VERSION ""

NS_ :

BS_:

BU_: WCM4 WCM3 WCM2 WCM VPM VLM VKM VICM VECM VDM VCU_RTOS_ETH VCU_ENTRY_ETH VCU_AGVM_ETH VCU UVM UPM TIM TEST_TOOL_1 TCP_ETH TCP TCM TCCM SRR_SRR_ETH SRR_SRR SRR_SLR_ETH SRR_SLR SRR_RR SRR_RF_ETH SRR_RF SRR_LR_CR SRR_LF_ETH SRR_LF SIB SDM SCL SBZA_R SBZA_L SBM SAM_RR SAM_RF SAM_LR SAM_LF SAM_BH SADS RadioLow_ETH RadioLow RSI_RTOS_ETH RSI RDCM PTM PLCM PFCM PDR_ETH PDR PCM PA ODS2 ODS NVM MTCM_R MTCM_L MSM_RR MSM_P MSM_LR MSM_D MSB2 MSB1 MRCM_R MRCM_L MFC LRR_RR_ETH LRR_LR_ETH LRR_CF_ETH LRR LRL_CF_ETH LIB_48V LIB1 IPC_INT IPC_GP IPC ICS_Info ICCM HVAC_FP_R HVAC_FP_F HUD_CAN HDLM FPI_RTOS_ETH FPI FOPM FCM_LC FCM EPSb EPS_1 EPSRAb EPSRAa EPS EOCM_HC_Superset EOCM_HCP2 EOCM ELM ECP_X1 ECP_S2 ECP_S ECP_MC ECP_H3 ECP_H2 ECP_H1 ECP_E ECM EBCM DMS DEFC DCM CSM_ETH CSM_AV CSM CGM_OTA_ETH CGM BSM_MH BSM_HEV BSM BCM ARS ARB APA AOS AMP ALC AHS AHL_AFL ADIMb ADIMa ACP2_MCU

BO_ 120 Tp_SrlDat186_Data_PDU: 2680 SRR_RR
 SG_ SRRRRODPREOTk1CrvAuth : 7|16@0- (9.77e-07,0) [-0.0320143|0.0320134] "1/m" Vector__XXX
 SG_ SRRRRODPREOTk1CrvDrvtAuth : 23|16@0- (3.73e-09,0) [-0.000122225|0.000122221] "1/m2" Vector__XXX
 SG_ SRRRRODPREOTk2CrvAuth : 39|16@0- (9.77e-07,0) [-0.0320143|0.0320134] "1/m" Vector__XXX
 SG_ SRRRRODPREOTk2CrvDrvtAuth : 55|16@0- (3.73e-09,0) [-0.000122225|0.000122221] "1/m2" Vector__XXX
 SG_ SRRRRODPREOTk3CrvAuth : 71|16@0- (9.77e-07,0) [-0.0320143|0.0320134] "1/m" Vector__XXX
 SG_ SRRRRODPREOTk3CrvDrvtAuth : 87|16@0- (3.73e-09,0) [-0.000122225|0.000122221] "1/m2" Vector__XXX
 SG_ SRRRRODPVOTk10PoILgPsCAuth : 103|16@0+ (0.01,0) [0|655.35] "m^2" Vector__XXX
 SG_ SRRRRODPVOTk1PoILgPsCAuth : 119|16@0+ (0.01,0) [0|655.35] "m^2" Vector__XXX
 SG_ SRRRRODPVOTk2PoILgPsCAuth : 135|16@0+ (0.01,0) [0|655.35] "m^2" Vector__XXX
 SG_ SRRRRODPVOTk3PoILgPsCAuth : 151|16@0+ (0.01,0) [0|655.35] "m^2" Vector__XXX
 SG_ SRRRRODPVOTk4PoILgPsCAuth : 167|16@0+ (0.01,0) [0|655.35] "m^2" Vector__XXX
 SG_ SRRRRODPVOTk5PoILgPsCAuth : 183|16@0+ (0.01,0) [0|655.35] "m^2" Vector__XXX
 SG_ SRRRRODPVOTk6PoILgPsCAuth : 199|16@0+ (0.01,0) [0|655.35] "m^2" Vector__XXX
 SG_ SRRRRODPVOTk7PoILgPsCAuth : 215|16@0+ (0.01,0) [0|655.35] "m^2" Vector__XXX
 SG_ SRRRRODPVOTk8PoILgPsCAuth : 231|16@0+ (0.01,0) [0|655.35] "m^2" Vector__XXX
 SG_ SRRRRODPVOTk9PoILgPsCAuth : 247|16@0+ (0.01,0) [0|655.35] "m^2" Vector__XXX
 SG_ SRRRRODPVOTk10PoILPsCAuth : 263|14@0+ (0.01,0) [0|163.83] "m^2" Vector__XXX
 SG_ SRRRRODPVOTk1PoILPsCAuth : 265|14@0+ (0.01,0) [0|163.83] "m^2" Vector__XXX
 SG_ SRRRRODPVOTk2PoILPsCAuth : 283|14@0+ (0.01,0) [0|163.83] "m^2" Vector__XXX
 SG_ SRRRRODPVOTk3PoILPsCAuth : 301|14@0+ (0.01,0) [0|163.83] "m^2" Vector__XXX
 SG_ SRRRRODPVOTk4PoILPsCAuth : 319|14@0+ (0.01,0) [0|163.83] "m^2" Vector__XXX
 SG_ SRRRRODPVOTk5PoILPsCAuth : 321|14@0+ (0.01,0) [0|163.83] "m^2" Vector__XXX
 SG_ SRRRRODPVOTk6PoILPsCAuth : 339|14@0+ (0.01,0) [0|163.83] "m^2" Vector__XXX
 SG_ SRRRRODPVOTk7PoILPsCAuth : 357|14@0+ (0.01,0) [0|163.83] "m^2" Vector__XXX
 SG_ SRRRRODPVOTk8PoILPsCAuth : 375|14@0+ (0.01,0) [0|163.83] "m^2" Vector__XXX
 SG_ SRRRRODPVOTk9PoILPsCAuth : 377|14@0+ (0.01,0) [0|163.83] "m^2" Vector__XXX
 SG_ SRRRRODPAcqTmStmAuth : 395|11@0+ (1,0) [0|2047] "ms" Vector__XXX
 SG_ SRRRRODPIOTk10PoILgPsAuth : 400|11@0- (0.125,0) [-128|127.875] "m" Vector__XXX
 SG_ SRRRRODPIOTk1PoILgPsAuth : 421|11@0- (0.125,0) [-128|127.875] "m" Vector__XXX
 SG_ SRRRRODPIOTk2PoILgPsAuth : 426|11@0- (0.125,0) [-128|127.875] "m" Vector__XXX
 SG_ SRRRRODPIOTk3PoILgPsAuth : 447|11@0- (0.125,0) [-128|127.875] "m" Vector__XXX
 SG_ SRRRRODPIOTk4PoILgPsAuth : 452|11@0- (0.125,0) [-128|127.875] "m" Vector__XXX
 SG_ SRRRRODPIOTk5PoILgPsAuth : 457|11@0- (0.125,0) [-128|127.875] "m" Vector__XXX
 SG_ SRRRRODPIOTk6PoILgPsAuth : 478|11@0- (0.125,0) [-128|127.875] "m" Vector__XXX
 SG_ SRRRRODPIOTk7PoILgPsAuth : 483|11@0- (0.125,0) [-128|127.875] "m" Vector__XXX
 SG_ SRRRRODPIOTk8PoILgPsAuth : 488|11@0- (0.125,0) [-128|127.875] "m" Vector__XXX
 SG_ SRRRRODPIOTk9PoILgPsAuth : 509|11@0- (0.125,0) [-128|127.875] "m" Vector__XXX
 SG_ SRRRRODPPOTk1PoILgPsAuth : 514|11@0- (0.125,0) [-128|127.875] "m" Vector__XXX
 SG_ SRRRRODPPOTk2PoILgPsAuth : 535|11@0- (0.125,0) [-128|127.875] "m" Vector__XXX
 SG_ SRRRRODPPOTk3PoILgPsAuth : 540|11@0- (0.125,0) [-128|127.875] "m" Vector__XXX
 SG_ SRRRRODPPOTk4PoILgPsAuth : 545|11@0- (0.125,0) [-128|127.875] "m" Vector__XXX
 SG_ SRRRRODPPOTk5PoILgPsAuth : 566|11@0- (0.125,0) [-128|127.875] "m" Vector__XXX
 SG_ SRRRRODPREOTk1PsEndAuth : 571|11@0- (0.125,0) [-128|127.875] "m" Vector__XXX
 SG_ SRRRRODPREOTk1PsStrtAuth : 576|11@0- (0.125,0) [-128|127.875] "m" Vector__XXX
 SG_ SRRRRODPREOTk2PsEndAuth : 597|11@0- (0.125,0) [-128|127.875] "m" Vector__XXX
 SG_ SRRRRODPREOTk2PsStrtAuth : 602|11@0- (0.125,0) [-128|127.875] "m" Vector__XXX
 SG_ SRRRRODPREOTk3PsEndAuth : 623|11@0- (0.125,0) [-128|127.875] "m" Vector__XXX
 SG_ SRRRRODPREOTk3PsStrtAuth : 628|11@0- (0.125,0) [-128|127.875] "m" Vector__XXX
 SG_ SRRRRODPVOTk10PoI2LgPsAuth : 633|11@0- (0.125,0) [-128|127.875] "m" Vector__XXX
 SG_ SRRRRODPVOTk10PoILgPsAuth : 654|11@0- (0.125,0) [-128|127.875] "m" Vector__XXX
 SG_ SRRRRODPVOTk10PoILgVAuth : 659|11@0- (0.125,0) [-128|127.875] "m/s" Vector__XXX
 SG_ SRRRRODPVOTk1PoI2LgPsAuth : 664|11@0- (0.125,0) [-128|127.875] "m" Vector__XXX
 SG_ SRRRRODPVOTk1PoILgPsAuth : 685|11@0- (0.125,0) [-128|127.875] "m" Vector__XXX
 SG_ SRRRRODPVOTk1PoILgVAuth : 690|11@0- (0.125,0) [-128|127.875] "m/s" Vector__XXX
 SG_ SRRRRODPVOTk2PoI2LgPsAuth : 711|11@0- (0.125,0) [-128|127.875] "m" Vector__XXX
 SG_ SRRRRODPVOTk2PoILgPsAuth : 716|11@0- (0.125,0) [-128|127.875] "m" Vector__XXX
 SG_ SRRRRODPVOTk2PoILgVAuth : 721|11@0- (0.125,0) [-128|127.875] "m/s" Vector__XXX
 SG_ SRRRRODPVOTk3PoI2LgPsAuth : 742|11@0- (0.125,0) [-128|127.875] "m" Vector__XXX
 SG_ SRRRRODPVOTk3PoILgPsAuth : 747|11@0- (0.125,0) [-128|127.875] "m" Vector__XXX
 SG_ SRRRRODPVOTk3PoILgVAuth : 752|11@0- (0.125,0) [-128|127.875] "m/s" Vector__XXX
 SG_ SRRRRODPVOTk4PoI2LgPsAuth : 773|11@0- (0.125,0) [-128|127.875] "m" Vector__XXX
 SG_ SRRRRODPVOTk4PoILgPsAuth : 778|11@0- (0.125,0) [-128|127.875] "m" Vector__XXX
 SG_ SRRRRODPVOTk4PoILgVAuth : 799|11@0- (0.125,0) [-128|127.875] "m/s" Vector__XXX
 SG_ SRRRRODPVOTk5PoI2LgPsAuth : 804|11@0- (0.125,0) [-128|127.875] "m" Vector__XXX
 SG_ SRRRRODPVOTk5PoILgPsAuth : 809|11@0- (0.125,0) [-128|127.875] "m" Vector__XXX
 SG_ SRRRRODPVOTk5PoILgVAuth : 830|11@0- (0.125,0) [-128|127.875] "m/s" Vector__XXX
 SG_ SRRRRODPVOTk6PoI2LgPsAuth : 835|11@0- (0.125,0) [-128|127.875] "m" Vector__XXX
 SG_ SRRRRODPVOTk6PoILgPsAuth : 840|11@0- (0.125,0) [-128|127.875] "m" Vector__XXX
 SG_ SRRRRODPVOTk6PoILgVAuth : 861|11@0- (0.125,0) [-128|127.875] "m/s" Vector__XXX
 SG_ SRRRRODPVOTk7PoI2LgPsAuth : 866|11@0- (0.125,0) [-128|127.875] "m" Vector__XXX
 SG_ SRRRRODPVOTk7PoILgPsAuth : 887|11@0- (0.125,0) [-128|127.875] "m" Vector__XXX
 SG_ SRRRRODPVOTk7PoILgVAuth : 892|11@0- (0.125,0) [-128|127.875] "m/s" Vector__XXX
 SG_ SRRRRODPVOTk8PoI2LgPsAuth : 897|11@0- (0.125,0) [-128|127.875] "m" Vector__XXX
 SG_ SRRRRODPVOTk8PoILgPsAuth : 918|11@0- (0.125,0) [-128|127.875] "m" Vector__XXX
 SG_ SRRRRODPVOTk8PoILgVAuth : 923|11@0- (0.125,0) [-128|127.875] "m/s" Vector__XXX
 SG_ SRRRRODPVOTk9PoI2LgPsAuth : 928|11@0- (0.125,0) [-128|127.875] "m" Vector__XXX
 SG_ SRRRRODPVOTk9PoILgPsAuth : 949|11@0- (0.125,0) [-128|127.875] "m" Vector__XXX
 SG_ SRRRRODPVOTk9PoILgVAuth : 954|11@0- (0.125,0) [-128|127.875] "m/s" Vector__XXX
 SG_ SRRRRODPIOTk10PoILPsAuth : 975|10@0- (0.125,0) [-64|63.875] "m" Vector__XXX
 SG_ SRRRRODPIOTk1PoILPsAuth : 981|10@0- (0.125,0) [-64|63.875] "m" Vector__XXX
 SG_ SRRRRODPIOTk2PoILPsAuth : 987|10@0- (0.125,0) [-64|63.875] "m" Vector__XXX
 SG_ SRRRRODPIOTk3PoILPsAuth : 993|10@0- (0.125,0) [-64|63.875] "m" Vector__XXX
 SG_ SRRRRODPIOTk4PoILPsAuth : 1015|10@0- (0.125,0) [-64|63.875] "m" Vector__XXX
 SG_ SRRRRODPIOTk5PoILPsAuth : 1021|10@0- (0.125,0) [-64|63.875] "m" Vector__XXX
 SG_ SRRRRODPIOTk6PoILPsAuth : 1027|10@0- (0.125,0) [-64|63.875] "m" Vector__XXX
 SG_ SRRRRODPIOTk7PoILPsAuth : 1033|10@0- (0.125,0) [-64|63.875] "m" Vector__XXX
 SG_ SRRRRODPIOTk8PoILPsAuth : 1055|10@0- (0.125,0) [-64|63.875] "m" Vector__XXX
 SG_ SRRRRODPIOTk9PoILPsAuth : 1061|10@0- (0.125,0) [-64|63.875] "m" Vector__XXX
 SG_ SRRRRODPPOTk1PoILPsAuth : 1067|10@0- (0.125,0) [-64|63.875] "m" Vector__XXX
 SG_ SRRRRODPPOTk1PoILgVAuth : 1073|10@0- (0.125,0) [-64|63.875] "m/s" Vector__XXX
 SG_ SRRRRODPPOTk2PoILPsAuth : 1095|10@0- (0.125,0) [-64|63.875] "m" Vector__XXX
 SG_ SRRRRODPPOTk2PoILgVAuth : 1101|10@0- (0.125,0) [-64|63.875] "m/s" Vector__XXX
 SG_ SRRRRODPPOTk3PoILPsAuth : 1107|10@0- (0.125,0) [-64|63.875] "m" Vector__XXX
 SG_ SRRRRODPPOTk3PoILgVAuth : 1113|10@0- (0.125,0) [-64|63.875] "m/s" Vector__XXX
 SG_ SRRRRODPPOTk4PoILPsAuth : 1135|10@0- (0.125,0) [-64|63.875] "m" Vector__XXX
 SG_ SRRRRODPPOTk4PoILgVAuth : 1141|10@0- (0.125,0) [-64|63.875] "m/s" Vector__XXX
 SG_ SRRRRODPPOTk5PoILPsAuth : 1147|10@0- (0.125,0) [-64|63.875] "m" Vector__XXX
 SG_ SRRRRODPPOTk5PoILgVAuth : 1153|10@0- (0.125,0) [-64|63.875] "m/s" Vector__XXX
 SG_ SRRRRODPREOTk1HdgAuth : 1175|10@0- (0.000977,0) [-0.500224|0.499247] "rad" Vector__XXX
 SG_ SRRRRODPREOTk2HdgAuth : 1181|10@0- (0.000977,0) [-0.500224|0.499247] "rad" Vector__XXX
 SG_ SRRRRODPREOTk3HdgAuth : 1187|10@0- (0.000977,0) [-0.500224|0.499247] "rad" Vector__XXX
 SG_ SRRRRODPVOTk10PoI2LPsAuth : 1193|10@0- (0.125,0) [-64|63.875] "m" Vector__XXX
 SG_ SRRRRODPVOTk10PoILPsAuth : 1215|10@0- (0.125,0) [-64|63.875] "m" Vector__XXX
 SG_ SRRRRODPVOTk10PoILVCAuth : 1221|10@0+ (0.125,0) [0|127.875] "(m/s)^2" Vector__XXX
 SG_ SRRRRODPVOTk10PoILgVCAuth : 1227|10@0+ (0.125,0) [0|127.875] "(m/s)^2" Vector__XXX
 SG_ SRRRRODPVOTk1PoI2LPsAuth : 1233|10@0- (0.125,0) [-64|63.875] "m" Vector__XXX
 SG_ SRRRRODPVOTk1PoILPsAuth : 1255|10@0- (0.125,0) [-64|63.875] "m" Vector__XXX
 SG_ SRRRRODPVOTk1PoILVCAuth : 1261|10@0+ (0.125,0) [0|127.875] "(m/s)^2" Vector__XXX
 SG_ SRRRRODPVOTk1PoILgVCAuth : 1267|10@0+ (0.125,0) [0|127.875] "(m/s)^2" Vector__XXX
 SG_ SRRRRODPVOTk2PoI2LPsAuth : 1273|10@0- (0.125,0) [-64|63.875] "m" Vector__XXX
 SG_ SRRRRODPVOTk2PoILPsAuth : 1295|10@0- (0.125,0) [-64|63.875] "m" Vector__XXX
 SG_ SRRRRODPVOTk2PoILVCAuth : 1301|10@0+ (0.125,0) [0|127.875] "(m/s)^2" Vector__XXX
 SG_ SRRRRODPVOTk2PoILgVCAuth : 1307|10@0+ (0.125,0) [0|127.875] "(m/s)^2" Vector__XXX
 SG_ SRRRRODPVOTk3PoI2LPsAuth : 1313|10@0- (0.125,0) [-64|63.875] "m" Vector__XXX
 SG_ SRRRRODPVOTk3PoILPsAuth : 1335|10@0- (0.125,0) [-64|63.875] "m" Vector__XXX
 SG_ SRRRRODPVOTk3PoILVCAuth : 1341|10@0+ (0.125,0) [0|127.875] "(m/s)^2" Vector__XXX
 SG_ SRRRRODPVOTk3PoILgVCAuth : 1347|10@0+ (0.125,0) [0|127.875] "(m/s)^2" Vector__XXX
 SG_ SRRRRODPVOTk4PoI2LPsAuth : 1353|10@0- (0.125,0) [-64|63.875] "m" Vector__XXX
 SG_ SRRRRODPVOTk4PoILPsAuth : 1375|10@0- (0.125,0) [-64|63.875] "m" Vector__XXX
 SG_ SRRRRODPVOTk4PoILVCAuth : 1381|10@0+ (0.125,0) [0|127.875] "(m/s)^2" Vector__XXX
 SG_ SRRRRODPVOTk4PoILgVCAuth : 1387|10@0+ (0.125,0) [0|127.875] "(m/s)^2" Vector__XXX
 SG_ SRRRRODPVOTk5PoI2LPsAuth : 1393|10@0- (0.125,0) [-64|63.875] "m" Vector__XXX
 SG_ SRRRRODPVOTk5PoILPsAuth : 1415|10@0- (0.125,0) [-64|63.875] "m" Vector__XXX
 SG_ SRRRRODPVOTk5PoILVCAuth : 1421|10@0+ (0.125,0) [0|127.875] "(m/s)^2" Vector__XXX
 SG_ SRRRRODPVOTk5PoILgVCAuth : 1427|10@0+ (0.125,0) [0|127.875] "(m/s)^2" Vector__XXX
 SG_ SRRRRODPVOTk6PoI2LPsAuth : 1433|10@0- (0.125,0) [-64|63.875] "m" Vector__XXX
 SG_ SRRRRODPVOTk6PoILPsAuth : 1455|10@0- (0.125,0) [-64|63.875] "m" Vector__XXX
 SG_ SRRRRODPVOTk6PoILVCAuth : 1461|10@0+ (0.125,0) [0|127.875] "(m/s)^2" Vector__XXX
 SG_ SRRRRODPVOTk6PoILgVCAuth : 1467|10@0+ (0.125,0) [0|127.875] "(m/s)^2" Vector__XXX
 SG_ SRRRRODPVOTk7PoI2LPsAuth : 1473|10@0- (0.125,0) [-64|63.875] "m" Vector__XXX
 SG_ SRRRRODPVOTk7PoILPsAuth : 1495|10@0- (0.125,0) [-64|63.875] "m" Vector__XXX
 SG_ SRRRRODPVOTk7PoILVCAuth : 1501|10@0+ (0.125,0) [0|127.875] "(m/s)^2" Vector__XXX
 SG_ SRRRRODPVOTk7PoILgVCAuth : 1507|10@0+ (0.125,0) [0|127.875] "(m/s)^2" Vector__XXX
 SG_ SRRRRODPVOTk8PoI2LPsAuth : 1513|10@0- (0.125,0) [-64|63.875] "m" Vector__XXX
 SG_ SRRRRODPVOTk8PoILPsAuth : 1535|10@0- (0.125,0) [-64|63.875] "m" Vector__XXX
 SG_ SRRRRODPVOTk8PoILVCAuth : 1541|10@0+ (0.125,0) [0|127.875] "(m/s)^2" Vector__XXX
 SG_ SRRRRODPVOTk8PoILgVCAuth : 1547|10@0+ (0.125,0) [0|127.875] "(m/s)^2" Vector__XXX
 SG_ SRRRRODPVOTk9PoI2LPsAuth : 1553|10@0- (0.125,0) [-64|63.875] "m" Vector__XXX
 SG_ SRRRRODPVOTk9PoILPsAuth : 1575|10@0- (0.125,0) [-64|63.875] "m" Vector__XXX
 SG_ SRRRRODPVOTk9PoILVCAuth : 1581|10@0+ (0.125,0) [0|127.875] "(m/s)^2" Vector__XXX
 SG_ SRRRRODPVOTk9PoILgVCAuth : 1587|10@0+ (0.125,0) [0|127.875] "(m/s)^2" Vector__XXX
 SG_ SRRRRODPPOTk1PoILAAuth : 1593|9@0- (0.125,0) [-32|31.875] "m/s^2" Vector__XXX
 SG_ SRRRRODPPOTk1PoILVAuth : 1600|9@0- (0.125,0) [-32|31.875] "m/s" Vector__XXX
 SG_ SRRRRODPPOTk1PoILgAAuth : 1623|9@0- (0.125,0) [-32|31.875] "m/s^2" Vector__XXX
 SG_ SRRRRODPPOTk2PoILAAuth : 1630|9@0- (0.125,0) [-32|31.875] "m/s^2" Vector__XXX
 SG_ SRRRRODPPOTk2PoILVAuth : 1637|9@0- (0.125,0) [-32|31.875] "m/s" Vector__XXX
 SG_ SRRRRODPPOTk2PoILgAAuth : 1644|9@0- (0.125,0) [-32|31.875] "m/s^2" Vector__XXX
 SG_ SRRRRODPPOTk3PoILAAuth : 1651|9@0- (0.125,0) [-32|31.875] "m/s^2" Vector__XXX
 SG_ SRRRRODPPOTk3PoILVAuth : 1658|9@0- (0.125,0) [-32|31.875] "m/s" Vector__XXX
 SG_ SRRRRODPPOTk3PoILgAAuth : 1665|9@0- (0.125,0) [-32|31.875] "m/s^2" Vector__XXX
 SG_ SRRRRODPPOTk4PoILAAuth : 1672|9@0- (0.125,0) [-32|31.875] "m/s^2" Vector__XXX
 SG_ SRRRRODPPOTk4PoILVAuth : 1695|9@0- (0.125,0) [-32|31.875] "m/s" Vector__XXX
 SG_ SRRRRODPPOTk4PoILgAAuth : 1702|9@0- (0.125,0) [-32|31.875] "m/s^2" Vector__XXX
 SG_ SRRRRODPPOTk5PoILAAuth : 1709|9@0- (0.125,0) [-32|31.875] "m/s^2" Vector__XXX
 SG_ SRRRRODPPOTk5PoILVAuth : 1716|9@0- (0.125,0) [-32|31.875] "m/s" Vector__XXX
 SG_ SRRRRODPPOTk5PoILgAAuth : 1723|9@0- (0.125,0) [-32|31.875] "m/s^2" Vector__XXX
 SG_ SRRRRODPREOTk1OfstAuth : 1730|9@0- (0.125,0) [-32|31.875] "m" Vector__XXX
 SG_ SRRRRODPREOTk2OfstAuth : 1737|9@0- (0.125,0) [-32|31.875] "m" Vector__XXX
 SG_ SRRRRODPREOTk3OfstAuth : 1744|9@0- (0.125,0) [-32|31.875] "m" Vector__XXX
 SG_ SRRRRODPVOTk10PoILAAuth : 1767|9@0- (0.125,0) [-32|31.875] "m/s^2" Vector__XXX
 SG_ SRRRRODPVOTk10PoILVAuth : 1774|9@0- (0.125,0) [-32|31.875] "m/s" Vector__XXX
 SG_ SRRRRODPVOTk10PoILgAAuth : 1781|9@0- (0.125,0) [-32|31.875] "m/s^2" Vector__XXX
 SG_ SRRRRODPVOTk1PoILAAuth : 1788|9@0- (0.125,0) [-32|31.875] "m/s^2" Vector__XXX
 SG_ SRRRRODPVOTk1PoILVAuth : 1795|9@0- (0.125,0) [-32|31.875] "m/s" Vector__XXX
 SG_ SRRRRODPVOTk1PoILgAAuth : 1802|9@0- (0.125,0) [-32|31.875] "m/s^2" Vector__XXX
 SG_ SRRRRODPVOTk2PoILAAuth : 1809|9@0- (0.125,0) [-32|31.875] "m/s^2" Vector__XXX
 SG_ SRRRRODPVOTk2PoILVAuth : 1816|9@0- (0.125,0) [-32|31.875] "m/s" Vector__XXX
 SG_ SRRRRODPVOTk2PoILgAAuth : 1839|9@0- (0.125,0) [-32|31.875] "m/s^2" Vector__XXX
 SG_ SRRRRODPVOTk3PoILAAuth : 1846|9@0- (0.125,0) [-32|31.875] "m/s^2" Vector__XXX
 SG_ SRRRRODPVOTk3PoILVAuth : 1853|9@0- (0.125,0) [-32|31.875] "m/s" Vector__XXX
 SG_ SRRRRODPVOTk3PoILgAAuth : 1860|9@0- (0.125,0) [-32|31.875] "m/s^2" Vector__XXX
 SG_ SRRRRODPVOTk4PoILAAuth : 1867|9@0- (0.125,0) [-32|31.875] "m/s^2" Vector__XXX
 SG_ SRRRRODPVOTk4PoILVAuth : 1874|9@0- (0.125,0) [-32|31.875] "m/s" Vector__XXX
 SG_ SRRRRODPVOTk4PoILgAAuth : 1881|9@0- (0.125,0) [-32|31.875] "m/s^2" Vector__XXX
 SG_ SRRRRODPVOTk5PoILAAuth : 1888|9@0- (0.125,0) [-32|31.875] "m/s^2" Vector__XXX
 SG_ SRRRRODPVOTk5PoILVAuth : 1911|9@0- (0.125,0) [-32|31.875] "m/s" Vector__XXX
 SG_ SRRRRODPVOTk5PoILgAAuth : 1918|9@0- (0.125,0) [-32|31.875] "m/s^2" Vector__XXX
 SG_ SRRRRODPVOTk6PoILAAuth : 1925|9@0- (0.125,0) [-32|31.875] "m/s^2" Vector__XXX
 SG_ SRRRRODPVOTk6PoILVAuth : 1932|9@0- (0.125,0) [-32|31.875] "m/s" Vector__XXX
 SG_ SRRRRODPVOTk6PoILgAAuth : 1939|9@0- (0.125,0) [-32|31.875] "m/s^2" Vector__XXX
 SG_ SRRRRODPVOTk7PoILAAuth : 1946|9@0- (0.125,0) [-32|31.875] "m/s^2" Vector__XXX
 SG_ SRRRRODPVOTk7PoILVAuth : 1953|9@0- (0.125,0) [-32|31.875] "m/s" Vector__XXX
 SG_ SRRRRODPVOTk7PoILgAAuth : 1960|9@0- (0.125,0) [-32|31.875] "m/s^2" Vector__XXX
 SG_ SRRRRODPVOTk8PoILAAuth : 1983|9@0- (0.125,0) [-32|31.875] "m/s^2" Vector__XXX
 SG_ SRRRRODPVOTk8PoILVAuth : 1990|9@0- (0.125,0) [-32|31.875] "m/s" Vector__XXX
 SG_ SRRRRODPVOTk8PoILgAAuth : 1997|9@0- (0.125,0) [-32|31.875] "m/s^2" Vector__XXX
 SG_ SRRRRODPVOTk9PoILAAuth : 2004|9@0- (0.125,0) [-32|31.875] "m/s^2" Vector__XXX
 SG_ SRRRRODPVOTk9PoILVAuth : 2011|9@0- (0.125,0) [-32|31.875] "m/s" Vector__XXX
 SG_ SRRRRODPVOTk9PoILgAAuth : 2018|9@0- (0.125,0) [-32|31.875] "m/s^2" Vector__XXX
 SG_ SRRRRODPVOTk10PoILgthAuth : 2025|8@0+ (0.125,0) [0|31.875] "m" Vector__XXX
 SG_ SRRRRODPVOTk1PoILgthAuth : 2033|8@0+ (0.125,0) [0|31.875] "m" Vector__XXX
 SG_ SRRRRODPVOTk2PoILgthAuth : 2041|8@0+ (0.125,0) [0|31.875] "m" Vector__XXX
 SG_ SRRRRODPVOTk3PoILgthAuth : 2049|8@0+ (0.125,0) [0|31.875] "m" Vector__XXX
 SG_ SRRRRODPVOTk4PoILgthAuth : 2057|8@0+ (0.125,0) [0|31.875] "m" Vector__XXX
 SG_ SRRRRODPVOTk5PoILgthAuth : 2065|8@0+ (0.125,0) [0|31.875] "m" Vector__XXX
 SG_ SRRRRODPVOTk6PoILgthAuth : 2073|8@0+ (0.125,0) [0|31.875] "m" Vector__XXX
 SG_ SRRRRODPVOTk7PoILgthAuth : 2081|8@0+ (0.125,0) [0|31.875] "m" Vector__XXX
 SG_ SRRRRODPVOTk8PoILgthAuth : 2089|8@0+ (0.125,0) [0|31.875] "m" Vector__XXX
 SG_ SRRRRODPVOTk9PoILgthAuth : 2097|8@0+ (0.125,0) [0|31.875] "m" Vector__XXX
 SG_ SRRRRODPIOTk10IDAuth : 2105|7@0+ (1,0) [0|127] "" Vector__XXX
 SG_ SRRRRODPIOTk1IDAuth : 2114|7@0+ (1,0) [0|127] "" Vector__XXX
 SG_ SRRRRODPIOTk2IDAuth : 2123|7@0+ (1,0) [0|127] "" Vector__XXX
 SG_ SRRRRODPIOTk3IDAuth : 2132|7@0+ (1,0) [0|127] "" Vector__XXX
 SG_ SRRRRODPIOTk4IDAuth : 2141|7@0+ (1,0) [0|127] "" Vector__XXX
 SG_ SRRRRODPIOTk5IDAuth : 2150|7@0+ (1,0) [0|127] "" Vector__XXX
 SG_ SRRRRODPIOTk6IDAuth : 2159|7@0+ (1,0) [0|127] "" Vector__XXX
 SG_ SRRRRODPIOTk7IDAuth : 2152|7@0+ (1,0) [0|127] "" Vector__XXX
 SG_ SRRRRODPIOTk8IDAuth : 2161|7@0+ (1,0) [0|127] "" Vector__XXX
 SG_ SRRRRODPIOTk9IDAuth : 2170|7@0+ (1,0) [0|127] "" Vector__XXX
 SG_ SRRRRODPPOTk1IDAuth : 2179|7@0+ (1,0) [0|127] "" Vector__XXX
 SG_ SRRRRODPPOTk2IDAuth : 2188|7@0+ (1,0) [0|127] "" Vector__XXX
 SG_ SRRRRODPPOTk3IDAuth : 2197|7@0+ (1,0) [0|127] "" Vector__XXX
 SG_ SRRRRODPPOTk4IDAuth : 2206|7@0+ (1,0) [0|127] "" Vector__XXX
 SG_ SRRRRODPPOTk5IDAuth : 2215|7@0+ (1,0) [0|127] "" Vector__XXX
 SG_ SRRRRODPVOTk10IDAuth : 2208|7@0+ (1,0) [0|127] "" Vector__XXX
 SG_ SRRRRODPVOTk1IDAuth : 2217|7@0+ (1,0) [0|127] "" Vector__XXX
 SG_ SRRRRODPVOTk2IDAuth : 2226|7@0+ (1,0) [0|127] "" Vector__XXX
 SG_ SRRRRODPVOTk3IDAuth : 2235|7@0+ (1,0) [0|127] "" Vector__XXX
 SG_ SRRRRODPVOTk4IDAuth : 2244|7@0+ (1,0) [0|127] "" Vector__XXX
 SG_ SRRRRODPVOTk5IDAuth : 2253|7@0+ (1,0) [0|127] "" Vector__XXX
 SG_ SRRRRODPVOTk6IDAuth : 2262|7@0+ (1,0) [0|127] "" Vector__XXX
 SG_ SRRRRODPVOTk7IDAuth : 2271|7@0+ (1,0) [0|127] "" Vector__XXX
 SG_ SRRRRODPVOTk8IDAuth : 2264|7@0+ (1,0) [0|127] "" Vector__XXX
 SG_ SRRRRODPVOTk9IDAuth : 2273|7@0+ (1,0) [0|127] "" Vector__XXX
 SG_ SRRRRODPPOTk1InPthPotAuth : 2282|6@0+ (2,0) [0|126] "%" Vector__XXX
 SG_ SRRRRODPPOTk2InPthPotAuth : 2292|6@0+ (2,0) [0|126] "%" Vector__XXX
 SG_ SRRRRODPPOTk3InPthPotAuth : 2302|6@0+ (2,0) [0|126] "%" Vector__XXX
 SG_ SRRRRODPPOTk4InPthPotAuth : 2296|6@0+ (2,0) [0|126] "%" Vector__XXX
 SG_ SRRRRODPPOTk5InPthPotAuth : 2306|6@0+ (2,0) [0|126] "%" Vector__XXX
 SG_ SRRRRODPVOTk10CICOPotAuth : 2316|6@0+ (2,0) [0|126] "%" Vector__XXX
 SG_ SRRRRODPVOTk1CICOPotAuth : 2326|6@0+ (2,0) [0|126] "%" Vector__XXX
 SG_ SRRRRODPVOTk2CICOPotAuth : 2320|6@0+ (2,0) [0|126] "%" Vector__XXX
 SG_ SRRRRODPVOTk3CICOPotAuth : 2330|6@0+ (2,0) [0|126] "%" Vector__XXX
 SG_ SRRRRODPVOTk4CICOPotAuth : 2340|6@0+ (2,0) [0|126] "%" Vector__XXX
 SG_ SRRRRODPVOTk5CICOPotAuth : 2350|6@0+ (2,0) [0|126] "%" Vector__XXX
 SG_ SRRRRODPVOTk6CICOPotAuth : 2344|6@0+ (2,0) [0|126] "%" Vector__XXX
 SG_ SRRRRODPVOTk7CICOPotAuth : 2354|6@0+ (2,0) [0|126] "%" Vector__XXX
 SG_ SRRRRODPVOTk8CICOPotAuth : 2364|6@0+ (2,0) [0|126] "%" Vector__XXX
 SG_ SRRRRODPVOTk9CICOPotAuth : 2374|6@0+ (2,0) [0|126] "%" Vector__XXX
 SG_ SRRRRODPIOTk10TypAuth : 2368|3@0+ (1,0) [0|5] "" Vector__XXX
 SG_ SRRRRODPIOTk1TypAuth : 2381|3@0+ (1,0) [0|5] "" Vector__XXX
 SG_ SRRRRODPIOTk2TypAuth : 2378|3@0+ (1,0) [0|5] "" Vector__XXX
 SG_ SRRRRODPIOTk3TypAuth : 2391|3@0+ (1,0) [0|5] "" Vector__XXX
 SG_ SRRRRODPIOTk4TypAuth : 2388|3@0+ (1,0) [0|5] "" Vector__XXX
 SG_ SRRRRODPIOTk5TypAuth : 2385|3@0+ (1,0) [0|5] "" Vector__XXX
 SG_ SRRRRODPIOTk6TypAuth : 2398|3@0+ (1,0) [0|5] "" Vector__XXX
 SG_ SRRRRODPIOTk7TypAuth : 2395|3@0+ (1,0) [0|5] "" Vector__XXX
 SG_ SRRRRODPIOTk8TypAuth : 2392|3@0+ (1,0) [0|5] "" Vector__XXX
 SG_ SRRRRODPIOTk9TypAuth : 2405|3@0+ (1,0) [0|5] "" Vector__XXX
 SG_ SRRRRODPPOTk1DynPrpAuth : 2402|3@0+ (1,0) [0|4] "" Vector__XXX
 SG_ SRRRRODPPOTk2DynPrpAuth : 2415|3@0+ (1,0) [0|4] "" Vector__XXX
 SG_ SRRRRODPPOTk3DynPrpAuth : 2412|3@0+ (1,0) [0|4] "" Vector__XXX
 SG_ SRRRRODPPOTk4DynPrpAuth : 2409|3@0+ (1,0) [0|4] "" Vector__XXX
 SG_ SRRRRODPPOTk5DynPrpAuth : 2422|3@0+ (1,0) [0|4] "" Vector__XXX
 SG_ SRRRRODPREOTk1TypAuth : 2419|3@0+ (1,0) [0|5] "" Vector__XXX
 SG_ SRRRRODPREOTk2TypAuth : 2416|3@0+ (1,0) [0|5] "" Vector__XXX
 SG_ SRRRRODPREOTk3TypAuth : 2429|3@0+ (1,0) [0|5] "" Vector__XXX
 SG_ SRRRRODPRdTypAuth : 2426|3@0+ (1,0) [0|5] "" Vector__XXX
 SG_ SRRRRODPVOTk10DynPrpAuth : 2439|3@0+ (1,0) [0|4] "" Vector__XXX
 SG_ SRRRRODPVOTk1DynPrpAuth : 2436|3@0+ (1,0) [0|4] "" Vector__XXX
 SG_ SRRRRODPVOTk2DynPrpAuth : 2433|3@0+ (1,0) [0|4] "" Vector__XXX
 SG_ SRRRRODPVOTk3DynPrpAuth : 2446|3@0+ (1,0) [0|4] "" Vector__XXX
 SG_ SRRRRODPVOTk4DynPrpAuth : 2443|3@0+ (1,0) [0|4] "" Vector__XXX
 SG_ SRRRRODPVOTk5DynPrpAuth : 2440|3@0+ (1,0) [0|4] "" Vector__XXX
 SG_ SRRRRODPVOTk6DynPrpAuth : 2453|3@0+ (1,0) [0|4] "" Vector__XXX
 SG_ SRRRRODPVOTk7DynPrpAuth : 2450|3@0+ (1,0) [0|4] "" Vector__XXX
 SG_ SRRRRODPVOTk8DynPrpAuth : 2463|3@0+ (1,0) [0|4] "" Vector__XXX
 SG_ SRRRRODPVOTk9DynPrpAuth : 2460|3@0+ (1,0) [0|4] "" Vector__XXX
 SG_ SRRRRODPConstrArDtnCnfdAuth : 2457|2@0+ (1,0) [0|3] "" Vector__XXX
 SG_ SRRRRODPConstrArDtnStsAuth : 2471|2@0+ (1,0) [0|2] "" Vector__XXX
 SG_ SRRRRODPIOTk10CnfdStsAuth : 2469|2@0+ (1,0) [0|3] "" Vector__XXX
 SG_ SRRRRODPIOTk10ElvtnAuth : 2467|2@0+ (1,0) [0|3] "" Vector__XXX
 SG_ SRRRRODPIOTk10MStsAuth : 2465|2@0+ (1,0) [0|3] "" Vector__XXX
 SG_ SRRRRODPIOTk10TypCnfdAuth : 2479|2@0+ (1,0) [0|3] "" Vector__XXX
 SG_ SRRRRODPIOTk1CnfdStsAuth : 2477|2@0+ (1,0) [0|3] "" Vector__XXX
 SG_ SRRRRODPIOTk1ElvtnAuth : 2475|2@0+ (1,0) [0|3] "" Vector__XXX
 SG_ SRRRRODPIOTk1MStsAuth : 2473|2@0+ (1,0) [0|3] "" Vector__XXX
 SG_ SRRRRODPIOTk1TypCnfdAuth : 2487|2@0+ (1,0) [0|3] "" Vector__XXX
 SG_ SRRRRODPIOTk2CnfdStsAuth : 2485|2@0+ (1,0) [0|3] "" Vector__XXX
 SG_ SRRRRODPIOTk2ElvtnAuth : 2483|2@0+ (1,0) [0|3] "" Vector__XXX
 SG_ SRRRRODPIOTk2MStsAuth : 2481|2@0+ (1,0) [0|3] "" Vector__XXX
 SG_ SRRRRODPIOTk2TypCnfdAuth : 2495|2@0+ (1,0) [0|3] "" Vector__XXX
 SG_ SRRRRODPIOTk3CnfdStsAuth : 2493|2@0+ (1,0) [0|3] "" Vector__XXX
 SG_ SRRRRODPIOTk3ElvtnAuth : 2491|2@0+ (1,0) [0|3] "" Vector__XXX
 SG_ SRRRRODPIOTk3MStsAuth : 2489|2@0+ (1,0) [0|3] "" Vector__XXX
 SG_ SRRRRODPIOTk3TypCnfdAuth : 2503|2@0+ (1,0) [0|3] "" Vector__XXX
 SG_ SRRRRODPIOTk4CnfdStsAuth : 2501|2@0+ (1,0) [0|3] "" Vector__XXX
 SG_ SRRRRODPIOTk4ElvtnAuth : 2499|2@0+ (1,0) [0|3] "" Vector__XXX
 SG_ SRRRRODPIOTk4MStsAuth : 2497|2@0+ (1,0) [0|3] "" Vector__XXX
 SG_ SRRRRODPIOTk4TypCnfdAuth : 2511|2@0+ (1,0) [0|3] "" Vector__XXX
 SG_ SRRRRODPIOTk5CnfdStsAuth : 2509|2@0+ (1,0) [0|3] "" Vector__XXX
 SG_ SRRRRODPIOTk5ElvtnAuth : 2507|2@0+ (1,0) [0|3] "" Vector__XXX
 SG_ SRRRRODPIOTk5MStsAuth : 2505|2@0+ (1,0) [0|3] "" Vector__XXX
 SG_ SRRRRODPIOTk5TypCnfdAuth : 2519|2@0+ (1,0) [0|3] "" Vector__XXX
 SG_ SRRRRODPIOTk6CnfdStsAuth : 2517|2@0+ (1,0) [0|3] "" Vector__XXX
 SG_ SRRRRODPIOTk6ElvtnAuth : 2515|2@0+ (1,0) [0|3] "" Vector__XXX
 SG_ SRRRRODPIOTk6MStsAuth : 2513|2@0+ (1,0) [0|3] "" Vector__XXX
 SG_ SRRRRODPIOTk6TypCnfdAuth : 2527|2@0+ (1,0) [0|3] "" Vector__XXX
 SG_ SRRRRODPIOTk7CnfdStsAuth : 2525|2@0+ (1,0) [0|3] "" Vector__XXX
 SG_ SRRRRODPIOTk7ElvtnAuth : 2523|2@0+ (1,0) [0|3] "" Vector__XXX
 SG_ SRRRRODPIOTk7MStsAuth : 2521|2@0+ (1,0) [0|3] "" Vector__XXX
 SG_ SRRRRODPIOTk7TypCnfdAuth : 2535|2@0+ (1,0) [0|3] "" Vector__XXX
 SG_ SRRRRODPIOTk8CnfdStsAuth : 2533|2@0+ (1,0) [0|3] "" Vector__XXX
 SG_ SRRRRODPIOTk8ElvtnAuth : 2531|2@0+ (1,0) [0|3] "" Vector__XXX
 SG_ SRRRRODPIOTk8MStsAuth : 2529|2@0+ (1,0) [0|3] "" Vector__XXX
 SG_ SRRRRODPIOTk8TypCnfdAuth : 2543|2@0+ (1,0) [0|3] "" Vector__XXX
 SG_ SRRRRODPIOTk9CnfdStsAuth : 2541|2@0+ (1,0) [0|3] "" Vector__XXX
 SG_ SRRRRODPIOTk9ElvtnAuth : 2539|2@0+ (1,0) [0|3] "" Vector__XXX
 SG_ SRRRRODPIOTk9MStsAuth : 2537|2@0+ (1,0) [0|3] "" Vector__XXX
 SG_ SRRRRODPIOTk9TypCnfdAuth : 2551|2@0+ (1,0) [0|3] "" Vector__XXX
 SG_ SRRRRODPMdCmdStsAuth : 2549|2@0+ (1,0) [0|2] "" Vector__XXX
 SG_ SRRRRODPPOTk1CnfdStsAuth : 2547|2@0+ (1,0) [0|3] "" Vector__XXX
 SG_ SRRRRODPPOTk1MStsAuth : 2545|2@0+ (1,0) [0|3] "" Vector__XXX
 SG_ SRRRRODPPOTk1TypAuth : 2559|2@0+ (1,0) [0|2] "" Vector__XXX
 SG_ SRRRRODPPOTk1TypCnfdAuth : 2557|2@0+ (1,0) [0|3] "" Vector__XXX
 SG_ SRRRRODPPOTk2CnfdStsAuth : 2555|2@0+ (1,0) [0|3] "" Vector__XXX
 SG_ SRRRRODPPOTk2MStsAuth : 2553|2@0+ (1,0) [0|3] "" Vector__XXX
 SG_ SRRRRODPPOTk2TypAuth : 2567|2@0+ (1,0) [0|2] "" Vector__XXX
 SG_ SRRRRODPPOTk2TypCnfdAuth : 2565|2@0+ (1,0) [0|3] "" Vector__XXX
 SG_ SRRRRODPPOTk3CnfdStsAuth : 2563|2@0+ (1,0) [0|3] "" Vector__XXX
 SG_ SRRRRODPPOTk3MStsAuth : 2561|2@0+ (1,0) [0|3] "" Vector__XXX
 SG_ SRRRRODPPOTk3TypAuth : 2575|2@0+ (1,0) [0|2] "" Vector__XXX
 SG_ SRRRRODPPOTk3TypCnfdAuth : 2573|2@0+ (1,0) [0|3] "" Vector__XXX
 SG_ SRRRRODPPOTk4CnfdStsAuth : 2571|2@0+ (1,0) [0|3] "" Vector__XXX
 SG_ SRRRRODPPOTk4MStsAuth : 2569|2@0+ (1,0) [0|3] "" Vector__XXX
 SG_ SRRRRODPPOTk4TypAuth : 2583|2@0+ (1,0) [0|2] "" Vector__XXX
 SG_ SRRRRODPPOTk4TypCnfdAuth : 2581|2@0+ (1,0) [0|3] "" Vector__XXX
 SG_ SRRRRODPPOTk5CnfdStsAuth : 2579|2@0+ (1,0) [0|3] "" Vector__XXX
 SG_ SRRRRODPPOTk5MStsAuth : 2577|2@0+ (1,0) [0|3] "" Vector__XXX
 SG_ SRRRRODPPOTk5TypAuth : 2591|2@0+ (1,0) [0|2] "" Vector__XXX
 SG_ SRRRRODPPOTk5TypCnfdAuth : 2589|2@0+ (1,0) [0|3] "" Vector__XXX
 SG_ SRRRRODPREOTk1CnfdStsAuth : 2587|2@0+ (1,0) [0|3] "" Vector__XXX
 SG_ SRRRRODPREOTk1TypCnfdAuth : 2585|2@0+ (1,0) [0|3] "" Vector__XXX
 SG_ SRRRRODPREOTk2CnfdStsAuth : 2599|2@0+ (1,0) [0|3] "" Vector__XXX
 SG_ SRRRRODPREOTk2TypCnfdAuth : 2597|2@0+ (1,0) [0|3] "" Vector__XXX
 SG_ SRRRRODPREOTk3CnfdStsAuth : 2595|2@0+ (1,0) [0|3] "" Vector__XXX
 SG_ SRRRRODPREOTk3TypCnfdAuth : 2593|2@0+ (1,0) [0|3] "" Vector__XXX
 SG_ SRRRRODPRdTypCnfdAuth : 2607|2@0+ (1,0) [0|3] "" Vector__XXX
 SG_ SRRRRODPSwpBndwdthStsAuth : 2605|2@0+ (1,0) [0|3] "" Vector__XXX
 SG_ SRRRRODPVOTk10CnfdStsAuth : 2603|2@0+ (1,0) [0|3] "" Vector__XXX
 SG_ SRRRRODPVOTk10MStsAuth : 2601|2@0+ (1,0) [0|3] "" Vector__XXX
 SG_ SRRRRODPVOTk10TypCnfdAuth : 2615|2@0+ (1,0) [0|3] "" Vector__XXX
 SG_ SRRRRODPVOTk1CnfdStsAuth : 2613|2@0+ (1,0) [0|3] "" Vector__XXX
 SG_ SRRRRODPVOTk1MStsAuth : 2611|2@0+ (1,0) [0|3] "" Vector__XXX
 SG_ SRRRRODPVOTk1TypCnfdAuth : 2609|2@0+ (1,0) [0|3] "" Vector__XXX
 SG_ SRRRRODPVOTk2CnfdStsAuth : 2623|2@0+ (1,0) [0|3] "" Vector__XXX
 SG_ SRRRRODPVOTk2MStsAuth : 2621|2@0+ (1,0) [0|3] "" Vector__XXX
 SG_ SRRRRODPVOTk2TypCnfdAuth : 2619|2@0+ (1,0) [0|3] "" Vector__XXX
 SG_ SRRRRODPVOTk3CnfdStsAuth : 2617|2@0+ (1,0) [0|3] "" Vector__XXX
 SG_ SRRRRODPVOTk3MStsAuth : 2631|2@0+ (1,0) [0|3] "" Vector__XXX
 SG_ SRRRRODPVOTk3TypCnfdAuth : 2629|2@0+ (1,0) [0|3] "" Vector__XXX
 SG_ SRRRRODPVOTk4CnfdStsAuth : 2627|2@0+ (1,0) [0|3] "" Vector__XXX
 SG_ SRRRRODPVOTk4MStsAuth : 2625|2@0+ (1,0) [0|3] "" Vector__XXX
 SG_ SRRRRODPVOTk4TypCnfdAuth : 2639|2@0+ (1,0) [0|3] "" Vector__XXX
 SG_ SRRRRODPVOTk5CnfdStsAuth : 2637|2@0+ (1,0) [0|3] "" Vector__XXX
 SG_ SRRRRODPVOTk5MStsAuth : 2635|2@0+ (1,0) [0|3] "" Vector__XXX
 SG_ SRRRRODPVOTk5TypCnfdAuth : 2633|2@0+ (1,0) [0|3] "" Vector__XXX
 SG_ SRRRRODPVOTk6CnfdStsAuth : 2647|2@0+ (1,0) [0|3] "" Vector__XXX
 SG_ SRRRRODPVOTk6MStsAuth : 2645|2@0+ (1,0) [0|3] "" Vector__XXX
 SG_ SRRRRODPVOTk6TypCnfdAuth : 2643|2@0+ (1,0) [0|3] "" Vector__XXX
 SG_ SRRRRODPVOTk7CnfdStsAuth : 2641|2@0+ (1,0) [0|3] "" Vector__XXX
 SG_ SRRRRODPVOTk7MStsAuth : 2655|2@0+ (1,0) [0|3] "" Vector__XXX
 SG_ SRRRRODPVOTk7TypCnfdAuth : 2653|2@0+ (1,0) [0|3] "" Vector__XXX
 SG_ SRRRRODPVOTk8CnfdStsAuth : 2651|2@0+ (1,0) [0|3] "" Vector__XXX
 SG_ SRRRRODPVOTk8MStsAuth : 2649|2@0+ (1,0) [0|3] "" Vector__XXX
 SG_ SRRRRODPVOTk8TypCnfdAuth : 2663|2@0+ (1,0) [0|3] "" Vector__XXX
 SG_ SRRRRODPVOTk9CnfdStsAuth : 2661|2@0+ (1,0) [0|3] "" Vector__XXX
 SG_ SRRRRODPVOTk9MStsAuth : 2659|2@0+ (1,0) [0|3] "" Vector__XXX
 SG_ SRRRRODPVOTk9TypCnfdAuth : 2657|2@0+ (1,0) [0|3] "" Vector__XXX
 SG_ SRRRRODPAcqTmStmAuth_Inv : 2671|1@0+ (1,0) [0|1] "" Vector__XXX
 SG_ SRRRRODPServRqrdAuth : 2670|1@0+ (1,0) [0|1] "" Vector__XXX
 SG_ SRRRRODPSnsrBlckdAuth : 2669|1@0+ (1,0) [0|1] "" Vector__XXX
 SG_ SRRRRODPSnsrUnvAuth : 2668|1@0+ (1,0) [0|1] "" Vector__XXX
 SG_ SRRRRODPVOTk10DynPrpStsAuth : 2667|1@0+ (1,0) [0|1] "" Vector__XXX
 SG_ SRRRRODPVOTk1DynPrpStsAuth : 2666|1@0+ (1,0) [0|1] "" Vector__XXX
 SG_ SRRRRODPVOTk2DynPrpStsAuth : 2665|1@0+ (1,0) [0|1] "" Vector__XXX
 SG_ SRRRRODPVOTk3DynPrpStsAuth : 2664|1@0+ (1,0) [0|1] "" Vector__XXX
 SG_ SRRRRODPVOTk4DynPrpStsAuth : 2679|1@0+ (1,0) [0|1] "" Vector__XXX
 SG_ SRRRRODPVOTk5DynPrpStsAuth : 2678|1@0+ (1,0) [0|1] "" Vector__XXX
 SG_ SRRRRODPVOTk6DynPrpStsAuth : 2677|1@0+ (1,0) [0|1] "" Vector__XXX
 SG_ SRRRRODPVOTk7DynPrpStsAuth : 2676|1@0+ (1,0) [0|1] "" Vector__XXX
 SG_ SRRRRODPVOTk8DynPrpStsAuth : 2675|1@0+ (1,0) [0|1] "" Vector__XXX
 SG_ SRRRRODPVOTk9DynPrpStsAuth : 2674|1@0+ (1,0) [0|1] "" Vector__XXX
 SG_ SD186BG1P_ARC : 2673|2@0+ (1,0) [0|3] "" Vector__XXX

BO_ 121 Tp_SrlDat186_FlwCtrl_PDU: 64 CGM

BO_ 674 TrnsEstGr_PCSM_PDU: 8 CGM
 SG_ TrnsEstGr_PCSM : 0|64@1+ (1,0) [0|1.84467e+019] "" FCM_LC,UPM

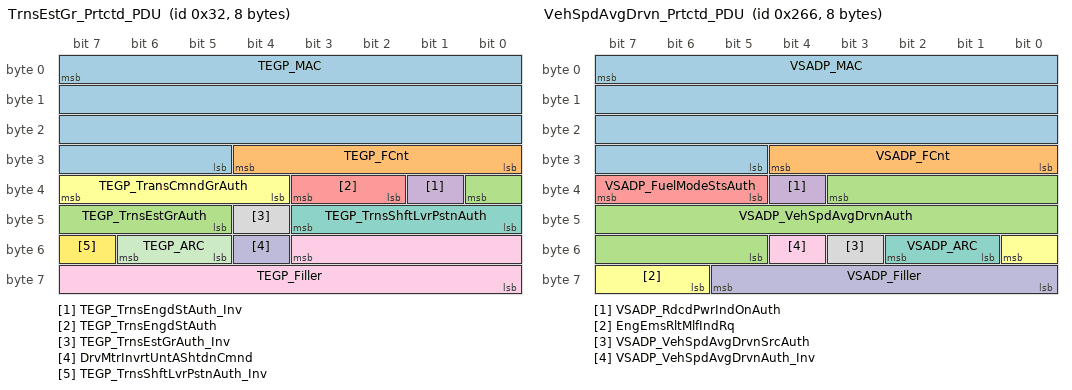
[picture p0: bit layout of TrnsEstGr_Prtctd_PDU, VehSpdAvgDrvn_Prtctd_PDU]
BO_ 50 TrnsEstGr_Prtctd_PDU: 8 CGM
 SG_ TEGP_MAC : 7|27@0+ (1,0) [0|1.34218e+008] "" FCM_LC,UPM
 SG_ TEGP_FCnt : 28|5@0+ (1,0) [0|31] "" FCM_LC,UPM
 SG_ TEGP_TrnsEstGrAuth : 32|4@0+ (1,0) [0|15] "" FCM_LC,UPM
 SG_ TEGP_TrnsEngdStAuth_Inv : 33|1@0+ (1,0) [0|1] "" FCM_LC,UPM
 SG_ TEGP_TrnsEngdStAuth : 35|2@0+ (1,0) [0|3] "" FCM_LC,UPM
 SG_ TEGP_TransCmndGrAuth : 39|4@0+ (1,0) [0|15] "" FCM_LC,UPM
 SG_ TEGP_TrnsShftLvrPstnAuth : 43|4@0+ (1,0) [0|14] "" FCM_LC,UPM
 SG_ TEGP_TrnsEstGrAuth_Inv : 44|1@0+ (1,0) [0|1] "" FCM_LC,UPM
 SG_ TEGP_Filler : 51|12@0+ (1,0) [0|4095] "" FCM_LC,UPM
 SG_ DrvMtrInvrtUntAShtdnCmnd : 52|1@0+ (1,0) [0|1] "" FCM_LC,UPM
 SG_ TEGP_ARC : 54|2@0+ (1,0) [0|3] "" FCM_LC,UPM
 SG_ TEGP_TrnsShftLvrPstnAuth_Inv : 55|1@0+ (1,0) [0|1] "" FCM_LC,UPM

BO_ 2147745828 UPM_CAN8_ClscCANHrtBtActv_PDU: 6 UPM
 SG_ UPM_CAN_8_ClscCANHrtBtActv : 7|1@0+ (1,0) [0|1] "" CGM

BO_ 1644 USDT_Req_BootMode_To_EOCM_CAN_8_: 64 CGM

BO_ 1755 USDT_Req_BootMode_To_EOCM_HCP2_C: 64 CGM

BO_ 1636 USDT_Req_BootMode_To_EOCM_HC_Sup: 64 CGM

BO_ 1724 USDT_Req_BootMode_To_FCM_LC_CAN_: 64 CGM

BO_ 1646 USDT_Req_BootMode_To_HDLM_CAN_8_: 64 CGM

BO_ 1746 USDT_Req_BootMode_To_LRR_CAN_8_c: 64 CGM

BO_ 1747 USDT_Req_BootMode_To_SRR_LF_CAN_: 64 CGM

BO_ 1751 USDT_Req_BootMode_To_SRR_LR_CR_C: 64 CGM

BO_ 1750 USDT_Req_BootMode_To_SRR_RF_CAN_: 64 CGM

BO_ 1752 USDT_Req_BootMode_To_SRR_RR_CAN_: 64 CGM

BO_ 1753 USDT_Req_BootMode_To_SRR_SLR_CAN: 64 CGM

BO_ 1754 USDT_Req_BootMode_To_SRR_SRR_CAN: 64 CGM

BO_ 1770 USDT_Req_BootMode_To_UPM_CAN_8_c: 64 CGM

BO_ 2497342705 USDT_Req_From_TEST_TOOL_1_To_ACP: 64 CGM

BO_ 2430336753 USDT_Req_From_TEST_TOOL_1_To_All: 62 CGM

BO_ 2431385329 USDT_Req_From_TEST_TOOL_1_To_CAN: 62 CGM

BO_ 2497371121 USDT_Req_From_TEST_TOOL_1_To_EOC: 64 CGM

BO_ 2497340657 USDT_Req_From_TEST_TOOL_1_To_E01: 64 CGM

BO_ 2565827825 USDT_Req_From_TEST_TOOL_1_To_E02: 64 CGM

BO_ 2497363185 USDT_Req_From_TEST_TOOL_1_To_FCM: 64 CGM

BO_ 2497343217 USDT_Req_From_TEST_TOOL_1_To_HDL: 64 CGM

BO_ 2497368817 USDT_Req_From_TEST_TOOL_1_To_LRR: 64 CGM

BO_ 2497369073 USDT_Req_From_TEST_TOOL_1_To_SRR: 64 CGM

BO_ 2497370097 USDT_Req_From_TEST_TOOL_1_To_S01: 64 CGM

BO_ 2497369841 USDT_Req_From_TEST_TOOL_1_To_S02: 64 CGM

BO_ 2497370353 USDT_Req_From_TEST_TOOL_1_To_S03: 64 CGM

BO_ 2497370609 USDT_Req_From_TEST_TOOL_1_To_S04: 64 CGM

BO_ 2497370865 USDT_Req_From_TEST_TOOL_1_To_S05: 64 CGM

BO_ 2497374961 USDT_Req_From_TEST_TOOL_1_To_UPM: 64 CGM

BO_ 2497342706 USDT_Req_From_TEST_TOOL_2_To_ACP: 64 CGM

BO_ 2430336754 USDT_Req_From_TEST_TOOL_2_To_All: 62 CGM

BO_ 2431385330 USDT_Req_From_TEST_TOOL_2_To_CAN: 62 CGM

BO_ 2497371122 USDT_Req_From_TEST_TOOL_2_To_EOC: 64 CGM

BO_ 2497340658 USDT_Req_From_TEST_TOOL_2_To_E01: 64 CGM

BO_ 2497363186 USDT_Req_From_TEST_TOOL_2_To_FCM: 64 CGM

BO_ 2497368818 USDT_Req_From_TEST_TOOL_2_To_LRR: 64 CGM

BO_ 2497369074 USDT_Req_From_TEST_TOOL_2_To_SRR: 64 CGM

BO_ 2497370098 USDT_Req_From_TEST_TOOL_2_To_S01: 64 CGM

BO_ 2497369842 USDT_Req_From_TEST_TOOL_2_To_S02: 64 CGM

BO_ 2497370354 USDT_Req_From_TEST_TOOL_2_To_S03: 64 CGM

BO_ 2497370610 USDT_Req_From_TEST_TOOL_2_To_S04: 64 CGM

BO_ 2497370866 USDT_Req_From_TEST_TOOL_2_To_S05: 64 CGM

BO_ 2497374962 USDT_Req_From_TEST_TOOL_2_To_UPM: 64 CGM

BO_ 2497342707 USDT_Req_From_TEST_TOOL_3_To_ACP: 8 CGM

BO_ 2430336755 USDT_Req_From_TEST_TOOL_3_To_All: 7 CGM

BO_ 2431385331 USDT_Req_From_TEST_TOOL_3_To_CAN: 7 CGM

BO_ 2497371123 USDT_Req_From_TEST_TOOL_3_To_EOC: 8 CGM

BO_ 2497340659 USDT_Req_From_TEST_TOOL_3_To_E01: 8 CGM

BO_ 2497363187 USDT_Req_From_TEST_TOOL_3_To_FCM: 8 CGM

BO_ 2497343219 USDT_Req_From_TEST_TOOL_3_To_HDL: 8 CGM

BO_ 2497368819 USDT_Req_From_TEST_TOOL_3_To_LRR: 8 CGM

BO_ 2497369075 USDT_Req_From_TEST_TOOL_3_To_SRR: 8 CGM

BO_ 2497370099 USDT_Req_From_TEST_TOOL_3_To_S01: 8 CGM

BO_ 2497369843 USDT_Req_From_TEST_TOOL_3_To_S02: 8 CGM

BO_ 2497370355 USDT_Req_From_TEST_TOOL_3_To_S03: 8 CGM

BO_ 2497370611 USDT_Req_From_TEST_TOOL_3_To_S04: 8 CGM

BO_ 2497370867 USDT_Req_From_TEST_TOOL_3_To_S05: 8 CGM

BO_ 2497374963 USDT_Req_From_TEST_TOOL_3_To_UPM: 8 CGM

BO_ 2497342708 USDT_Req_From_TEST_TOOL_4_To_ACP: 64 CGM

BO_ 2430336756 USDT_Req_From_TEST_TOOL_4_To_All: 62 CGM

BO_ 2431385332 USDT_Req_From_TEST_TOOL_4_To_CAN: 62 CGM

BO_ 2497371124 USDT_Req_From_TEST_TOOL_4_To_EOC: 64 CGM

BO_ 2497340660 USDT_Req_From_TEST_TOOL_4_To_E01: 64 CGM

BO_ 2497363188 USDT_Req_From_TEST_TOOL_4_To_FCM: 64 CGM

BO_ 2497343220 USDT_Req_From_TEST_TOOL_4_To_HDL: 64 CGM

BO_ 2497368820 USDT_Req_From_TEST_TOOL_4_To_LRR: 64 CGM

BO_ 2497369076 USDT_Req_From_TEST_TOOL_4_To_SRR: 64 CGM

BO_ 2497370100 USDT_Req_From_TEST_TOOL_4_To_S01: 64 CGM

BO_ 2497369844 USDT_Req_From_TEST_TOOL_4_To_S02: 64 CGM

BO_ 2497370356 USDT_Req_From_TEST_TOOL_4_To_S03: 64 CGM

BO_ 2497370612 USDT_Req_From_TEST_TOOL_4_To_S04: 64 CGM

BO_ 2497370868 USDT_Req_From_TEST_TOOL_4_To_S05: 64 CGM

BO_ 2497374964 USDT_Req_From_TEST_TOOL_4_To_UPM: 64 CGM

BO_ 2497342709 USDT_Req_From_TEST_TOOL_5_To_ACP: 64 CGM

BO_ 2430336757 USDT_Req_From_TEST_TOOL_5_To_All: 62 CGM

BO_ 2431385333 USDT_Req_From_TEST_TOOL_5_To_CAN: 62 CGM

BO_ 2497371125 USDT_Req_From_TEST_TOOL_5_To_EOC: 64 CGM

BO_ 2497340661 USDT_Req_From_TEST_TOOL_5_To_E01: 64 CGM

BO_ 2497363189 USDT_Req_From_TEST_TOOL_5_To_FCM: 64 CGM

BO_ 2497343221 USDT_Req_From_TEST_TOOL_5_To_HDL: 64 CGM

BO_ 2497368821 USDT_Req_From_TEST_TOOL_5_To_LRR: 64 CGM

BO_ 2497369077 USDT_Req_From_TEST_TOOL_5_To_SRR: 64 CGM

BO_ 2497370101 USDT_Req_From_TEST_TOOL_5_To_S01: 64 CGM

BO_ 2497369845 USDT_Req_From_TEST_TOOL_5_To_S02: 64 CGM

BO_ 2497370357 USDT_Req_From_TEST_TOOL_5_To_S03: 64 CGM

BO_ 2497370613 USDT_Req_From_TEST_TOOL_5_To_S04: 64 CGM

BO_ 2497370869 USDT_Req_From_TEST_TOOL_5_To_S05: 64 CGM

BO_ 2497374965 USDT_Req_From_TEST_TOOL_5_To_UPM: 64 CGM

BO_ 2497342710 USDT_Req_From_TEST_TOOL_6_To_ACP: 8 CGM

BO_ 2430336758 USDT_Req_From_TEST_TOOL_6_To_All: 7 CGM

BO_ 2431385334 USDT_Req_From_TEST_TOOL_6_To_CAN: 7 CGM

BO_ 2497371126 USDT_Req_From_TEST_TOOL_6_To_EOC: 8 CGM

BO_ 2497340662 USDT_Req_From_TEST_TOOL_6_To_E01: 8 CGM

BO_ 2497363190 USDT_Req_From_TEST_TOOL_6_To_FCM: 8 CGM

BO_ 2497343222 USDT_Req_From_TEST_TOOL_6_To_HDL: 8 CGM

BO_ 2497368822 USDT_Req_From_TEST_TOOL_6_To_LRR: 8 CGM

BO_ 2497369078 USDT_Req_From_TEST_TOOL_6_To_SRR: 8 CGM

BO_ 2497370102 USDT_Req_From_TEST_TOOL_6_To_S01: 8 CGM

BO_ 2497369846 USDT_Req_From_TEST_TOOL_6_To_S02: 8 CGM

BO_ 2497370358 USDT_Req_From_TEST_TOOL_6_To_S03: 8 CGM

BO_ 2497370614 USDT_Req_From_TEST_TOOL_6_To_S04: 8 CGM

BO_ 2497370870 USDT_Req_From_TEST_TOOL_6_To_S05: 8 CGM

BO_ 2497374966 USDT_Req_From_TEST_TOOL_6_To_UPM: 8 CGM

BO_ 2497379436 USDT_Rsp_BootMode_From_EOCM_CAN_: 64 EOCM

BO_ 2497379547 USDT_Rsp_BootMode_From_EOCM_HCP2: 64 EOCM_HCP2

BO_ 2497379428 USDT_Rsp_BootMode_From_EOCM_HC_S: 64 EOCM_HC_Superset

BO_ 2497379516 USDT_Rsp_BootMode_From_FCM_LC_CA: 64 FCM_LC

BO_ 2497379438 USDT_Rsp_BootMode_From_HDLM_CAN_: 64 HDLM

BO_ 2497379538 USDT_Rsp_BootMode_From_LRR_CAN_8: 64 LRR

BO_ 2497379539 USDT_Rsp_BootMode_From_SRR_LF_CA: 64 SRR_LF

BO_ 2497379543 USDT_Rsp_BootMode_From_SRR_LR_CR: 64 SRR_LR_CR

BO_ 2497379542 USDT_Rsp_BootMode_From_SRR_RF_CA: 64 SRR_RF

BO_ 2497379544 USDT_Rsp_BootMode_From_SRR_RR_CA: 64 SRR_RR

BO_ 2497379545 USDT_Rsp_BootMode_From_SRR_SLR_C: 64 SRR_SLR

BO_ 2497379546 USDT_Rsp_BootMode_From_SRR_SRR_C: 64 SRR_SRR

BO_ 2497379562 USDT_Rsp_BootMode_From_UPM_CAN_8: 64 UPM

BO_ 2497376620 USDT_Rsp_From_ACP2_MCU_CAN_8_con: 64 ACP2_MCU

BO_ 2497376876 USDT_Rsp_From_ACP2_MCU_CAN_8_c01: 64 ACP2_MCU

BO_ 2497377132 USDT_Rsp_From_ACP2_MCU_CAN_8_c02: 8 ACP2_MCU

BO_ 2497377388 USDT_Rsp_From_ACP2_MCU_CAN_8_c03: 64 ACP2_MCU

BO_ 2497377644 USDT_Rsp_From_ACP2_MCU_CAN_8_c04: 64 ACP2_MCU

BO_ 2497377900 USDT_Rsp_From_ACP2_MCU_CAN_8_c05: 8 ACP2_MCU

BO_ 2497376731 USDT_Rsp_From_EOCM_HCP2_CAN_8_co: 64 EOCM_HCP2

BO_ 2497376987 USDT_Rsp_From_EOCM_HCP2_CAN_8_01: 64 EOCM_HCP2

BO_ 2497377243 USDT_Rsp_From_EOCM_HCP2_CAN_8_02: 8 EOCM_HCP2

BO_ 2497377499 USDT_Rsp_From_EOCM_HCP2_CAN_8_03: 64 EOCM_HCP2

BO_ 2497377755 USDT_Rsp_From_EOCM_HCP2_CAN_8_04: 64 EOCM_HCP2

BO_ 2497378011 USDT_Rsp_From_EOCM_HCP2_CAN_8_05: 8 EOCM_HCP2

BO_ 2497376612 USDT_Rsp_From_EOCM_HC_Superset_C: 64 EOCM_HC_Superset

BO_ 2497376868 USDT_Rsp_From_EOCM_HC_Superset01: 64 EOCM_HC_Superset

BO_ 2497377124 USDT_Rsp_From_EOCM_HC_Superset02: 8 EOCM_HC_Superset

BO_ 2497377380 USDT_Rsp_From_EOCM_HC_Superset03: 64 EOCM_HC_Superset

BO_ 2497377636 USDT_Rsp_From_EOCM_HC_Superset04: 64 EOCM_HC_Superset

BO_ 2497377892 USDT_Rsp_From_EOCM_HC_Superset05: 8 EOCM_HC_Superset

BO_ 2565861740 USDT_Rsp_From_EOCM_XCP_CAN_8_con: 64 EOCM

BO_ 2497376700 USDT_Rsp_From_FCM_LC_CAN_8_conne: 64 FCM_LC

BO_ 2497376956 USDT_Rsp_From_FCM_LC_CAN_8_con01: 64 FCM_LC

BO_ 2497377212 USDT_Rsp_From_FCM_LC_CAN_8_con02: 8 FCM_LC

BO_ 2497377468 USDT_Rsp_From_FCM_LC_CAN_8_con03: 64 FCM_LC

BO_ 2497377724 USDT_Rsp_From_FCM_LC_CAN_8_con04: 64 FCM_LC

BO_ 2497377980 USDT_Rsp_From_FCM_LC_CAN_8_con05: 8 FCM_LC

BO_ 2497376622 USDT_Rsp_From_HDLM_CAN_8_connect: 64 HDLM

BO_ 2497377134 USDT_Rsp_From_HDLM_CAN_8_conne01: 8 HDLM

BO_ 2497377390 USDT_Rsp_From_HDLM_CAN_8_conne02: 64 HDLM

BO_ 2497377646 USDT_Rsp_From_HDLM_CAN_8_conne03: 64 HDLM

BO_ 2497377902 USDT_Rsp_From_HDLM_CAN_8_conne04: 8 HDLM

BO_ 2497376722 USDT_Rsp_From_LRR_CAN_8_connecto: 64 LRR

BO_ 2497376978 USDT_Rsp_From_LRR_CAN_8_connec01: 64 LRR

BO_ 2497377234 USDT_Rsp_From_LRR_CAN_8_connec02: 8 LRR

BO_ 2497377490 USDT_Rsp_From_LRR_CAN_8_connec03: 64 LRR

BO_ 2497377746 USDT_Rsp_From_LRR_CAN_8_connec04: 64 LRR

BO_ 2497378002 USDT_Rsp_From_LRR_CAN_8_connec05: 8 LRR

BO_ 2497376723 USDT_Rsp_From_SRR_LF_CAN_8_conne: 64 SRR_LF

BO_ 2497376979 USDT_Rsp_From_SRR_LF_CAN_8_con01: 64 SRR_LF

BO_ 2497377235 USDT_Rsp_From_SRR_LF_CAN_8_con02: 8 SRR_LF

BO_ 2497377491 USDT_Rsp_From_SRR_LF_CAN_8_con03: 64 SRR_LF

BO_ 2497377747 USDT_Rsp_From_SRR_LF_CAN_8_con04: 64 SRR_LF

BO_ 2497378003 USDT_Rsp_From_SRR_LF_CAN_8_con05: 8 SRR_LF

BO_ 2497376727 USDT_Rsp_From_SRR_LR_CR_CAN_8_co: 64 SRR_LR_CR

BO_ 2497376983 USDT_Rsp_From_SRR_LR_CR_CAN_8_01: 64 SRR_LR_CR

BO_ 2497377239 USDT_Rsp_From_SRR_LR_CR_CAN_8_02: 8 SRR_LR_CR

BO_ 2497377495 USDT_Rsp_From_SRR_LR_CR_CAN_8_03: 64 SRR_LR_CR

BO_ 2497377751 USDT_Rsp_From_SRR_LR_CR_CAN_8_04: 64 SRR_LR_CR

BO_ 2497378007 USDT_Rsp_From_SRR_LR_CR_CAN_8_05: 8 SRR_LR_CR

BO_ 2497376726 USDT_Rsp_From_SRR_RF_CAN_8_conne: 64 SRR_RF

BO_ 2497376982 USDT_Rsp_From_SRR_RF_CAN_8_con01: 64 SRR_RF

BO_ 2497377238 USDT_Rsp_From_SRR_RF_CAN_8_con02: 8 SRR_RF

BO_ 2497377494 USDT_Rsp_From_SRR_RF_CAN_8_con03: 64 SRR_RF

BO_ 2497377750 USDT_Rsp_From_SRR_RF_CAN_8_con04: 64 SRR_RF

BO_ 2497378006 USDT_Rsp_From_SRR_RF_CAN_8_con05: 8 SRR_RF

BO_ 2497376728 USDT_Rsp_From_SRR_RR_CAN_8_conne: 64 SRR_RR

BO_ 2497376984 USDT_Rsp_From_SRR_RR_CAN_8_con01: 64 SRR_RR

BO_ 2497377240 USDT_Rsp_From_SRR_RR_CAN_8_con02: 8 SRR_RR

BO_ 2497377496 USDT_Rsp_From_SRR_RR_CAN_8_con03: 64 SRR_RR

BO_ 2497377752 USDT_Rsp_From_SRR_RR_CAN_8_con04: 64 SRR_RR

BO_ 2497378008 USDT_Rsp_From_SRR_RR_CAN_8_con05: 8 SRR_RR

BO_ 2497376729 USDT_Rsp_From_SRR_SLR_CAN_8_conn: 64 SRR_SLR

BO_ 2497376985 USDT_Rsp_From_SRR_SLR_CAN_8_co01: 64 SRR_SLR

BO_ 2497377241 USDT_Rsp_From_SRR_SLR_CAN_8_co02: 8 SRR_SLR

BO_ 2497377497 USDT_Rsp_From_SRR_SLR_CAN_8_co03: 64 SRR_SLR

BO_ 2497377753 USDT_Rsp_From_SRR_SLR_CAN_8_co04: 64 SRR_SLR

BO_ 2497378009 USDT_Rsp_From_SRR_SLR_CAN_8_co05: 8 SRR_SLR

BO_ 2497376730 USDT_Rsp_From_SRR_SRR_CAN_8_conn: 64 SRR_SRR

BO_ 2497376986 USDT_Rsp_From_SRR_SRR_CAN_8_co01: 64 SRR_SRR

BO_ 2497377242 USDT_Rsp_From_SRR_SRR_CAN_8_co02: 8 SRR_SRR

BO_ 2497377498 USDT_Rsp_From_SRR_SRR_CAN_8_co03: 64 SRR_SRR

BO_ 2497377754 USDT_Rsp_From_SRR_SRR_CAN_8_co04: 64 SRR_SRR

BO_ 2497378010 USDT_Rsp_From_SRR_SRR_CAN_8_co05: 8 SRR_SRR

BO_ 2497376746 USDT_Rsp_From_UPM_CAN_8_connecto: 64 UPM

BO_ 2497377002 USDT_Rsp_From_UPM_CAN_8_connec01: 64 UPM

BO_ 2497377258 USDT_Rsp_From_UPM_CAN_8_connec02: 8 UPM

BO_ 2497377514 USDT_Rsp_From_UPM_CAN_8_connec03: 64 UPM

BO_ 2497377770 USDT_Rsp_From_UPM_CAN_8_connec04: 64 UPM

BO_ 2497378026 USDT_Rsp_From_UPM_CAN_8_connec05: 8 UPM

BO_ 2497507692 UUDT_Rsp_From_EOCM_CAN_8_connect: 64 EOCM

BO_ 2497507948 UUDT_Rsp_From_EOCM_CAN_8_conne01: 64 EOCM

BO_ 2497508204 UUDT_Rsp_From_EOCM_CAN_8_conne02: 8 EOCM

BO_ 2497508460 UUDT_Rsp_From_EOCM_CAN_8_conne03: 64 EOCM

BO_ 2497508716 UUDT_Rsp_From_EOCM_CAN_8_conne04: 64 EOCM

BO_ 2497508972 UUDT_Rsp_From_EOCM_CAN_8_conne05: 8 EOCM

BO_ 2497507803 UUDT_Rsp_From_EOCM_HCP2_CAN_8_co: 64 EOCM_HCP2

BO_ 2497508059 UUDT_Rsp_From_EOCM_HCP2_CAN_8_01: 64 EOCM_HCP2

BO_ 2497508315 UUDT_Rsp_From_EOCM_HCP2_CAN_8_02: 8 EOCM_HCP2

BO_ 2497508571 UUDT_Rsp_From_EOCM_HCP2_CAN_8_03: 64 EOCM_HCP2

BO_ 2497508827 UUDT_Rsp_From_EOCM_HCP2_CAN_8_04: 64 EOCM_HCP2

BO_ 2497509083 UUDT_Rsp_From_EOCM_HCP2_CAN_8_05: 8 EOCM_HCP2

BO_ 2497507684 UUDT_Rsp_From_EOCM_HC_Superset_C: 64 EOCM_HC_Superset

BO_ 2497507940 UUDT_Rsp_From_EOCM_HC_Superset01: 64 EOCM_HC_Superset

BO_ 2497508196 UUDT_Rsp_From_EOCM_HC_Superset02: 8 EOCM_HC_Superset

BO_ 2497508452 UUDT_Rsp_From_EOCM_HC_Superset03: 64 EOCM_HC_Superset

BO_ 2497508708 UUDT_Rsp_From_EOCM_HC_Superset04: 64 EOCM_HC_Superset

BO_ 2497508964 UUDT_Rsp_From_EOCM_HC_Superset05: 8 EOCM_HC_Superset

BO_ 2497507772 UUDT_Rsp_From_FCM_LC_CAN_8_conne: 64 FCM_LC

BO_ 2497508028 UUDT_Rsp_From_FCM_LC_CAN_8_con01: 64 FCM_LC

BO_ 2497508284 UUDT_Rsp_From_FCM_LC_CAN_8_con02: 8 FCM_LC

BO_ 2497508540 UUDT_Rsp_From_FCM_LC_CAN_8_con03: 64 FCM_LC

BO_ 2497508796 UUDT_Rsp_From_FCM_LC_CAN_8_con04: 64 FCM_LC

BO_ 2497509052 UUDT_Rsp_From_FCM_LC_CAN_8_con05: 8 FCM_LC

BO_ 2497507694 UUDT_Rsp_From_HDLM_CAN_8_connect: 64 HDLM

BO_ 2497508206 UUDT_Rsp_From_HDLM_CAN_8_conne01: 8 HDLM

BO_ 2497508974 UUDT_Rsp_From_HDLM_CAN_8_conne02: 8 HDLM

BO_ 2497507794 UUDT_Rsp_From_LRR_CAN_8_connecto: 64 LRR

BO_ 2497508050 UUDT_Rsp_From_LRR_CAN_8_connec01: 64 LRR

BO_ 2497508306 UUDT_Rsp_From_LRR_CAN_8_connec02: 8 LRR

BO_ 2497508562 UUDT_Rsp_From_LRR_CAN_8_connec03: 64 LRR

BO_ 2497508818 UUDT_Rsp_From_LRR_CAN_8_connec04: 64 LRR

BO_ 2497509074 UUDT_Rsp_From_LRR_CAN_8_connec05: 8 LRR

BO_ 2497507795 UUDT_Rsp_From_SRR_LF_CAN_8_conne: 64 SRR_LF

BO_ 2497508051 UUDT_Rsp_From_SRR_LF_CAN_8_con01: 64 SRR_LF

BO_ 2497508307 UUDT_Rsp_From_SRR_LF_CAN_8_con02: 8 SRR_LF

BO_ 2497508563 UUDT_Rsp_From_SRR_LF_CAN_8_con03: 64 SRR_LF

BO_ 2497508819 UUDT_Rsp_From_SRR_LF_CAN_8_con04: 64 SRR_LF

BO_ 2497509075 UUDT_Rsp_From_SRR_LF_CAN_8_con05: 8 SRR_LF

BO_ 2497507799 UUDT_Rsp_From_SRR_LR_CR_CAN_8_co: 64 SRR_LR_CR

BO_ 2497508055 UUDT_Rsp_From_SRR_LR_CR_CAN_8_01: 64 SRR_LR_CR

BO_ 2497508311 UUDT_Rsp_From_SRR_LR_CR_CAN_8_02: 8 SRR_LR_CR

BO_ 2497508567 UUDT_Rsp_From_SRR_LR_CR_CAN_8_03: 64 SRR_LR_CR

BO_ 2497508823 UUDT_Rsp_From_SRR_LR_CR_CAN_8_04: 64 SRR_LR_CR

BO_ 2497509079 UUDT_Rsp_From_SRR_LR_CR_CAN_8_05: 8 SRR_LR_CR

BO_ 2497507798 UUDT_Rsp_From_SRR_RF_CAN_8_conne: 64 SRR_RF

BO_ 2497508054 UUDT_Rsp_From_SRR_RF_CAN_8_con01: 64 SRR_RF

BO_ 2497508310 UUDT_Rsp_From_SRR_RF_CAN_8_con02: 8 SRR_RF

BO_ 2497508566 UUDT_Rsp_From_SRR_RF_CAN_8_con03: 64 SRR_RF

BO_ 2497508822 UUDT_Rsp_From_SRR_RF_CAN_8_con04: 64 SRR_RF

BO_ 2497509078 UUDT_Rsp_From_SRR_RF_CAN_8_con05: 8 SRR_RF

BO_ 2497507800 UUDT_Rsp_From_SRR_RR_CAN_8_conne: 64 SRR_RR

BO_ 2497508056 UUDT_Rsp_From_SRR_RR_CAN_8_con01: 64 SRR_RR

BO_ 2497508312 UUDT_Rsp_From_SRR_RR_CAN_8_con02: 8 SRR_RR

BO_ 2497508568 UUDT_Rsp_From_SRR_RR_CAN_8_con03: 64 SRR_RR

BO_ 2497508824 UUDT_Rsp_From_SRR_RR_CAN_8_con04: 64 SRR_RR

BO_ 2497509080 UUDT_Rsp_From_SRR_RR_CAN_8_con05: 8 SRR_RR

BO_ 2497507801 UUDT_Rsp_From_SRR_SLR_CAN_8_conn: 64 SRR_SLR

BO_ 2497508057 UUDT_Rsp_From_SRR_SLR_CAN_8_co01: 64 SRR_SLR

BO_ 2497508313 UUDT_Rsp_From_SRR_SLR_CAN_8_co02: 8 SRR_SLR

BO_ 2497508569 UUDT_Rsp_From_SRR_SLR_CAN_8_co03: 64 SRR_SLR

BO_ 2497508825 UUDT_Rsp_From_SRR_SLR_CAN_8_co04: 64 SRR_SLR

BO_ 2497509081 UUDT_Rsp_From_SRR_SLR_CAN_8_co05: 8 SRR_SLR

BO_ 2497507802 UUDT_Rsp_From_SRR_SRR_CAN_8_conn: 64 SRR_SRR

BO_ 2497508058 UUDT_Rsp_From_SRR_SRR_CAN_8_co01: 64 SRR_SRR

BO_ 2497508314 UUDT_Rsp_From_SRR_SRR_CAN_8_co02: 8 SRR_SRR

BO_ 2497508570 UUDT_Rsp_From_SRR_SRR_CAN_8_co03: 64 SRR_SRR

BO_ 2497508826 UUDT_Rsp_From_SRR_SRR_CAN_8_co04: 64 SRR_SRR

BO_ 2497509082 UUDT_Rsp_From_SRR_SRR_CAN_8_co05: 8 SRR_SRR

BO_ 2497507818 UUDT_Rsp_From_UPM_CAN_8_connecto: 64 UPM

BO_ 2497508074 UUDT_Rsp_From_UPM_CAN_8_connec01: 64 UPM

BO_ 2497508330 UUDT_Rsp_From_UPM_CAN_8_connec02: 8 UPM

BO_ 2497508586 UUDT_Rsp_From_UPM_CAN_8_connec03: 64 UPM

BO_ 2497508842 UUDT_Rsp_From_UPM_CAN_8_connec04: 64 UPM

BO_ 2497509098 UUDT_Rsp_From_UPM_CAN_8_connec05: 8 UPM

BO_ 1442 VehIdNmDig10_17_PDU: 8 CGM
 SG_ VehIdNmDig10_17 : 7|64@0+ (1,0) [0|18446744073709551615] "" HDLM

BO_ 1443 VehIdNmDig2_9_PDU: 8 CGM
 SG_ VehIdNmDig2_9 : 7|64@0+ (1,0) [0|18446744073709551615] "" HDLM

BO_ 1402 VehSpdAvgDrvn_PCSM_PDU: 8 CGM
 SG_ VehSpdAvgDrvn_PCSM : 0|64@1+ (1,0) [0|1.84467e+019] "" HDLM

BO_ 614 VehSpdAvgDrvn_Prtctd_PDU: 8 CGM
 SG_ VSADP_MAC : 7|27@0+ (1,0) [0|1.34218e+008] "" HDLM
 SG_ VSADP_FCnt : 28|5@0+ (1,0) [0|31] "" HDLM
 SG_ VSADP_VehSpdAvgDrvnAuth : 35|15@0+ (0.015625,0) [0|511.984] "km / h" EOCM_HCP2,FCM_LC,HDLM,LRR,SRR_LF,SRR_LR_CR,SRR_RF,SRR_RR,SRR_SLR,SRR_SRR
 SG_ VSADP_RdcdPwrIndOnAuth : 36|1@0+ (1,0) [0|1] "" HDLM
 SG_ VSADP_FuelModeStsAuth : 39|3@0+ (1,0) [0|4] "" HDLM
 SG_ EngEmsRltMlfIndRq : 48|3@0+ (1,0) [0|4] "" HDLM
 SG_ VSADP_ARC : 50|2@0+ (1,0) [0|3] "" HDLM
 SG_ VSADP_VehSpdAvgDrvnSrcAuth : 51|1@0+ (1,0) [0|1] "" HDLM
 SG_ VSADP_VehSpdAvgDrvnAuth_Inv : 52|1@0+ (1,0) [0|1] "" FCM_LC,HDLM,SRR_SLR,SRR_SRR
 SG_ VSADP_Filler : 61|6@0+ (1,0) [0|63] "" HDLM

BA_DEF_ SG_  "SignalType" STRING ;
BA_DEF_ SG_  "SignalLongName" STRING ;
BA_DEF_ BO_  "GenMsgCycleTime" INT 0 10000;
BA_DEF_ BO_  "GenMsgSendType" ENUM "cyclicX","spontanX","cyclicIfActiveX","spontanWithDelay","cyclicAndSpontanX","cyclicAndSpontanWithDelay","spontanWithRepetition","cyclicIfActiveAndSpontanWD";
BA_DEF_ BO_  "VFrameFormat" ENUM  "StandardCAN","ExtendedCAN","reserved","reserved","reserved","reserved","reserved","reserved","reserved","reserved","reserved","reserved","reserved","reserved","StandardCAN_FD","ExtendedCAN_FD";
BA_DEF_DEF_  "SignalType" "";
BA_DEF_DEF_  "SignalLongName" "";
BA_DEF_DEF_  "GenMsgCycleTime" 0;
BA_DEF_DEF_  "GenMsgSendType" "cyclicX";
BA_DEF_DEF_  "VFrameFormat" "StandardCAN";
BA_ "VFrameFormat" BO_ 120 14;
BA_ "VFrameFormat" BO_ 121 14;
BA_ "VFrameFormat" BO_ 674 14;
BA_ "GenMsgCycleTime" BO_ 50 12.5;
BA_ "VFrameFormat" BO_ 50 14;
BA_ "GenMsgCycleTime" BO_ 2147745828 1000;
BA_ "VFrameFormat" BO_ 1644 14;
BA_ "VFrameFormat" BO_ 1755 14;
BA_ "VFrameFormat" BO_ 1636 14;
BA_ "VFrameFormat" BO_ 1724 14;
BA_ "VFrameFormat" BO_ 1646 14;
BA_ "VFrameFormat" BO_ 1746 14;
BA_ "VFrameFormat" BO_ 1747 14;
BA_ "VFrameFormat" BO_ 1751 14;
BA_ "VFrameFormat" BO_ 1750 14;
BA_ "VFrameFormat" BO_ 1752 14;
BA_ "VFrameFormat" BO_ 1753 14;
BA_ "VFrameFormat" BO_ 1754 14;
BA_ "VFrameFormat" BO_ 1770 14;
BA_ "VFrameFormat" BO_ 2497342705 15;
BA_ "VFrameFormat" BO_ 2430336753 15;
BA_ "VFrameFormat" BO_ 2431385329 15;
BA_ "VFrameFormat" BO_ 2497371121 15;
BA_ "VFrameFormat" BO_ 2497340657 15;
BA_ "VFrameFormat" BO_ 2565827825 15;
BA_ "VFrameFormat" BO_ 2497363185 15;
BA_ "VFrameFormat" BO_ 2497343217 15;
BA_ "VFrameFormat" BO_ 2497368817 15;
BA_ "VFrameFormat" BO_ 2497369073 15;
BA_ "VFrameFormat" BO_ 2497370097 15;
BA_ "VFrameFormat" BO_ 2497369841 15;
BA_ "VFrameFormat" BO_ 2497370353 15;
BA_ "VFrameFormat" BO_ 2497370609 15;
BA_ "VFrameFormat" BO_ 2497370865 15;
BA_ "VFrameFormat" BO_ 2497374961 15;
BA_ "VFrameFormat" BO_ 2497342706 15;
BA_ "VFrameFormat" BO_ 2430336754 15;
BA_ "VFrameFormat" BO_ 2431385330 15;
BA_ "VFrameFormat" BO_ 2497371122 15;
BA_ "VFrameFormat" BO_ 2497340658 15;
BA_ "VFrameFormat" BO_ 2497363186 15;
BA_ "VFrameFormat" BO_ 2497368818 15;
BA_ "VFrameFormat" BO_ 2497369074 15;
BA_ "VFrameFormat" BO_ 2497370098 15;
BA_ "VFrameFormat" BO_ 2497369842 15;
BA_ "VFrameFormat" BO_ 2497370354 15;
BA_ "VFrameFormat" BO_ 2497370610 15;
BA_ "VFrameFormat" BO_ 2497370866 15;
BA_ "VFrameFormat" BO_ 2497374962 15;
BA_ "VFrameFormat" BO_ 2497342708 15;
BA_ "VFrameFormat" BO_ 2430336756 15;
BA_ "VFrameFormat" BO_ 2431385332 15;
BA_ "VFrameFormat" BO_ 2497371124 15;
BA_ "VFrameFormat" BO_ 2497340660 15;
BA_ "VFrameFormat" BO_ 2497363188 15;
BA_ "VFrameFormat" BO_ 2497343220 15;
BA_ "VFrameFormat" BO_ 2497368820 15;
BA_ "VFrameFormat" BO_ 2497369076 15;
BA_ "VFrameFormat" BO_ 2497370100 15;
BA_ "VFrameFormat" BO_ 2497369844 15;
BA_ "VFrameFormat" BO_ 2497370356 15;
BA_ "VFrameFormat" BO_ 2497370612 15;
BA_ "VFrameFormat" BO_ 2497370868 15;
BA_ "VFrameFormat" BO_ 2497374964 15;
BA_ "VFrameFormat" BO_ 2497342709 15;
BA_ "VFrameFormat" BO_ 2430336757 15;
BA_ "VFrameFormat" BO_ 2431385333 15;
BA_ "VFrameFormat" BO_ 2497371125 15;
BA_ "VFrameFormat" BO_ 2497340661 15;
BA_ "VFrameFormat" BO_ 2497363189 15;
BA_ "VFrameFormat" BO_ 2497343221 15;
BA_ "VFrameFormat" BO_ 2497368821 15;
BA_ "VFrameFormat" BO_ 2497369077 15;
BA_ "VFrameFormat" BO_ 2497370101 15;
BA_ "VFrameFormat" BO_ 2497369845 15;
BA_ "VFrameFormat" BO_ 2497370357 15;
BA_ "VFrameFormat" BO_ 2497370613 15;
BA_ "VFrameFormat" BO_ 2497370869 15;
BA_ "VFrameFormat" BO_ 2497374965 15;
BA_ "VFrameFormat" BO_ 2497379436 15;
BA_ "VFrameFormat" BO_ 2497379547 15;
BA_ "VFrameFormat" BO_ 2497379428 15;
BA_ "VFrameFormat" BO_ 2497379516 15;
BA_ "VFrameFormat" BO_ 2497379438 15;
BA_ "VFrameFormat" BO_ 2497379538 15;
BA_ "VFrameFormat" BO_ 2497379539 15;
BA_ "VFrameFormat" BO_ 2497379543 15;
BA_ "VFrameFormat" BO_ 2497379542 15;
BA_ "VFrameFormat" BO_ 2497379544 15;
BA_ "VFrameFormat" BO_ 2497379545 15;
BA_ "VFrameFormat" BO_ 2497379546 15;
BA_ "VFrameFormat" BO_ 2497379562 15;
BA_ "VFrameFormat" BO_ 2497376620 15;
BA_ "VFrameFormat" BO_ 2497376876 15;
BA_ "VFrameFormat" BO_ 2497377388 15;
BA_ "VFrameFormat" BO_ 2497377644 15;
BA_ "VFrameFormat" BO_ 2497376731 15;
BA_ "VFrameFormat" BO_ 2497376987 15;
BA_ "VFrameFormat" BO_ 2497377499 15;
BA_ "VFrameFormat" BO_ 2497377755 15;
BA_ "VFrameFormat" BO_ 2497376612 15;
BA_ "VFrameFormat" BO_ 2497376868 15;
BA_ "VFrameFormat" BO_ 2497377380 15;
BA_ "VFrameFormat" BO_ 2497377636 15;
BA_ "VFrameFormat" BO_ 2565861740 15;
BA_ "VFrameFormat" BO_ 2497376700 15;
BA_ "VFrameFormat" BO_ 2497376956 15;
BA_ "VFrameFormat" BO_ 2497377468 15;
BA_ "VFrameFormat" BO_ 2497377724 15;
BA_ "VFrameFormat" BO_ 2497376622 15;
BA_ "VFrameFormat" BO_ 2497377390 15;
BA_ "VFrameFormat" BO_ 2497377646 15;
BA_ "VFrameFormat" BO_ 2497376722 15;
BA_ "VFrameFormat" BO_ 2497376978 15;
BA_ "VFrameFormat" BO_ 2497377490 15;
BA_ "VFrameFormat" BO_ 2497377746 15;
BA_ "VFrameFormat" BO_ 2497376723 15;
BA_ "VFrameFormat" BO_ 2497376979 15;
BA_ "VFrameFormat" BO_ 2497377491 15;
BA_ "VFrameFormat" BO_ 2497377747 15;
BA_ "VFrameFormat" BO_ 2497376727 15;
BA_ "VFrameFormat" BO_ 2497376983 15;
BA_ "VFrameFormat" BO_ 2497377495 15;
BA_ "VFrameFormat" BO_ 2497377751 15;
BA_ "VFrameFormat" BO_ 2497376726 15;
BA_ "VFrameFormat" BO_ 2497376982 15;
BA_ "VFrameFormat" BO_ 2497377494 15;
BA_ "VFrameFormat" BO_ 2497377750 15;
BA_ "VFrameFormat" BO_ 2497376728 15;
BA_ "VFrameFormat" BO_ 2497376984 15;
BA_ "VFrameFormat" BO_ 2497377496 15;
BA_ "VFrameFormat" BO_ 2497377752 15;
BA_ "VFrameFormat" BO_ 2497376729 15;
BA_ "VFrameFormat" BO_ 2497376985 15;
BA_ "VFrameFormat" BO_ 2497377497 15;
BA_ "VFrameFormat" BO_ 2497377753 15;
BA_ "VFrameFormat" BO_ 2497376730 15;
BA_ "VFrameFormat" BO_ 2497376986 15;
BA_ "VFrameFormat" BO_ 2497377498 15;
BA_ "VFrameFormat" BO_ 2497377754 15;
BA_ "VFrameFormat" BO_ 2497376746 15;
BA_ "VFrameFormat" BO_ 2497377002 15;
BA_ "VFrameFormat" BO_ 2497377514 15;
BA_ "VFrameFormat" BO_ 2497377770 15;
BA_ "VFrameFormat" BO_ 2497507692 15;
BA_ "VFrameFormat" BO_ 2497507948 15;
BA_ "VFrameFormat" BO_ 2497508460 15;
BA_ "VFrameFormat" BO_ 2497508716 15;
BA_ "VFrameFormat" BO_ 2497507803 15;
BA_ "VFrameFormat" BO_ 2497508059 15;
BA_ "VFrameFormat" BO_ 2497508571 15;
BA_ "VFrameFormat" BO_ 2497508827 15;
BA_ "VFrameFormat" BO_ 2497507684 15;
BA_ "VFrameFormat" BO_ 2497507940 15;
BA_ "VFrameFormat" BO_ 2497508452 15;
BA_ "VFrameFormat" BO_ 2497508708 15;
BA_ "VFrameFormat" BO_ 2497507772 15;
BA_ "VFrameFormat" BO_ 2497508028 15;
BA_ "VFrameFormat" BO_ 2497508540 15;
BA_ "VFrameFormat" BO_ 2497508796 15;
BA_ "VFrameFormat" BO_ 2497507694 15;
BA_ "VFrameFormat" BO_ 2497507794 15;
BA_ "VFrameFormat" BO_ 2497508050 15;
BA_ "VFrameFormat" BO_ 2497508562 15;
BA_ "VFrameFormat" BO_ 2497508818 15;
BA_ "VFrameFormat" BO_ 2497507795 15;
BA_ "VFrameFormat" BO_ 2497508051 15;
BA_ "VFrameFormat" BO_ 2497508563 15;
BA_ "VFrameFormat" BO_ 2497508819 15;
BA_ "VFrameFormat" BO_ 2497507799 15;
BA_ "VFrameFormat" BO_ 2497508055 15;
BA_ "VFrameFormat" BO_ 2497508567 15;
BA_ "VFrameFormat" BO_ 2497508823 15;
BA_ "VFrameFormat" BO_ 2497507798 15;
BA_ "VFrameFormat" BO_ 2497508054 15;
BA_ "VFrameFormat" BO_ 2497508566 15;
BA_ "VFrameFormat" BO_ 2497508822 15;
BA_ "VFrameFormat" BO_ 2497507800 15;
BA_ "VFrameFormat" BO_ 2497508056 15;
BA_ "VFrameFormat" BO_ 2497508568 15;
BA_ "VFrameFormat" BO_ 2497508824 15;
BA_ "VFrameFormat" BO_ 2497507801 15;
BA_ "VFrameFormat" BO_ 2497508057 15;
BA_ "VFrameFormat" BO_ 2497508569 15;
BA_ "VFrameFormat" BO_ 2497508825 15;
BA_ "VFrameFormat" BO_ 2497507802 15;
BA_ "VFrameFormat" BO_ 2497508058 15;
BA_ "VFrameFormat" BO_ 2497508570 15;
BA_ "VFrameFormat" BO_ 2497508826 15;
BA_ "VFrameFormat" BO_ 2497507818 15;
BA_ "VFrameFormat" BO_ 2497508074 15;
BA_ "VFrameFormat" BO_ 2497508586 15;
BA_ "VFrameFormat" BO_ 2497508842 15;
BA_ "GenMsgCycleTime" BO_ 1442 1000;
BA_ "VFrameFormat" BO_ 1442 14;
BA_ "GenMsgCycleTime" BO_ 1443 1000;
BA_ "VFrameFormat" BO_ 1443 14;
BA_ "VFrameFormat" BO_ 1402 14;
BA_ "GenMsgCycleTime" BO_ 614 100;
BA_ "VFrameFormat" BO_ 614 14;
BA_ "SignalLongName" SG_ 120 SRRRRODPREOTk1CrvAuth "Serial Data 186 : Short Range Radar Right Rear Object Detection and Processing Road Edge Object Track 1 Curvature";
BA_ "SignalLongName" SG_ 120 SRRRRODPREOTk1CrvDrvtAuth "Serial Data 186 : Short Range Radar Right Rear Object Detection and Processing Road Edge Object Track 1 Curvature Derivative";
BA_ "SignalLongName" SG_ 120 SRRRRODPREOTk2CrvAuth "Serial Data 186 : Short Range Radar Right Rear Object Detection and Processing Road Edge Object Track 2 Curvature";
BA_ "SignalLongName" SG_ 120 SRRRRODPREOTk2CrvDrvtAuth "Serial Data 186 : Short Range Radar Right Rear Object Detection and Processing Road Edge Object Track 2 Curvature Derivative";
BA_ "SignalLongName" SG_ 120 SRRRRODPREOTk3CrvAuth "Serial Data 186 : Short Range Radar Right Rear Object Detection and Processing Road Edge Object Track 3 Curvature";
BA_ "SignalLongName" SG_ 120 SRRRRODPREOTk3CrvDrvtAuth "Serial Data 186 : Short Range Radar Right Rear Object Detection and Processing Road Edge Object Track 3 Curvature Derivative";
BA_ "SignalLongName" SG_ 120 SRRRRODPVOTk10PoILgPsCAuth "Serial Data 186 : Short Range Radar Right Rear Object Detection and Processing Vehicle Object Track 10 Point of Interest Longitudinal Position Covariance";
BA_ "SignalLongName" SG_ 120 SRRRRODPVOTk1PoILgPsCAuth "Serial Data 186 : Short Range Radar Right Rear Object Detection and Processing Vehicle Object Track 1 Point of Interest Longitudinal Position Covariance";
BA_ "SignalLongName" SG_ 120 SRRRRODPVOTk2PoILgPsCAuth "Serial Data 186 : Short Range Radar Right Rear Object Detection and Processing Vehicle Object Track 2 Point of Interest Longitudinal Position Covariance";
BA_ "SignalLongName" SG_ 120 SRRRRODPVOTk3PoILgPsCAuth "Serial Data 186 : Short Range Radar Right Rear Object Detection and Processing Vehicle Object Track 3 Point of Interest Longitudinal Position Covariance";
BA_ "SignalLongName" SG_ 120 SRRRRODPVOTk4PoILgPsCAuth "Serial Data 186 : Short Range Radar Right Rear Object Detection and Processing Vehicle Object Track 4 Point of Interest Longitudinal Position Covariance";
BA_ "SignalLongName" SG_ 120 SRRRRODPVOTk5PoILgPsCAuth "Serial Data 186 : Short Range Radar Right Rear Object Detection and Processing Vehicle Object Track 5 Point of Interest Longitudinal Position Covariance";
BA_ "SignalLongName" SG_ 120 SRRRRODPVOTk6PoILgPsCAuth "Serial Data 186 : Short Range Radar Right Rear Object Detection and Processing Vehicle Object Track 6 Point of Interest Longitudinal Position Covariance";
BA_ "SignalLongName" SG_ 120 SRRRRODPVOTk7PoILgPsCAuth "Serial Data 186 : Short Range Radar Right Rear Object Detection and Processing Vehicle Object Track 7 Point of Interest Longitudinal Position Covariance";
BA_ "SignalLongName" SG_ 120 SRRRRODPVOTk8PoILgPsCAuth "Serial Data 186 : Short Range Radar Right Rear Object Detection and Processing Vehicle Object Track 8 Point of Interest Longitudinal Position Covariance";
BA_ "SignalLongName" SG_ 120 SRRRRODPVOTk9PoILgPsCAuth "Serial Data 186 : Short Range Radar Right Rear Object Detection and Processing Vehicle Object Track 9 Point of Interest Longitudinal Position Covariance";
BA_ "SignalLongName" SG_ 120 SRRRRODPVOTk10PoILPsCAuth "Serial Data 186 : Short Range Radar Right Rear Object Detection and Processing Vehicle Object Track 10 Point of Interest Lateral Position Covariance";
BA_ "SignalLongName" SG_ 120 SRRRRODPVOTk1PoILPsCAuth "Serial Data 186 : Short Range Radar Right Rear Object Detection and Processing Vehicle Object Track 1 Point of Interest Lateral Position Covariance";
BA_ "SignalLongName" SG_ 120 SRRRRODPVOTk2PoILPsCAuth "Serial Data 186 : Short Range Radar Right Rear Object Detection and Processing Vehicle Object Track 2 Point of Interest Lateral Position Covariance";
BA_ "SignalLongName" SG_ 120 SRRRRODPVOTk3PoILPsCAuth "Serial Data 186 : Short Range Radar Right Rear Object Detection and Processing Vehicle Object Track 3 Point of Interest Lateral Position Covariance";
BA_ "SignalLongName" SG_ 120 SRRRRODPVOTk4PoILPsCAuth "Serial Data 186 : Short Range Radar Right Rear Object Detection and Processing Vehicle Object Track 4 Point of Interest Lateral Position Covariance";
BA_ "SignalLongName" SG_ 120 SRRRRODPVOTk5PoILPsCAuth "Serial Data 186 : Short Range Radar Right Rear Object Detection and Processing Vehicle Object Track 5 Point of Interest Lateral Position Covariance";
BA_ "SignalLongName" SG_ 120 SRRRRODPVOTk6PoILPsCAuth "Serial Data 186 : Short Range Radar Right Rear Object Detection and Processing Vehicle Object Track 6 Point of Interest Lateral Position Covariance";
BA_ "SignalLongName" SG_ 120 SRRRRODPVOTk7PoILPsCAuth "Serial Data 186 : Short Range Radar Right Rear Object Detection and Processing Vehicle Object Track 7 Point of Interest Lateral Position Covariance";
BA_ "SignalLongName" SG_ 120 SRRRRODPVOTk8PoILPsCAuth "Serial Data 186 : Short Range Radar Right Rear Object Detection and Processing Vehicle Object Track 8 Point of Interest Lateral Position Covariance";
BA_ "SignalLongName" SG_ 120 SRRRRODPVOTk9PoILPsCAuth "Serial Data 186 : Short Range Radar Right Rear Object Detection and Processing Vehicle Object Track 9 Point of Interest Lateral Position Covariance";
BA_ "SignalLongName" SG_ 120 SRRRRODPAcqTmStmAuth "Serial Data 186 : Short Range Radar Right Rear Object Detection and Processing Acquisition Time Stamp";
BA_ "SignalLongName" SG_ 120 SRRRRODPIOTk10PoILgPsAuth "Serial Data 186 : Short Range Radar Right Rear Object Detection and Processing Infrastructure Object Track 10 Point of Interest Longitudinal Position";
BA_ "SignalLongName" SG_ 120 SRRRRODPIOTk1PoILgPsAuth "Serial Data 186 : Short Range Radar Right Rear Object Detection and Processing Infrastructure Object Track 1 Point of Interest Longitudinal Position";
BA_ "SignalLongName" SG_ 120 SRRRRODPIOTk2PoILgPsAuth "Serial Data 186 : Short Range Radar Right Rear Object Detection and Processing Infrastructure Object Track 2 Point of Interest Longitudinal Position";
BA_ "SignalLongName" SG_ 120 SRRRRODPIOTk3PoILgPsAuth "Serial Data 186 : Short Range Radar Right Rear Object Detection and Processing Infrastructure Object Track 3 Point of Interest Longitudinal Position";
BA_ "SignalLongName" SG_ 120 SRRRRODPIOTk4PoILgPsAuth "Serial Data 186 : Short Range Radar Right Rear Object Detection and Processing Infrastructure Object Track 4 Point of Interest Longitudinal Position";
BA_ "SignalLongName" SG_ 120 SRRRRODPIOTk5PoILgPsAuth "Serial Data 186 : Short Range Radar Right Rear Object Detection and Processing Infrastructure Object Track 5 Point of Interest Longitudinal Position";
BA_ "SignalLongName" SG_ 120 SRRRRODPIOTk6PoILgPsAuth "Serial Data 186 : Short Range Radar Right Rear Object Detection and Processing Infrastructure Object Track 6 Point of Interest Longitudinal Position";
BA_ "SignalLongName" SG_ 120 SRRRRODPIOTk7PoILgPsAuth "Serial Data 186 : Short Range Radar Right Rear Object Detection and Processing Infrastructure Object Track 7 Point of Interest Longitudinal Position";
BA_ "SignalLongName" SG_ 120 SRRRRODPIOTk8PoILgPsAuth "Serial Data 186 : Short Range Radar Right Rear Object Detection and Processing Infrastructure Object Track 8 Point of Interest Longitudinal Position";
BA_ "SignalLongName" SG_ 120 SRRRRODPIOTk9PoILgPsAuth "Serial Data 186 : Short Range Radar Right Rear Object Detection and Processing Infrastructure Object Track 9 Point of Interest Longitudinal Position";
BA_ "SignalLongName" SG_ 120 SRRRRODPPOTk1PoILgPsAuth "Serial Data 186 : Short Range Radar Right Rear Object Detection and Processing Pedestrian Object Track 1 Point of Interest Longitudinal Position";
BA_ "SignalLongName" SG_ 120 SRRRRODPPOTk2PoILgPsAuth "Serial Data 186 : Short Range Radar Right Rear Object Detection and Processing Pedestrian Object Track 2 Point of Interest Longitudinal Position";
BA_ "SignalLongName" SG_ 120 SRRRRODPPOTk3PoILgPsAuth "Serial Data 186 : Short Range Radar Right Rear Object Detection and Processing Pedestrian Object Track 3 Point of Interest Longitudinal Position";
BA_ "SignalLongName" SG_ 120 SRRRRODPPOTk4PoILgPsAuth "Serial Data 186 : Short Range Radar Right Rear Object Detection and Processing Pedestrian Object Track 4 Point of Interest Longitudinal Position";
BA_ "SignalLongName" SG_ 120 SRRRRODPPOTk5PoILgPsAuth "Serial Data 186 : Short Range Radar Right Rear Object Detection and Processing Pedestrian Object Track 5 Point of Interest Longitudinal Position";
BA_ "SignalLongName" SG_ 120 SRRRRODPREOTk1PsEndAuth "Serial Data 186 : Short Range Radar Right Rear Object Detection and Processing Road Edge Object Track 1 Position End";
BA_ "SignalLongName" SG_ 120 SRRRRODPREOTk1PsStrtAuth "Serial Data 186 : Short Range Radar Right Rear Object Detection and Processing Road Edge Object Track 1 Position Start";
BA_ "SignalLongName" SG_ 120 SRRRRODPREOTk2PsEndAuth "Serial Data 186 : Short Range Radar Right Rear Object Detection and Processing Road Edge Object Track 2 Position End";
BA_ "SignalLongName" SG_ 120 SRRRRODPREOTk2PsStrtAuth "Serial Data 186 : Short Range Radar Right Rear Object Detection and Processing Road Edge Object Track 2 Position Start";
BA_ "SignalLongName" SG_ 120 SRRRRODPREOTk3PsEndAuth "Serial Data 186 : Short Range Radar Right Rear Object Detection and Processing Road Edge Object Track 3 Position End";
BA_ "SignalLongName" SG_ 120 SRRRRODPREOTk3PsStrtAuth "Serial Data 186 : Short Range Radar Right Rear Object Detection and Processing Road Edge Object Track 3 Position Start";
BA_ "SignalLongName" SG_ 120 SRRRRODPVOTk10PoI2LgPsAuth "Serial Data 186 : Short Range Radar Right Rear Object Detection and Processing Vehicle Object Track 10 Point of Interest 2nd Longitudinal Position";
BA_ "SignalLongName" SG_ 120 SRRRRODPVOTk10PoILgPsAuth "Serial Data 186 : Short Range Radar Right Rear Object Detection and Processing Vehicle Object Track 10 Point of Interest Longitudinal Position";
BA_ "SignalLongName" SG_ 120 SRRRRODPVOTk10PoILgVAuth "Serial Data 186 : Short Range Radar Right Rear Object Detection and Processing Vehicle Object Track 10 Point of Interest Longitudinal Velocity";
BA_ "SignalLongName" SG_ 120 SRRRRODPVOTk1PoI2LgPsAuth "Serial Data 186 : Short Range Radar Right Rear Object Detection and Processing Vehicle Object Track 1 Point of Interest 2nd Longitudinal Position";
BA_ "SignalLongName" SG_ 120 SRRRRODPVOTk1PoILgPsAuth "Serial Data 186 : Short Range Radar Right Rear Object Detection and Processing Vehicle Object Track 1 Point of Interest Longitudinal Position";
BA_ "SignalLongName" SG_ 120 SRRRRODPVOTk1PoILgVAuth "Serial Data 186 : Short Range Radar Right Rear Object Detection and Processing Vehicle Object Track 1 Point of Interest Longitudinal Velocity";
BA_ "SignalLongName" SG_ 120 SRRRRODPVOTk2PoI2LgPsAuth "Serial Data 186 : Short Range Radar Right Rear Object Detection and Processing Vehicle Object Track 2 Point of Interest 2nd Longitudinal Position";
BA_ "SignalLongName" SG_ 120 SRRRRODPVOTk2PoILgPsAuth "Serial Data 186 : Short Range Radar Right Rear Object Detection and Processing Vehicle Object Track 2 Point of Interest Longitudinal Position";
BA_ "SignalLongName" SG_ 120 SRRRRODPVOTk2PoILgVAuth "Serial Data 186 : Short Range Radar Right Rear Object Detection and Processing Vehicle Object Track 2 Point of Interest Longitudinal Velocity";
BA_ "SignalLongName" SG_ 120 SRRRRODPVOTk3PoI2LgPsAuth "Serial Data 186 : Short Range Radar Right Rear Object Detection and Processing Vehicle Object Track 3 Point of Interest 2nd Longitudinal Position";
BA_ "SignalLongName" SG_ 120 SRRRRODPVOTk3PoILgPsAuth "Serial Data 186 : Short Range Radar Right Rear Object Detection and Processing Vehicle Object Track 3 Point of Interest Longitudinal Position";
BA_ "SignalLongName" SG_ 120 SRRRRODPVOTk3PoILgVAuth "Serial Data 186 : Short Range Radar Right Rear Object Detection and Processing Vehicle Object Track 3 Point of Interest Longitudinal Velocity";
BA_ "SignalLongName" SG_ 120 SRRRRODPVOTk4PoI2LgPsAuth "Serial Data 186 : Short Range Radar Right Rear Object Detection and Processing Vehicle Object Track 4 Point of Interest 2nd Longitudinal Position";
BA_ "SignalLongName" SG_ 120 SRRRRODPVOTk4PoILgPsAuth "Serial Data 186 : Short Range Radar Right Rear Object Detection and Processing Vehicle Object Track 4 Point of Interest Longitudinal Position";
BA_ "SignalLongName" SG_ 120 SRRRRODPVOTk4PoILgVAuth "Serial Data 186 : Short Range Radar Right Rear Object Detection and Processing Vehicle Object Track 4 Point of Interest Longitudinal Velocity";
BA_ "SignalLongName" SG_ 120 SRRRRODPVOTk5PoI2LgPsAuth "Serial Data 186 : Short Range Radar Right Rear Object Detection and Processing Vehicle Object Track 5 Point of Interest 2nd Longitudinal Position";
BA_ "SignalLongName" SG_ 120 SRRRRODPVOTk5PoILgPsAuth "Serial Data 186 : Short Range Radar Right Rear Object Detection and Processing Vehicle Object Track 5 Point of Interest Longitudinal Position";
BA_ "SignalLongName" SG_ 120 SRRRRODPVOTk5PoILgVAuth "Serial Data 186 : Short Range Radar Right Rear Object Detection and Processing Vehicle Object Track 5 Point of Interest Longitudinal Velocity";
BA_ "SignalLongName" SG_ 120 SRRRRODPVOTk6PoI2LgPsAuth "Serial Data 186 : Short Range Radar Right Rear Object Detection and Processing Vehicle Object Track 6 Point of Interest 2nd Longitudinal Position";
BA_ "SignalLongName" SG_ 120 SRRRRODPVOTk6PoILgPsAuth "Serial Data 186 : Short Range Radar Right Rear Object Detection and Processing Vehicle Object Track 6 Point of Interest Longitudinal Position";
BA_ "SignalLongName" SG_ 120 SRRRRODPVOTk6PoILgVAuth "Serial Data 186 : Short Range Radar Right Rear Object Detection and Processing Vehicle Object Track 6 Point of Interest Longitudinal Velocity";
BA_ "SignalLongName" SG_ 120 SRRRRODPVOTk7PoI2LgPsAuth "Serial Data 186 : Short Range Radar Right Rear Object Detection and Processing Vehicle Object Track 7 Point of Interest 2nd Longitudinal Position";
BA_ "SignalLongName" SG_ 120 SRRRRODPVOTk7PoILgPsAuth "Serial Data 186 : Short Range Radar Right Rear Object Detection and Processing Vehicle Object Track 7 Point of Interest Longitudinal Position";
BA_ "SignalLongName" SG_ 120 SRRRRODPVOTk7PoILgVAuth "Serial Data 186 : Short Range Radar Right Rear Object Detection and Processing Vehicle Object Track 7 Point of Interest Longitudinal Velocity";
BA_ "SignalLongName" SG_ 120 SRRRRODPVOTk8PoI2LgPsAuth "Serial Data 186 : Short Range Radar Right Rear Object Detection and Processing Vehicle Object Track 8 Point of Interest 2nd Longitudinal Position";
BA_ "SignalLongName" SG_ 120 SRRRRODPVOTk8PoILgPsAuth "Serial Data 186 : Short Range Radar Right Rear Object Detection and Processing Vehicle Object Track 8 Point of Interest Longitudinal Position";
BA_ "SignalLongName" SG_ 120 SRRRRODPVOTk8PoILgVAuth "Serial Data 186 : Short Range Radar Right Rear Object Detection and Processing Vehicle Object Track 8 Point of Interest Longitudinal Velocity";
BA_ "SignalLongName" SG_ 120 SRRRRODPVOTk9PoI2LgPsAuth "Serial Data 186 : Short Range Radar Right Rear Object Detection and Processing Vehicle Object Track 9 Point of Interest 2nd Longitudinal Position";
BA_ "SignalLongName" SG_ 120 SRRRRODPVOTk9PoILgPsAuth "Serial Data 186 : Short Range Radar Right Rear Object Detection and Processing Vehicle Object Track 9 Point of Interest Longitudinal Position";
BA_ "SignalLongName" SG_ 120 SRRRRODPVOTk9PoILgVAuth "Serial Data 186 : Short Range Radar Right Rear Object Detection and Processing Vehicle Object Track 9 Point of Interest Longitudinal Velocity";
BA_ "SignalLongName" SG_ 120 SRRRRODPIOTk10PoILPsAuth "Serial Data 186 : Short Range Radar Right Rear Object Detection and Processing Infrastructure Object Track 10 Point of Interest Lateral Position";
BA_ "SignalLongName" SG_ 120 SRRRRODPIOTk1PoILPsAuth "Serial Data 186 : Short Range Radar Right Rear Object Detection and Processing Infrastructure Object Track 1 Point of Interest Lateral Position";
BA_ "SignalLongName" SG_ 120 SRRRRODPIOTk2PoILPsAuth "Serial Data 186 : Short Range Radar Right Rear Object Detection and Processing Infrastructure Object Track 2 Point of Interest Lateral Position";
BA_ "SignalLongName" SG_ 120 SRRRRODPIOTk3PoILPsAuth "Serial Data 186 : Short Range Radar Right Rear Object Detection and Processing Infrastructure Object Track 3 Point of Interest Lateral Position";
BA_ "SignalLongName" SG_ 120 SRRRRODPIOTk4PoILPsAuth "Serial Data 186 : Short Range Radar Right Rear Object Detection and Processing Infrastructure Object Track 4 Point of Interest Lateral Position";
BA_ "SignalLongName" SG_ 120 SRRRRODPIOTk5PoILPsAuth "Serial Data 186 : Short Range Radar Right Rear Object Detection and Processing Infrastructure Object Track 5 Point of Interest Lateral Position";
BA_ "SignalLongName" SG_ 120 SRRRRODPIOTk6PoILPsAuth "Serial Data 186 : Short Range Radar Right Rear Object Detection and Processing Infrastructure Object Track 6 Point of Interest Lateral Position";
BA_ "SignalLongName" SG_ 120 SRRRRODPIOTk7PoILPsAuth "Serial Data 186 : Short Range Radar Right Rear Object Detection and Processing Infrastructure Object Track 7 Point of Interest Lateral Position";
BA_ "SignalLongName" SG_ 120 SRRRRODPIOTk8PoILPsAuth "Serial Data 186 : Short Range Radar Right Rear Object Detection and Processing Infrastructure Object Track 8 Point of Interest Lateral Position";
BA_ "SignalLongName" SG_ 120 SRRRRODPIOTk9PoILPsAuth "Serial Data 186 : Short Range Radar Right Rear Object Detection and Processing Infrastructure Object Track 9 Point of Interest Lateral Position";
BA_ "SignalLongName" SG_ 120 SRRRRODPPOTk1PoILPsAuth "Serial Data 186 : Short Range Radar Right Rear Object Detection and Processing Pedestrian Object Track 1 Point of Interest Lateral Position";
BA_ "SignalLongName" SG_ 120 SRRRRODPPOTk1PoILgVAuth "Serial Data 186 : Short Range Radar Right Rear Object Detection and Processing Pedestrian Object Track 1 Point of Interest Longitudinal Velocity";
BA_ "SignalLongName" SG_ 120 SRRRRODPPOTk2PoILPsAuth "Serial Data 186 : Short Range Radar Right Rear Object Detection and Processing Pedestrian Object Track 2 Point of Interest Lateral Position";
BA_ "SignalLongName" SG_ 120 SRRRRODPPOTk2PoILgVAuth "Serial Data 186 : Short Range Radar Right Rear Object Detection and Processing Pedestrian Object Track 2 Point of Interest Longitudinal Velocity";
BA_ "SignalLongName" SG_ 120 SRRRRODPPOTk3PoILPsAuth "Serial Data 186 : Short Range Radar Right Rear Object Detection and Processing Pedestrian Object Track 3 Point of Interest Lateral Position";
BA_ "SignalLongName" SG_ 120 SRRRRODPPOTk3PoILgVAuth "Serial Data 186 : Short Range Radar Right Rear Object Detection and Processing Pedestrian Object Track 3 Point of Interest Longitudinal Velocity";
BA_ "SignalLongName" SG_ 120 SRRRRODPPOTk4PoILPsAuth "Serial Data 186 : Short Range Radar Right Rear Object Detection and Processing Pedestrian Object Track 4 Point of Interest Lateral Position";
BA_ "SignalLongName" SG_ 120 SRRRRODPPOTk4PoILgVAuth "Serial Data 186 : Short Range Radar Right Rear Object Detection and Processing Pedestrian Object Track 4 Point of Interest Longitudinal Velocity";
BA_ "SignalLongName" SG_ 120 SRRRRODPPOTk5PoILPsAuth "Serial Data 186 : Short Range Radar Right Rear Object Detection and Processing Pedestrian Object Track 5 Point of Interest Lateral Position";
BA_ "SignalLongName" SG_ 120 SRRRRODPPOTk5PoILgVAuth "Serial Data 186 : Short Range Radar Right Rear Object Detection and Processing Pedestrian Object Track 5 Point of Interest Longitudinal Velocity";
BA_ "SignalLongName" SG_ 120 SRRRRODPREOTk1HdgAuth "Serial Data 186 : Short Range Radar Right Rear Object Detection and Processing Road Edge Object Track 1 Heading";
BA_ "SignalLongName" SG_ 120 SRRRRODPREOTk2HdgAuth "Serial Data 186 : Short Range Radar Right Rear Object Detection and Processing Road Edge Object Track 2 Heading";
BA_ "SignalLongName" SG_ 120 SRRRRODPREOTk3HdgAuth "Serial Data 186 : Short Range Radar Right Rear Object Detection and Processing Road Edge Object Track 3 Heading";
BA_ "SignalLongName" SG_ 120 SRRRRODPVOTk10PoI2LPsAuth "Serial Data 186 : Short Range Radar Right Rear Object Detection and Processing Vehicle Object Track 10 Point of Interest 2nd Lateral Position";
BA_ "SignalLongName" SG_ 120 SRRRRODPVOTk10PoILPsAuth "Serial Data 186 : Short Range Radar Right Rear Object Detection and Processing Vehicle Object Track 10 Point of Interest Lateral Position";
BA_ "SignalLongName" SG_ 120 SRRRRODPVOTk10PoILVCAuth "Serial Data 186 : Short Range Radar Right Rear Object Detection and Processing Vehicle Object Track 10 Point of Interest Lateral Velocity Covariance";
BA_ "SignalLongName" SG_ 120 SRRRRODPVOTk10PoILgVCAuth "Serial Data 186 : Short Range Radar Right Rear Object Detection and Processing Vehicle Object Track 10 Point of Interest Longitudinal Velocity Covariance";
BA_ "SignalLongName" SG_ 120 SRRRRODPVOTk1PoI2LPsAuth "Serial Data 186 : Short Range Radar Right Rear Object Detection and Processing Vehicle Object Track 1 Point of Interest 2nd Lateral Position";
BA_ "SignalLongName" SG_ 120 SRRRRODPVOTk1PoILPsAuth "Serial Data 186 : Short Range Radar Right Rear Object Detection and Processing Vehicle Object Track 1 Point of Interest Lateral Position";
BA_ "SignalLongName" SG_ 120 SRRRRODPVOTk1PoILVCAuth "Serial Data 186 : Short Range Radar Right Rear Object Detection and Processing Vehicle Object Track 1 Point of Interest Lateral Velocity Covariance";
BA_ "SignalLongName" SG_ 120 SRRRRODPVOTk1PoILgVCAuth "Serial Data 186 : Short Range Radar Right Rear Object Detection and Processing Vehicle Object Track 1 Point of Interest Longitudinal Velocity Covariance";
BA_ "SignalLongName" SG_ 120 SRRRRODPVOTk2PoI2LPsAuth "Serial Data 186 : Short Range Radar Right Rear Object Detection and Processing Vehicle Object Track 2 Point of Interest 2nd Lateral Position";
BA_ "SignalLongName" SG_ 120 SRRRRODPVOTk2PoILPsAuth "Serial Data 186 : Short Range Radar Right Rear Object Detection and Processing Vehicle Object Track 2 Point of Interest Lateral Position";
BA_ "SignalLongName" SG_ 120 SRRRRODPVOTk2PoILVCAuth "Serial Data 186 : Short Range Radar Right Rear Object Detection and Processing Vehicle Object Track 2 Point of Interest Lateral Velocity Covariance";
BA_ "SignalLongName" SG_ 120 SRRRRODPVOTk2PoILgVCAuth "Serial Data 186 : Short Range Radar Right Rear Object Detection and Processing Vehicle Object Track 2 Point of Interest Longitudinal Velocity Covariance";
BA_ "SignalLongName" SG_ 120 SRRRRODPVOTk3PoI2LPsAuth "Serial Data 186 : Short Range Radar Right Rear Object Detection and Processing Vehicle Object Track 3 Point of Interest 2nd Lateral Position";
BA_ "SignalLongName" SG_ 120 SRRRRODPVOTk3PoILPsAuth "Serial Data 186 : Short Range Radar Right Rear Object Detection and Processing Vehicle Object Track 3 Point of Interest Lateral Position";
BA_ "SignalLongName" SG_ 120 SRRRRODPVOTk3PoILVCAuth "Serial Data 186 : Short Range Radar Right Rear Object Detection and Processing Vehicle Object Track 3 Point of Interest Lateral Velocity Covariance";
BA_ "SignalLongName" SG_ 120 SRRRRODPVOTk3PoILgVCAuth "Serial Data 186 : Short Range Radar Right Rear Object Detection and Processing Vehicle Object Track 3 Point of Interest Longitudinal Velocity Covariance";
BA_ "SignalLongName" SG_ 120 SRRRRODPVOTk4PoI2LPsAuth "Serial Data 186 : Short Range Radar Right Rear Object Detection and Processing Vehicle Object Track 4 Point of Interest 2nd Lateral Position";
BA_ "SignalLongName" SG_ 120 SRRRRODPVOTk4PoILPsAuth "Serial Data 186 : Short Range Radar Right Rear Object Detection and Processing Vehicle Object Track 4 Point of Interest Lateral Position";
BA_ "SignalLongName" SG_ 120 SRRRRODPVOTk4PoILVCAuth "Serial Data 186 : Short Range Radar Right Rear Object Detection and Processing Vehicle Object Track 4 Point of Interest Lateral Velocity Covariance";
BA_ "SignalLongName" SG_ 120 SRRRRODPVOTk4PoILgVCAuth "Serial Data 186 : Short Range Radar Right Rear Object Detection and Processing Vehicle Object Track 4 Point of Interest Longitudinal Velocity Covariance";
BA_ "SignalLongName" SG_ 120 SRRRRODPVOTk5PoI2LPsAuth "Serial Data 186 : Short Range Radar Right Rear Object Detection and Processing Vehicle Object Track 5 Point of Interest 2nd Lateral Position";
BA_ "SignalLongName" SG_ 120 SRRRRODPVOTk5PoILPsAuth "Serial Data 186 : Short Range Radar Right Rear Object Detection and Processing Vehicle Object Track 5 Point of Interest Lateral Position";
BA_ "SignalLongName" SG_ 120 SRRRRODPVOTk5PoILVCAuth "Serial Data 186 : Short Range Radar Right Rear Object Detection and Processing Vehicle Object Track 5 Point of Interest Lateral Velocity Covariance";
BA_ "SignalLongName" SG_ 120 SRRRRODPVOTk5PoILgVCAuth "Serial Data 186 : Short Range Radar Right Rear Object Detection and Processing Vehicle Object Track 5 Point of Interest Longitudinal Velocity Covariance";
BA_ "SignalLongName" SG_ 120 SRRRRODPVOTk6PoI2LPsAuth "Serial Data 186 : Short Range Radar Right Rear Object Detection and Processing Vehicle Object Track 6 Point of Interest 2nd Lateral Position";
BA_ "SignalLongName" SG_ 120 SRRRRODPVOTk6PoILPsAuth "Serial Data 186 : Short Range Radar Right Rear Object Detection and Processing Vehicle Object Track 6 Point of Interest Lateral Position";
BA_ "SignalLongName" SG_ 120 SRRRRODPVOTk6PoILVCAuth "Serial Data 186 : Short Range Radar Right Rear Object Detection and Processing Vehicle Object Track 6 Point of Interest Lateral Velocity Covariance";
BA_ "SignalLongName" SG_ 120 SRRRRODPVOTk6PoILgVCAuth "Serial Data 186 : Short Range Radar Right Rear Object Detection and Processing Vehicle Object Track 6 Point of Interest Longitudinal Velocity Covariance";
BA_ "SignalLongName" SG_ 120 SRRRRODPVOTk7PoI2LPsAuth "Serial Data 186 : Short Range Radar Right Rear Object Detection and Processing Vehicle Object Track 7 Point of Interest 2nd Lateral Position";
BA_ "SignalLongName" SG_ 120 SRRRRODPVOTk7PoILPsAuth "Serial Data 186 : Short Range Radar Right Rear Object Detection and Processing Vehicle Object Track 7 Point of Interest Lateral Position";
BA_ "SignalLongName" SG_ 120 SRRRRODPVOTk7PoILVCAuth "Serial Data 186 : Short Range Radar Right Rear Object Detection and Processing Vehicle Object Track 7 Point of Interest Lateral Velocity Covariance";
BA_ "SignalLongName" SG_ 120 SRRRRODPVOTk7PoILgVCAuth "Serial Data 186 : Short Range Radar Right Rear Object Detection and Processing Vehicle Object Track 7 Point of Interest Longitudinal Velocity Covariance";
BA_ "SignalLongName" SG_ 120 SRRRRODPVOTk8PoI2LPsAuth "Serial Data 186 : Short Range Radar Right Rear Object Detection and Processing Vehicle Object Track 8 Point of Interest 2nd Lateral Position";
BA_ "SignalLongName" SG_ 120 SRRRRODPVOTk8PoILPsAuth "Serial Data 186 : Short Range Radar Right Rear Object Detection and Processing Vehicle Object Track 8 Point of Interest Lateral Position";
BA_ "SignalLongName" SG_ 120 SRRRRODPVOTk8PoILVCAuth "Serial Data 186 : Short Range Radar Right Rear Object Detection and Processing Vehicle Object Track 8 Point of Interest Lateral Velocity Covariance";
BA_ "SignalLongName" SG_ 120 SRRRRODPVOTk8PoILgVCAuth "Serial Data 186 : Short Range Radar Right Rear Object Detection and Processing Vehicle Object Track 8 Point of Interest Longitudinal Velocity Covariance";
BA_ "SignalLongName" SG_ 120 SRRRRODPVOTk9PoI2LPsAuth "Serial Data 186 : Short Range Radar Right Rear Object Detection and Processing Vehicle Object Track 9 Point of Interest 2nd Lateral Position";
BA_ "SignalLongName" SG_ 120 SRRRRODPVOTk9PoILPsAuth "Serial Data 186 : Short Range Radar Right Rear Object Detection and Processing Vehicle Object Track 9 Point of Interest Lateral Position";
BA_ "SignalLongName" SG_ 120 SRRRRODPVOTk9PoILVCAuth "Serial Data 186 : Short Range Radar Right Rear Object Detection and Processing Vehicle Object Track 9 Point of Interest Lateral Velocity Covariance";
BA_ "SignalLongName" SG_ 120 SRRRRODPVOTk9PoILgVCAuth "Serial Data 186 : Short Range Radar Right Rear Object Detection and Processing Vehicle Object Track 9 Point of Interest Longitudinal Velocity Covariance";
BA_ "SignalLongName" SG_ 120 SRRRRODPPOTk1PoILAAuth "Serial Data 186 : Short Range Radar Right Rear Object Detection and Processing Pedestrian Object Track 1 Point of Interest Lateral Acceleration";
BA_ "SignalLongName" SG_ 120 SRRRRODPPOTk1PoILVAuth "Serial Data 186 : Short Range Radar Right Rear Object Detection and Processing Pedestrian Object Track 1 Point of Interest Lateral Velocity";
BA_ "SignalLongName" SG_ 120 SRRRRODPPOTk1PoILgAAuth "Serial Data 186 : Short Range Radar Right Rear Object Detection and Processing Pedestrian Object Track 1 Point of Interest Longitudinal Acceleration";
BA_ "SignalLongName" SG_ 120 SRRRRODPPOTk2PoILAAuth "Serial Data 186 : Short Range Radar Right Rear Object Detection and Processing Pedestrian Object Track 2 Point of Interest Lateral Acceleration";
BA_ "SignalLongName" SG_ 120 SRRRRODPPOTk2PoILVAuth "Serial Data 186 : Short Range Radar Right Rear Object Detection and Processing Pedestrian Object Track 2 Point of Interest Lateral Velocity";
BA_ "SignalLongName" SG_ 120 SRRRRODPPOTk2PoILgAAuth "Serial Data 186 : Short Range Radar Right Rear Object Detection and Processing Pedestrian Object Track 2 Point of Interest Longitudinal Acceleration";
BA_ "SignalLongName" SG_ 120 SRRRRODPPOTk3PoILAAuth "Serial Data 186 : Short Range Radar Right Rear Object Detection and Processing Pedestrian Object Track 3 Point of Interest Lateral Acceleration";
BA_ "SignalLongName" SG_ 120 SRRRRODPPOTk3PoILVAuth "Serial Data 186 : Short Range Radar Right Rear Object Detection and Processing Pedestrian Object Track 3 Point of Interest Lateral Velocity";
BA_ "SignalLongName" SG_ 120 SRRRRODPPOTk3PoILgAAuth "Serial Data 186 : Short Range Radar Right Rear Object Detection and Processing Pedestrian Object Track 3 Point of Interest Longitudinal Acceleration";
BA_ "SignalLongName" SG_ 120 SRRRRODPPOTk4PoILAAuth "Serial Data 186 : Short Range Radar Right Rear Object Detection and Processing Pedestrian Object Track 4 Point of Interest Lateral Acceleration";
BA_ "SignalLongName" SG_ 120 SRRRRODPPOTk4PoILVAuth "Serial Data 186 : Short Range Radar Right Rear Object Detection and Processing Pedestrian Object Track 4 Point of Interest Lateral Velocity";
BA_ "SignalLongName" SG_ 120 SRRRRODPPOTk4PoILgAAuth "Serial Data 186 : Short Range Radar Right Rear Object Detection and Processing Pedestrian Object Track 4 Point of Interest Longitudinal Acceleration";
BA_ "SignalLongName" SG_ 120 SRRRRODPPOTk5PoILAAuth "Serial Data 186 : Short Range Radar Right Rear Object Detection and Processing Pedestrian Object Track 5 Point of Interest Lateral Acceleration";
BA_ "SignalLongName" SG_ 120 SRRRRODPPOTk5PoILVAuth "Serial Data 186 : Short Range Radar Right Rear Object Detection and Processing Pedestrian Object Track 5 Point of Interest Lateral Velocity";
BA_ "SignalLongName" SG_ 120 SRRRRODPPOTk5PoILgAAuth "Serial Data 186 : Short Range Radar Right Rear Object Detection and Processing Pedestrian Object Track 5 Point of Interest Longitudinal Acceleration";
BA_ "SignalLongName" SG_ 120 SRRRRODPREOTk1OfstAuth "Serial Data 186 : Short Range Radar Right Rear Object Detection and Processing Road Edge Object Track 1 Offset";
BA_ "SignalLongName" SG_ 120 SRRRRODPREOTk2OfstAuth "Serial Data 186 : Short Range Radar Right Rear Object Detection and Processing Road Edge Object Track 2 Offset";
BA_ "SignalLongName" SG_ 120 SRRRRODPREOTk3OfstAuth "Serial Data 186 : Short Range Radar Right Rear Object Detection and Processing Road Edge Object Track 3 Offset";
BA_ "SignalLongName" SG_ 120 SRRRRODPVOTk10PoILAAuth "Serial Data 186 : Short Range Radar Right Rear Object Detection and Processing Vehicle Object Track 10 Point of Interest Lateral Acceleration";
BA_ "SignalLongName" SG_ 120 SRRRRODPVOTk10PoILVAuth "Serial Data 186 : Short Range Radar Right Rear Object Detection and Processing Vehicle Object Track 10 Point of Interest Lateral Velocity";
BA_ "SignalLongName" SG_ 120 SRRRRODPVOTk10PoILgAAuth "Serial Data 186 : Short Range Radar Right Rear Object Detection and Processing Vehicle Object Track 10 Point of Interest Longitudinal Acceleration";
BA_ "SignalLongName" SG_ 120 SRRRRODPVOTk1PoILAAuth "Serial Data 186 : Short Range Radar Right Rear Object Detection and Processing Vehicle Object Track 1 Point of Interest Lateral Acceleration";
BA_ "SignalLongName" SG_ 120 SRRRRODPVOTk1PoILVAuth "Serial Data 186 : Short Range Radar Right Rear Object Detection and Processing Vehicle Object Track 1 Point of Interest Lateral Velocity";
BA_ "SignalLongName" SG_ 120 SRRRRODPVOTk1PoILgAAuth "Serial Data 186 : Short Range Radar Right Rear Object Detection and Processing Vehicle Object Track 1 Point of Interest Longitudinal Acceleration";
BA_ "SignalLongName" SG_ 120 SRRRRODPVOTk2PoILAAuth "Serial Data 186 : Short Range Radar Right Rear Object Detection and Processing Vehicle Object Track 2 Point of Interest Lateral Acceleration";
BA_ "SignalLongName" SG_ 120 SRRRRODPVOTk2PoILVAuth "Serial Data 186 : Short Range Radar Right Rear Object Detection and Processing Vehicle Object Track 2 Point of Interest Lateral Velocity";
BA_ "SignalLongName" SG_ 120 SRRRRODPVOTk2PoILgAAuth "Serial Data 186 : Short Range Radar Right Rear Object Detection and Processing Vehicle Object Track 2 Point of Interest Longitudinal Acceleration";
BA_ "SignalLongName" SG_ 120 SRRRRODPVOTk3PoILAAuth "Serial Data 186 : Short Range Radar Right Rear Object Detection and Processing Vehicle Object Track 3 Point of Interest Lateral Acceleration";
BA_ "SignalLongName" SG_ 120 SRRRRODPVOTk3PoILVAuth "Serial Data 186 : Short Range Radar Right Rear Object Detection and Processing Vehicle Object Track 3 Point of Interest Lateral Velocity";
BA_ "SignalLongName" SG_ 120 SRRRRODPVOTk3PoILgAAuth "Serial Data 186 : Short Range Radar Right Rear Object Detection and Processing Vehicle Object Track 3 Point of Interest Longitudinal Acceleration";
BA_ "SignalLongName" SG_ 120 SRRRRODPVOTk4PoILAAuth "Serial Data 186 : Short Range Radar Right Rear Object Detection and Processing Vehicle Object Track 4 Point of Interest Lateral Acceleration";
BA_ "SignalLongName" SG_ 120 SRRRRODPVOTk4PoILVAuth "Serial Data 186 : Short Range Radar Right Rear Object Detection and Processing Vehicle Object Track 4 Point of Interest Lateral Velocity";
BA_ "SignalLongName" SG_ 120 SRRRRODPVOTk4PoILgAAuth "Serial Data 186 : Short Range Radar Right Rear Object Detection and Processing Vehicle Object Track 4 Point of Interest Longitudinal Acceleration";
BA_ "SignalLongName" SG_ 120 SRRRRODPVOTk5PoILAAuth "Serial Data 186 : Short Range Radar Right Rear Object Detection and Processing Vehicle Object Track 5 Point of Interest Lateral Acceleration";
BA_ "SignalLongName" SG_ 120 SRRRRODPVOTk5PoILVAuth "Serial Data 186 : Short Range Radar Right Rear Object Detection and Processing Vehicle Object Track 5 Point of Interest Lateral Velocity";
BA_ "SignalLongName" SG_ 120 SRRRRODPVOTk5PoILgAAuth "Serial Data 186 : Short Range Radar Right Rear Object Detection and Processing Vehicle Object Track 5 Point of Interest Longitudinal Acceleration";
BA_ "SignalLongName" SG_ 120 SRRRRODPVOTk6PoILAAuth "Serial Data 186 : Short Range Radar Right Rear Object Detection and Processing Vehicle Object Track 6 Point of Interest Lateral Acceleration";
BA_ "SignalLongName" SG_ 120 SRRRRODPVOTk6PoILVAuth "Serial Data 186 : Short Range Radar Right Rear Object Detection and Processing Vehicle Object Track 6 Point of Interest Lateral Velocity";
BA_ "SignalLongName" SG_ 120 SRRRRODPVOTk6PoILgAAuth "Serial Data 186 : Short Range Radar Right Rear Object Detection and Processing Vehicle Object Track 6 Point of Interest Longitudinal Acceleration";
BA_ "SignalLongName" SG_ 120 SRRRRODPVOTk7PoILAAuth "Serial Data 186 : Short Range Radar Right Rear Object Detection and Processing Vehicle Object Track 7 Point of Interest Lateral Acceleration";
BA_ "SignalLongName" SG_ 120 SRRRRODPVOTk7PoILVAuth "Serial Data 186 : Short Range Radar Right Rear Object Detection and Processing Vehicle Object Track 7 Point of Interest Lateral Velocity";
BA_ "SignalLongName" SG_ 120 SRRRRODPVOTk7PoILgAAuth "Serial Data 186 : Short Range Radar Right Rear Object Detection and Processing Vehicle Object Track 7 Point of Interest Longitudinal Acceleration";
BA_ "SignalLongName" SG_ 120 SRRRRODPVOTk8PoILAAuth "Serial Data 186 : Short Range Radar Right Rear Object Detection and Processing Vehicle Object Track 8 Point of Interest Lateral Acceleration";
BA_ "SignalLongName" SG_ 120 SRRRRODPVOTk8PoILVAuth "Serial Data 186 : Short Range Radar Right Rear Object Detection and Processing Vehicle Object Track 8 Point of Interest Lateral Velocity";
BA_ "SignalLongName" SG_ 120 SRRRRODPVOTk8PoILgAAuth "Serial Data 186 : Short Range Radar Right Rear Object Detection and Processing Vehicle Object Track 8 Point of Interest Longitudinal Acceleration";
BA_ "SignalLongName" SG_ 120 SRRRRODPVOTk9PoILAAuth "Serial Data 186 : Short Range Radar Right Rear Object Detection and Processing Vehicle Object Track 9 Point of Interest Lateral Acceleration";
BA_ "SignalLongName" SG_ 120 SRRRRODPVOTk9PoILVAuth "Serial Data 186 : Short Range Radar Right Rear Object Detection and Processing Vehicle Object Track 9 Point of Interest Lateral Velocity";
BA_ "SignalLongName" SG_ 120 SRRRRODPVOTk9PoILgAAuth "Serial Data 186 : Short Range Radar Right Rear Object Detection and Processing Vehicle Object Track 9 Point of Interest Longitudinal Acceleration";
BA_ "SignalLongName" SG_ 120 SRRRRODPVOTk10PoILgthAuth "Serial Data 186 : Short Range Radar Right Rear Object Detection and Processing Vehicle Object Track 10 Point of Interest Length";
BA_ "SignalLongName" SG_ 120 SRRRRODPVOTk1PoILgthAuth "Serial Data 186 : Short Range Radar Right Rear Object Detection and Processing Vehicle Object Track 1 Point of Interest Length";
BA_ "SignalLongName" SG_ 120 SRRRRODPVOTk2PoILgthAuth "Serial Data 186 : Short Range Radar Right Rear Object Detection and Processing Vehicle Object Track 2 Point of Interest Length";
BA_ "SignalLongName" SG_ 120 SRRRRODPVOTk3PoILgthAuth "Serial Data 186 : Short Range Radar Right Rear Object Detection and Processing Vehicle Object Track 3 Point of Interest Length";
BA_ "SignalLongName" SG_ 120 SRRRRODPVOTk4PoILgthAuth "Serial Data 186 : Short Range Radar Right Rear Object Detection and Processing Vehicle Object Track 4 Point of Interest Length";
BA_ "SignalLongName" SG_ 120 SRRRRODPVOTk5PoILgthAuth "Serial Data 186 : Short Range Radar Right Rear Object Detection and Processing Vehicle Object Track 5 Point of Interest Length";
BA_ "SignalLongName" SG_ 120 SRRRRODPVOTk6PoILgthAuth "Serial Data 186 : Short Range Radar Right Rear Object Detection and Processing Vehicle Object Track 6 Point of Interest Length";
BA_ "SignalLongName" SG_ 120 SRRRRODPVOTk7PoILgthAuth "Serial Data 186 : Short Range Radar Right Rear Object Detection and Processing Vehicle Object Track 7 Point of Interest Length";
BA_ "SignalLongName" SG_ 120 SRRRRODPVOTk8PoILgthAuth "Serial Data 186 : Short Range Radar Right Rear Object Detection and Processing Vehicle Object Track 8 Point of Interest Length";
BA_ "SignalLongName" SG_ 120 SRRRRODPVOTk9PoILgthAuth "Serial Data 186 : Short Range Radar Right Rear Object Detection and Processing Vehicle Object Track 9 Point of Interest Length";
BA_ "SignalLongName" SG_ 120 SRRRRODPIOTk10IDAuth "Serial Data 186 : Short Range Radar Right Rear Object Detection and Processing Infrastructure Object Track 10 ID";
BA_ "SignalLongName" SG_ 120 SRRRRODPIOTk1IDAuth "Serial Data 186 : Short Range Radar Right Rear Object Detection and Processing Infrastructure Object Track 1 ID";
BA_ "SignalLongName" SG_ 120 SRRRRODPIOTk2IDAuth "Serial Data 186 : Short Range Radar Right Rear Object Detection and Processing Infrastructure Object Track 2 ID";
BA_ "SignalLongName" SG_ 120 SRRRRODPIOTk3IDAuth "Serial Data 186 : Short Range Radar Right Rear Object Detection and Processing Infrastructure Object Track 3 ID";
BA_ "SignalLongName" SG_ 120 SRRRRODPIOTk4IDAuth "Serial Data 186 : Short Range Radar Right Rear Object Detection and Processing Infrastructure Object Track 4 ID";
BA_ "SignalLongName" SG_ 120 SRRRRODPIOTk5IDAuth "Serial Data 186 : Short Range Radar Right Rear Object Detection and Processing Infrastructure Object Track 5 ID";
BA_ "SignalLongName" SG_ 120 SRRRRODPIOTk6IDAuth "Serial Data 186 : Short Range Radar Right Rear Object Detection and Processing Infrastructure Object Track 6 ID";
BA_ "SignalLongName" SG_ 120 SRRRRODPIOTk7IDAuth "Serial Data 186 : Short Range Radar Right Rear Object Detection and Processing Infrastructure Object Track 7 ID";
BA_ "SignalLongName" SG_ 120 SRRRRODPIOTk8IDAuth "Serial Data 186 : Short Range Radar Right Rear Object Detection and Processing Infrastructure Object Track 8 ID";
BA_ "SignalLongName" SG_ 120 SRRRRODPIOTk9IDAuth "Serial Data 186 : Short Range Radar Right Rear Object Detection and Processing Infrastructure Object Track 9 ID";
BA_ "SignalLongName" SG_ 120 SRRRRODPPOTk1IDAuth "Serial Data 186 : Short Range Radar Right Rear Object Detection and Processing Pedestrian Object Track 1 ID";
BA_ "SignalLongName" SG_ 120 SRRRRODPPOTk2IDAuth "Serial Data 186 : Short Range Radar Right Rear Object Detection and Processing Pedestrian Object Track 2 ID";
BA_ "SignalLongName" SG_ 120 SRRRRODPPOTk3IDAuth "Serial Data 186 : Short Range Radar Right Rear Object Detection and Processing Pedestrian Object Track 3 ID";
BA_ "SignalLongName" SG_ 120 SRRRRODPPOTk4IDAuth "Serial Data 186 : Short Range Radar Right Rear Object Detection and Processing Pedestrian Object Track 4 ID";
BA_ "SignalLongName" SG_ 120 SRRRRODPPOTk5IDAuth "Serial Data 186 : Short Range Radar Right Rear Object Detection and Processing Pedestrian Object Track 5 ID";
BA_ "SignalLongName" SG_ 120 SRRRRODPVOTk10IDAuth "Serial Data 186 : Short Range Radar Right Rear Object Detection and Processing Vehicle Object Track 10 ID";
BA_ "SignalLongName" SG_ 120 SRRRRODPVOTk1IDAuth "Serial Data 186 : Short Range Radar Right Rear Object Detection and Processing Vehicle Object Track 1 ID";
BA_ "SignalLongName" SG_ 120 SRRRRODPVOTk2IDAuth "Serial Data 186 : Short Range Radar Right Rear Object Detection and Processing Vehicle Object Track 2 ID";
BA_ "SignalLongName" SG_ 120 SRRRRODPVOTk3IDAuth "Serial Data 186 : Short Range Radar Right Rear Object Detection and Processing Vehicle Object Track 3 ID";
BA_ "SignalLongName" SG_ 120 SRRRRODPVOTk4IDAuth "Serial Data 186 : Short Range Radar Right Rear Object Detection and Processing Vehicle Object Track 4 ID";
BA_ "SignalLongName" SG_ 120 SRRRRODPVOTk5IDAuth "Serial Data 186 : Short Range Radar Right Rear Object Detection and Processing Vehicle Object Track 5 ID";
BA_ "SignalLongName" SG_ 120 SRRRRODPVOTk6IDAuth "Serial Data 186 : Short Range Radar Right Rear Object Detection and Processing Vehicle Object Track 6 ID";
BA_ "SignalLongName" SG_ 120 SRRRRODPVOTk7IDAuth "Serial Data 186 : Short Range Radar Right Rear Object Detection and Processing Vehicle Object Track 7 ID";
BA_ "SignalLongName" SG_ 120 SRRRRODPVOTk8IDAuth "Serial Data 186 : Short Range Radar Right Rear Object Detection and Processing Vehicle Object Track 8 ID";
BA_ "SignalLongName" SG_ 120 SRRRRODPVOTk9IDAuth "Serial Data 186 : Short Range Radar Right Rear Object Detection and Processing Vehicle Object Track 9 ID";
BA_ "SignalLongName" SG_ 120 SRRRRODPPOTk1InPthPotAuth "Serial Data 186 : Short Range Radar Right Rear Object Detection and Processing Pedestrian Object Track 1 In Path Potential";
BA_ "SignalLongName" SG_ 120 SRRRRODPPOTk2InPthPotAuth "Serial Data 186 : Short Range Radar Right Rear Object Detection and Processing Pedestrian Object Track 2 In Path Potential";
BA_ "SignalLongName" SG_ 120 SRRRRODPPOTk3InPthPotAuth "Serial Data 186 : Short Range Radar Right Rear Object Detection and Processing Pedestrian Object Track 3 In Path Potential";
BA_ "SignalLongName" SG_ 120 SRRRRODPPOTk4InPthPotAuth "Serial Data 186 : Short Range Radar Right Rear Object Detection and Processing Pedestrian Object Track 4 In Path Potential";
BA_ "SignalLongName" SG_ 120 SRRRRODPPOTk5InPthPotAuth "Serial Data 186 : Short Range Radar Right Rear Object Detection and Processing Pedestrian Object Track 5 In Path Potential";
BA_ "SignalLongName" SG_ 120 SRRRRODPVOTk10CICOPotAuth "Serial Data 186 : Short Range Radar Right Rear Object Detection and Processing Vehicle Object Track 10 Cut In Cut Out Potential";
BA_ "SignalLongName" SG_ 120 SRRRRODPVOTk1CICOPotAuth "Serial Data 186 : Short Range Radar Right Rear Object Detection and Processing Vehicle Object Track 1 Cut In Cut Out Potential";
BA_ "SignalLongName" SG_ 120 SRRRRODPVOTk2CICOPotAuth "Serial Data 186 : Short Range Radar Right Rear Object Detection and Processing Vehicle Object Track 2 Cut In Cut Out Potential";
BA_ "SignalLongName" SG_ 120 SRRRRODPVOTk3CICOPotAuth "Serial Data 186 : Short Range Radar Right Rear Object Detection and Processing Vehicle Object Track 3 Cut In Cut Out Potential";
BA_ "SignalLongName" SG_ 120 SRRRRODPVOTk4CICOPotAuth "Serial Data 186 : Short Range Radar Right Rear Object Detection and Processing Vehicle Object Track 4 Cut In Cut Out Potential";
BA_ "SignalLongName" SG_ 120 SRRRRODPVOTk5CICOPotAuth "Serial Data 186 : Short Range Radar Right Rear Object Detection and Processing Vehicle Object Track 5 Cut In Cut Out Potential";
BA_ "SignalLongName" SG_ 120 SRRRRODPVOTk6CICOPotAuth "Serial Data 186 : Short Range Radar Right Rear Object Detection and Processing Vehicle Object Track 6 Cut In Cut Out Potential";
BA_ "SignalLongName" SG_ 120 SRRRRODPVOTk7CICOPotAuth "Serial Data 186 : Short Range Radar Right Rear Object Detection and Processing Vehicle Object Track 7 Cut In Cut Out Potential";
BA_ "SignalLongName" SG_ 120 SRRRRODPVOTk8CICOPotAuth "Serial Data 186 : Short Range Radar Right Rear Object Detection and Processing Vehicle Object Track 8 Cut In Cut Out Potential";
BA_ "SignalLongName" SG_ 120 SRRRRODPVOTk9CICOPotAuth "Serial Data 186 : Short Range Radar Right Rear Object Detection and Processing Vehicle Object Track 9 Cut In Cut Out Potential";
BA_ "SignalType" SG_ 120 SRRRRODPIOTk10TypAuth "ENM";
BA_ "SignalLongName" SG_ 120 SRRRRODPIOTk10TypAuth "Serial Data 186 : Short Range Radar Right Rear Object Detection and Processing Infrastructure Object Track 10 Type";
BA_ "SignalType" SG_ 120 SRRRRODPIOTk1TypAuth "ENM";
BA_ "SignalLongName" SG_ 120 SRRRRODPIOTk1TypAuth "Serial Data 186 : Short Range Radar Right Rear Object Detection and Processing Infrastructure Object Track 1 Type";
BA_ "SignalType" SG_ 120 SRRRRODPIOTk2TypAuth "ENM";
BA_ "SignalLongName" SG_ 120 SRRRRODPIOTk2TypAuth "Serial Data 186 : Short Range Radar Right Rear Object Detection and Processing Infrastructure Object Track 2 Type";
BA_ "SignalType" SG_ 120 SRRRRODPIOTk3TypAuth "ENM";
BA_ "SignalLongName" SG_ 120 SRRRRODPIOTk3TypAuth "Serial Data 186 : Short Range Radar Right Rear Object Detection and Processing Infrastructure Object Track 3 Type";
BA_ "SignalType" SG_ 120 SRRRRODPIOTk4TypAuth "ENM";
BA_ "SignalLongName" SG_ 120 SRRRRODPIOTk4TypAuth "Serial Data 186 : Short Range Radar Right Rear Object Detection and Processing Infrastructure Object Track 4 Type";
BA_ "SignalType" SG_ 120 SRRRRODPIOTk5TypAuth "ENM";
BA_ "SignalLongName" SG_ 120 SRRRRODPIOTk5TypAuth "Serial Data 186 : Short Range Radar Right Rear Object Detection and Processing Infrastructure Object Track 5 Type";
BA_ "SignalType" SG_ 120 SRRRRODPIOTk6TypAuth "ENM";
BA_ "SignalLongName" SG_ 120 SRRRRODPIOTk6TypAuth "Serial Data 186 : Short Range Radar Right Rear Object Detection and Processing Infrastructure Object Track 6 Type";
BA_ "SignalType" SG_ 120 SRRRRODPIOTk7TypAuth "ENM";
BA_ "SignalLongName" SG_ 120 SRRRRODPIOTk7TypAuth "Serial Data 186 : Short Range Radar Right Rear Object Detection and Processing Infrastructure Object Track 7 Type";
BA_ "SignalType" SG_ 120 SRRRRODPIOTk8TypAuth "ENM";
BA_ "SignalLongName" SG_ 120 SRRRRODPIOTk8TypAuth "Serial Data 186 : Short Range Radar Right Rear Object Detection and Processing Infrastructure Object Track 8 Type";
BA_ "SignalType" SG_ 120 SRRRRODPIOTk9TypAuth "ENM";
BA_ "SignalLongName" SG_ 120 SRRRRODPIOTk9TypAuth "Serial Data 186 : Short Range Radar Right Rear Object Detection and Processing Infrastructure Object Track 9 Type";
BA_ "SignalType" SG_ 120 SRRRRODPPOTk1DynPrpAuth "ENM";
BA_ "SignalLongName" SG_ 120 SRRRRODPPOTk1DynPrpAuth "Serial Data 186 : Short Range Radar Right Rear Object Detection and Processing Pedestrian Object Track 1 Dynamic Property";
BA_ "SignalType" SG_ 120 SRRRRODPPOTk2DynPrpAuth "ENM";
BA_ "SignalLongName" SG_ 120 SRRRRODPPOTk2DynPrpAuth "Serial Data 186 : Short Range Radar Right Rear Object Detection and Processing Pedestrian Object Track 2 Dynamic Property";
BA_ "SignalType" SG_ 120 SRRRRODPPOTk3DynPrpAuth "ENM";
BA_ "SignalLongName" SG_ 120 SRRRRODPPOTk3DynPrpAuth "Serial Data 186 : Short Range Radar Right Rear Object Detection and Processing Pedestrian Object Track 3 Dynamic Property";
BA_ "SignalType" SG_ 120 SRRRRODPPOTk4DynPrpAuth "ENM";
BA_ "SignalLongName" SG_ 120 SRRRRODPPOTk4DynPrpAuth "Serial Data 186 : Short Range Radar Right Rear Object Detection and Processing Pedestrian Object Track 4 Dynamic Property";
BA_ "SignalType" SG_ 120 SRRRRODPPOTk5DynPrpAuth "ENM";
BA_ "SignalLongName" SG_ 120 SRRRRODPPOTk5DynPrpAuth "Serial Data 186 : Short Range Radar Right Rear Object Detection and Processing Pedestrian Object Track 5 Dynamic Property";
BA_ "SignalType" SG_ 120 SRRRRODPREOTk1TypAuth "ENM";
BA_ "SignalLongName" SG_ 120 SRRRRODPREOTk1TypAuth "Serial Data 186 : Short Range Radar Right Rear Object Detection and Processing Road Edge Object Track 1 Type";
BA_ "SignalType" SG_ 120 SRRRRODPREOTk2TypAuth "ENM";
BA_ "SignalLongName" SG_ 120 SRRRRODPREOTk2TypAuth "Serial Data 186 : Short Range Radar Right Rear Object Detection and Processing Road Edge Object Track 2 Type";
BA_ "SignalType" SG_ 120 SRRRRODPREOTk3TypAuth "ENM";
BA_ "SignalLongName" SG_ 120 SRRRRODPREOTk3TypAuth "Serial Data 186 : Short Range Radar Right Rear Object Detection and Processing Road Edge Object Track 3 Type";
BA_ "SignalType" SG_ 120 SRRRRODPRdTypAuth "ENM";
BA_ "SignalLongName" SG_ 120 SRRRRODPRdTypAuth "Serial Data 186 : Short Range Radar Right Rear Object Detection and Processing Road Type";
BA_ "SignalType" SG_ 120 SRRRRODPVOTk10DynPrpAuth "ENM";
BA_ "SignalLongName" SG_ 120 SRRRRODPVOTk10DynPrpAuth "Serial Data 186 : Short Range Radar Right Rear Object Detection and Processing Vehicle Object Track 10 Dynamic Property";
BA_ "SignalType" SG_ 120 SRRRRODPVOTk1DynPrpAuth "ENM";
BA_ "SignalLongName" SG_ 120 SRRRRODPVOTk1DynPrpAuth "Serial Data 186 : Short Range Radar Right Rear Object Detection and Processing Vehicle Object Track 1 Dynamic Property";
BA_ "SignalType" SG_ 120 SRRRRODPVOTk2DynPrpAuth "ENM";
BA_ "SignalLongName" SG_ 120 SRRRRODPVOTk2DynPrpAuth "Serial Data 186 : Short Range Radar Right Rear Object Detection and Processing Vehicle Object Track 2 Dynamic Property";
BA_ "SignalType" SG_ 120 SRRRRODPVOTk3DynPrpAuth "ENM";
BA_ "SignalLongName" SG_ 120 SRRRRODPVOTk3DynPrpAuth "Serial Data 186 : Short Range Radar Right Rear Object Detection and Processing Vehicle Object Track 3 Dynamic Property";
BA_ "SignalType" SG_ 120 SRRRRODPVOTk4DynPrpAuth "ENM";
BA_ "SignalLongName" SG_ 120 SRRRRODPVOTk4DynPrpAuth "Serial Data 186 : Short Range Radar Right Rear Object Detection and Processing Vehicle Object Track 4 Dynamic Property";
BA_ "SignalType" SG_ 120 SRRRRODPVOTk5DynPrpAuth "ENM";
BA_ "SignalLongName" SG_ 120 SRRRRODPVOTk5DynPrpAuth "Serial Data 186 : Short Range Radar Right Rear Object Detection and Processing Vehicle Object Track 5 Dynamic Property";
BA_ "SignalType" SG_ 120 SRRRRODPVOTk6DynPrpAuth "ENM";
BA_ "SignalLongName" SG_ 120 SRRRRODPVOTk6DynPrpAuth "Serial Data 186 : Short Range Radar Right Rear Object Detection and Processing Vehicle Object Track 6 Dynamic Property";
BA_ "SignalType" SG_ 120 SRRRRODPVOTk7DynPrpAuth "ENM";
BA_ "SignalLongName" SG_ 120 SRRRRODPVOTk7DynPrpAuth "Serial Data 186 : Short Range Radar Right Rear Object Detection and Processing Vehicle Object Track 7 Dynamic Property";
BA_ "SignalType" SG_ 120 SRRRRODPVOTk8DynPrpAuth "ENM";
BA_ "SignalLongName" SG_ 120 SRRRRODPVOTk8DynPrpAuth "Serial Data 186 : Short Range Radar Right Rear Object Detection and Processing Vehicle Object Track 8 Dynamic Property";
BA_ "SignalType" SG_ 120 SRRRRODPVOTk9DynPrpAuth "ENM";
BA_ "SignalLongName" SG_ 120 SRRRRODPVOTk9DynPrpAuth "Serial Data 186 : Short Range Radar Right Rear Object Detection and Processing Vehicle Object Track 9 Dynamic Property";
BA_ "SignalType" SG_ 120 SRRRRODPConstrArDtnCnfdAuth "ENM";
BA_ "SignalLongName" SG_ 120 SRRRRODPConstrArDtnCnfdAuth "Serial Data 186 : Short Range Radar Right Rear Object Detection and Processing Construction Area Detection Confidence";
BA_ "SignalType" SG_ 120 SRRRRODPConstrArDtnStsAuth "ENM";
BA_ "SignalLongName" SG_ 120 SRRRRODPConstrArDtnStsAuth "Serial Data 186 : Short Range Radar Right Rear Object Detection and Processing Construction Area Detection Status";
BA_ "SignalType" SG_ 120 SRRRRODPIOTk10CnfdStsAuth "ENM";
BA_ "SignalLongName" SG_ 120 SRRRRODPIOTk10CnfdStsAuth "Serial Data 186 : Short Range Radar Right Rear Object Detection and Processing Infrastructure Object Track 10 Confidence Status";
BA_ "SignalType" SG_ 120 SRRRRODPIOTk10ElvtnAuth "ENM";
BA_ "SignalLongName" SG_ 120 SRRRRODPIOTk10ElvtnAuth "Serial Data 186 : Short Range Radar Right Rear Object Detection and Processing Infrastructure Object Track 10 Elevation";
BA_ "SignalType" SG_ 120 SRRRRODPIOTk10MStsAuth "ENM";
BA_ "SignalLongName" SG_ 120 SRRRRODPIOTk10MStsAuth "Serial Data 186 : Short Range Radar Right Rear Object Detection and Processing Infrastructure Object Track 10 Measurement Status";
BA_ "SignalType" SG_ 120 SRRRRODPIOTk10TypCnfdAuth "ENM";
BA_ "SignalLongName" SG_ 120 SRRRRODPIOTk10TypCnfdAuth "Serial Data 186 : Short Range Radar Right Rear Object Detection and Processing Infrastructure Object Track 10 Type Confidence";
BA_ "SignalType" SG_ 120 SRRRRODPIOTk1CnfdStsAuth "ENM";
BA_ "SignalLongName" SG_ 120 SRRRRODPIOTk1CnfdStsAuth "Serial Data 186 : Short Range Radar Right Rear Object Detection and Processing Infrastructure Object Track 1 Confidence Status";
BA_ "SignalType" SG_ 120 SRRRRODPIOTk1ElvtnAuth "ENM";
BA_ "SignalLongName" SG_ 120 SRRRRODPIOTk1ElvtnAuth "Serial Data 186 : Short Range Radar Right Rear Object Detection and Processing Infrastructure Object Track 1 Elevation";
BA_ "SignalType" SG_ 120 SRRRRODPIOTk1MStsAuth "ENM";
BA_ "SignalLongName" SG_ 120 SRRRRODPIOTk1MStsAuth "Serial Data 186 : Short Range Radar Right Rear Object Detection and Processing Infrastructure Object Track 1 Measurement Status";
BA_ "SignalType" SG_ 120 SRRRRODPIOTk1TypCnfdAuth "ENM";
BA_ "SignalLongName" SG_ 120 SRRRRODPIOTk1TypCnfdAuth "Serial Data 186 : Short Range Radar Right Rear Object Detection and Processing Infrastructure Object Track 1 Type Confidence";
BA_ "SignalType" SG_ 120 SRRRRODPIOTk2CnfdStsAuth "ENM";
BA_ "SignalLongName" SG_ 120 SRRRRODPIOTk2CnfdStsAuth "Serial Data 186 : Short Range Radar Right Rear Object Detection and Processing Infrastructure Object Track 2 Confidence Status";
BA_ "SignalType" SG_ 120 SRRRRODPIOTk2ElvtnAuth "ENM";
BA_ "SignalLongName" SG_ 120 SRRRRODPIOTk2ElvtnAuth "Serial Data 186 : Short Range Radar Right Rear Object Detection and Processing Infrastructure Object Track 2 Elevation";
BA_ "SignalType" SG_ 120 SRRRRODPIOTk2MStsAuth "ENM";
BA_ "SignalLongName" SG_ 120 SRRRRODPIOTk2MStsAuth "Serial Data 186 : Short Range Radar Right Rear Object Detection and Processing Infrastructure Object Track 2 Measurement Status";
BA_ "SignalType" SG_ 120 SRRRRODPIOTk2TypCnfdAuth "ENM";
BA_ "SignalLongName" SG_ 120 SRRRRODPIOTk2TypCnfdAuth "Serial Data 186 : Short Range Radar Right Rear Object Detection and Processing Infrastructure Object Track 2 Type Confidence";
BA_ "SignalType" SG_ 120 SRRRRODPIOTk3CnfdStsAuth "ENM";
BA_ "SignalLongName" SG_ 120 SRRRRODPIOTk3CnfdStsAuth "Serial Data 186 : Short Range Radar Right Rear Object Detection and Processing Infrastructure Object Track 3 Confidence Status";
BA_ "SignalType" SG_ 120 SRRRRODPIOTk3ElvtnAuth "ENM";
BA_ "SignalLongName" SG_ 120 SRRRRODPIOTk3ElvtnAuth "Serial Data 186 : Short Range Radar Right Rear Object Detection and Processing Infrastructure Object Track 3 Elevation";
BA_ "SignalType" SG_ 120 SRRRRODPIOTk3MStsAuth "ENM";
BA_ "SignalLongName" SG_ 120 SRRRRODPIOTk3MStsAuth "Serial Data 186 : Short Range Radar Right Rear Object Detection and Processing Infrastructure Object Track 3 Measurement Status";
BA_ "SignalType" SG_ 120 SRRRRODPIOTk3TypCnfdAuth "ENM";
BA_ "SignalLongName" SG_ 120 SRRRRODPIOTk3TypCnfdAuth "Serial Data 186 : Short Range Radar Right Rear Object Detection and Processing Infrastructure Object Track 3 Type Confidence";
BA_ "SignalType" SG_ 120 SRRRRODPIOTk4CnfdStsAuth "ENM";
BA_ "SignalLongName" SG_ 120 SRRRRODPIOTk4CnfdStsAuth "Serial Data 186 : Short Range Radar Right Rear Object Detection and Processing Infrastructure Object Track 4 Confidence Status";
BA_ "SignalType" SG_ 120 SRRRRODPIOTk4ElvtnAuth "ENM";
BA_ "SignalLongName" SG_ 120 SRRRRODPIOTk4ElvtnAuth "Serial Data 186 : Short Range Radar Right Rear Object Detection and Processing Infrastructure Object Track 4 Elevation";
BA_ "SignalType" SG_ 120 SRRRRODPIOTk4MStsAuth "ENM";
BA_ "SignalLongName" SG_ 120 SRRRRODPIOTk4MStsAuth "Serial Data 186 : Short Range Radar Right Rear Object Detection and Processing Infrastructure Object Track 4 Measurement Status";
BA_ "SignalType" SG_ 120 SRRRRODPIOTk4TypCnfdAuth "ENM";
BA_ "SignalLongName" SG_ 120 SRRRRODPIOTk4TypCnfdAuth "Serial Data 186 : Short Range Radar Right Rear Object Detection and Processing Infrastructure Object Track 4 Type Confidence";
BA_ "SignalType" SG_ 120 SRRRRODPIOTk5CnfdStsAuth "ENM";
BA_ "SignalLongName" SG_ 120 SRRRRODPIOTk5CnfdStsAuth "Serial Data 186 : Short Range Radar Right Rear Object Detection and Processing Infrastructure Object Track 5 Confidence Status";
BA_ "SignalType" SG_ 120 SRRRRODPIOTk5ElvtnAuth "ENM";
BA_ "SignalLongName" SG_ 120 SRRRRODPIOTk5ElvtnAuth "Serial Data 186 : Short Range Radar Right Rear Object Detection and Processing Infrastructure Object Track 5 Elevation";
BA_ "SignalType" SG_ 120 SRRRRODPIOTk5MStsAuth "ENM";
BA_ "SignalLongName" SG_ 120 SRRRRODPIOTk5MStsAuth "Serial Data 186 : Short Range Radar Right Rear Object Detection and Processing Infrastructure Object Track 5 Measurement Status";
BA_ "SignalType" SG_ 120 SRRRRODPIOTk5TypCnfdAuth "ENM";
BA_ "SignalLongName" SG_ 120 SRRRRODPIOTk5TypCnfdAuth "Serial Data 186 : Short Range Radar Right Rear Object Detection and Processing Infrastructure Object Track 5 Type Confidence";
BA_ "SignalType" SG_ 120 SRRRRODPIOTk6CnfdStsAuth "ENM";
BA_ "SignalLongName" SG_ 120 SRRRRODPIOTk6CnfdStsAuth "Serial Data 186 : Short Range Radar Right Rear Object Detection and Processing Infrastructure Object Track 6 Confidence Status";
BA_ "SignalType" SG_ 120 SRRRRODPIOTk6ElvtnAuth "ENM";
BA_ "SignalLongName" SG_ 120 SRRRRODPIOTk6ElvtnAuth "Serial Data 186 : Short Range Radar Right Rear Object Detection and Processing Infrastructure Object Track 6 Elevation";
BA_ "SignalType" SG_ 120 SRRRRODPIOTk6MStsAuth "ENM";
BA_ "SignalLongName" SG_ 120 SRRRRODPIOTk6MStsAuth "Serial Data 186 : Short Range Radar Right Rear Object Detection and Processing Infrastructure Object Track 6 Measurement Status";
BA_ "SignalType" SG_ 120 SRRRRODPIOTk6TypCnfdAuth "ENM";
BA_ "SignalLongName" SG_ 120 SRRRRODPIOTk6TypCnfdAuth "Serial Data 186 : Short Range Radar Right Rear Object Detection and Processing Infrastructure Object Track 6 Type Confidence";
BA_ "SignalType" SG_ 120 SRRRRODPIOTk7CnfdStsAuth "ENM";
BA_ "SignalLongName" SG_ 120 SRRRRODPIOTk7CnfdStsAuth "Serial Data 186 : Short Range Radar Right Rear Object Detection and Processing Infrastructure Object Track 7 Confidence Status";
BA_ "SignalType" SG_ 120 SRRRRODPIOTk7ElvtnAuth "ENM";
BA_ "SignalLongName" SG_ 120 SRRRRODPIOTk7ElvtnAuth "Serial Data 186 : Short Range Radar Right Rear Object Detection and Processing Infrastructure Object Track 7 Elevation";
BA_ "SignalType" SG_ 120 SRRRRODPIOTk7MStsAuth "ENM";
BA_ "SignalLongName" SG_ 120 SRRRRODPIOTk7MStsAuth "Serial Data 186 : Short Range Radar Right Rear Object Detection and Processing Infrastructure Object Track 7 Measurement Status";
BA_ "SignalType" SG_ 120 SRRRRODPIOTk7TypCnfdAuth "ENM";
BA_ "SignalLongName" SG_ 120 SRRRRODPIOTk7TypCnfdAuth "Serial Data 186 : Short Range Radar Right Rear Object Detection and Processing Infrastructure Object Track 7 Type Confidence";
BA_ "SignalType" SG_ 120 SRRRRODPIOTk8CnfdStsAuth "ENM";
BA_ "SignalLongName" SG_ 120 SRRRRODPIOTk8CnfdStsAuth "Serial Data 186 : Short Range Radar Right Rear Object Detection and Processing Infrastructure Object Track 8 Confidence Status";
BA_ "SignalType" SG_ 120 SRRRRODPIOTk8ElvtnAuth "ENM";
BA_ "SignalLongName" SG_ 120 SRRRRODPIOTk8ElvtnAuth "Serial Data 186 : Short Range Radar Right Rear Object Detection and Processing Infrastructure Object Track 8 Elevation";
BA_ "SignalType" SG_ 120 SRRRRODPIOTk8MStsAuth "ENM";
BA_ "SignalLongName" SG_ 120 SRRRRODPIOTk8MStsAuth "Serial Data 186 : Short Range Radar Right Rear Object Detection and Processing Infrastructure Object Track 8 Measurement Status";
BA_ "SignalType" SG_ 120 SRRRRODPIOTk8TypCnfdAuth "ENM";
BA_ "SignalLongName" SG_ 120 SRRRRODPIOTk8TypCnfdAuth "Serial Data 186 : Short Range Radar Right Rear Object Detection and Processing Infrastructure Object Track 8 Type Confidence";
BA_ "SignalType" SG_ 120 SRRRRODPIOTk9CnfdStsAuth "ENM";
BA_ "SignalLongName" SG_ 120 SRRRRODPIOTk9CnfdStsAuth "Serial Data 186 : Short Range Radar Right Rear Object Detection and Processing Infrastructure Object Track 9 Confidence Status";
BA_ "SignalType" SG_ 120 SRRRRODPIOTk9ElvtnAuth "ENM";
BA_ "SignalLongName" SG_ 120 SRRRRODPIOTk9ElvtnAuth "Serial Data 186 : Short Range Radar Right Rear Object Detection and Processing Infrastructure Object Track 9 Elevation";
BA_ "SignalType" SG_ 120 SRRRRODPIOTk9MStsAuth "ENM";
BA_ "SignalLongName" SG_ 120 SRRRRODPIOTk9MStsAuth "Serial Data 186 : Short Range Radar Right Rear Object Detection and Processing Infrastructure Object Track 9 Measurement Status";
BA_ "SignalType" SG_ 120 SRRRRODPIOTk9TypCnfdAuth "ENM";
BA_ "SignalLongName" SG_ 120 SRRRRODPIOTk9TypCnfdAuth "Serial Data 186 : Short Range Radar Right Rear Object Detection and Processing Infrastructure Object Track 9 Type Confidence";
BA_ "SignalType" SG_ 120 SRRRRODPMdCmdStsAuth "ENM";
BA_ "SignalLongName" SG_ 120 SRRRRODPMdCmdStsAuth "Serial Data 186 : Short Range Radar Right Rear Object Detection and Processing Mode Command Status";
BA_ "SignalType" SG_ 120 SRRRRODPPOTk1CnfdStsAuth "ENM";
BA_ "SignalLongName" SG_ 120 SRRRRODPPOTk1CnfdStsAuth "Serial Data 186 : Short Range Radar Right Rear Object Detection and Processing Pedestrian Object Track 1 Confidence Status";
BA_ "SignalType" SG_ 120 SRRRRODPPOTk1MStsAuth "ENM";
BA_ "SignalLongName" SG_ 120 SRRRRODPPOTk1MStsAuth "Serial Data 186 : Short Range Radar Right Rear Object Detection and Processing Pedestrian Object Track 1 Measurement Status";
BA_ "SignalType" SG_ 120 SRRRRODPPOTk1TypAuth "ENM";
BA_ "SignalLongName" SG_ 120 SRRRRODPPOTk1TypAuth "Serial Data 186 : Short Range Radar Right Rear Object Detection and Processing Pedestrian Object Track 1 Type";
BA_ "SignalType" SG_ 120 SRRRRODPPOTk1TypCnfdAuth "ENM";
BA_ "SignalLongName" SG_ 120 SRRRRODPPOTk1TypCnfdAuth "Serial Data 186 : Short Range Radar Right Rear Object Detection and Processing Pedestrian Object Track 1 Type Confidence";
BA_ "SignalType" SG_ 120 SRRRRODPPOTk2CnfdStsAuth "ENM";
BA_ "SignalLongName" SG_ 120 SRRRRODPPOTk2CnfdStsAuth "Serial Data 186 : Short Range Radar Right Rear Object Detection and Processing Pedestrian Object Track 2 Confidence Status";
BA_ "SignalType" SG_ 120 SRRRRODPPOTk2MStsAuth "ENM";
BA_ "SignalLongName" SG_ 120 SRRRRODPPOTk2MStsAuth "Serial Data 186 : Short Range Radar Right Rear Object Detection and Processing Pedestrian Object Track 2 Measurement Status";
BA_ "SignalType" SG_ 120 SRRRRODPPOTk2TypAuth "ENM";
BA_ "SignalLongName" SG_ 120 SRRRRODPPOTk2TypAuth "Serial Data 186 : Short Range Radar Right Rear Object Detection and Processing Pedestrian Object Track 2 Type";
BA_ "SignalType" SG_ 120 SRRRRODPPOTk2TypCnfdAuth "ENM";
BA_ "SignalLongName" SG_ 120 SRRRRODPPOTk2TypCnfdAuth "Serial Data 186 : Short Range Radar Right Rear Object Detection and Processing Pedestrian Object Track 2 Type Confidence";
BA_ "SignalType" SG_ 120 SRRRRODPPOTk3CnfdStsAuth "ENM";
BA_ "SignalLongName" SG_ 120 SRRRRODPPOTk3CnfdStsAuth "Serial Data 186 : Short Range Radar Right Rear Object Detection and Processing Pedestrian Object Track 3 Confidence Status";
BA_ "SignalType" SG_ 120 SRRRRODPPOTk3MStsAuth "ENM";
BA_ "SignalLongName" SG_ 120 SRRRRODPPOTk3MStsAuth "Serial Data 186 : Short Range Radar Right Rear Object Detection and Processing Pedestrian Object Track 3 Measurement Status";
BA_ "SignalType" SG_ 120 SRRRRODPPOTk3TypAuth "ENM";
BA_ "SignalLongName" SG_ 120 SRRRRODPPOTk3TypAuth "Serial Data 186 : Short Range Radar Right Rear Object Detection and Processing Pedestrian Object Track 3 Type";
BA_ "SignalType" SG_ 120 SRRRRODPPOTk3TypCnfdAuth "ENM";
BA_ "SignalLongName" SG_ 120 SRRRRODPPOTk3TypCnfdAuth "Serial Data 186 : Short Range Radar Right Rear Object Detection and Processing Pedestrian Object Track 3 Type Confidence";
BA_ "SignalType" SG_ 120 SRRRRODPPOTk4CnfdStsAuth "ENM";
BA_ "SignalLongName" SG_ 120 SRRRRODPPOTk4CnfdStsAuth "Serial Data 186 : Short Range Radar Right Rear Object Detection and Processing Pedestrian Object Track 4 Confidence Status";
BA_ "SignalType" SG_ 120 SRRRRODPPOTk4MStsAuth "ENM";
BA_ "SignalLongName" SG_ 120 SRRRRODPPOTk4MStsAuth "Serial Data 186 : Short Range Radar Right Rear Object Detection and Processing Pedestrian Object Track 4 Measurement Status";
BA_ "SignalType" SG_ 120 SRRRRODPPOTk4TypAuth "ENM";
BA_ "SignalLongName" SG_ 120 SRRRRODPPOTk4TypAuth "Serial Data 186 : Short Range Radar Right Rear Object Detection and Processing Pedestrian Object Track 4 Type";
BA_ "SignalType" SG_ 120 SRRRRODPPOTk4TypCnfdAuth "ENM";
BA_ "SignalLongName" SG_ 120 SRRRRODPPOTk4TypCnfdAuth "Serial Data 186 : Short Range Radar Right Rear Object Detection and Processing Pedestrian Object Track 4 Type Confidence";
BA_ "SignalType" SG_ 120 SRRRRODPPOTk5CnfdStsAuth "ENM";
BA_ "SignalLongName" SG_ 120 SRRRRODPPOTk5CnfdStsAuth "Serial Data 186 : Short Range Radar Right Rear Object Detection and Processing Pedestrian Object Track 5 Confidence Status";
BA_ "SignalType" SG_ 120 SRRRRODPPOTk5MStsAuth "ENM";
BA_ "SignalLongName" SG_ 120 SRRRRODPPOTk5MStsAuth "Serial Data 186 : Short Range Radar Right Rear Object Detection and Processing Pedestrian Object Track 5 Measurement Status";
BA_ "SignalType" SG_ 120 SRRRRODPPOTk5TypAuth "ENM";
BA_ "SignalLongName" SG_ 120 SRRRRODPPOTk5TypAuth "Serial Data 186 : Short Range Radar Right Rear Object Detection and Processing Pedestrian Object Track 5 Type";
BA_ "SignalType" SG_ 120 SRRRRODPPOTk5TypCnfdAuth "ENM";
BA_ "SignalLongName" SG_ 120 SRRRRODPPOTk5TypCnfdAuth "Serial Data 186 : Short Range Radar Right Rear Object Detection and Processing Pedestrian Object Track 5 Type Confidence";
BA_ "SignalType" SG_ 120 SRRRRODPREOTk1CnfdStsAuth "ENM";
BA_ "SignalLongName" SG_ 120 SRRRRODPREOTk1CnfdStsAuth "Serial Data 186 : Short Range Radar Right Rear Object Detection and Processing Road Edge Object Track 1 Confidence Status";
BA_ "SignalType" SG_ 120 SRRRRODPREOTk1TypCnfdAuth "ENM";
BA_ "SignalLongName" SG_ 120 SRRRRODPREOTk1TypCnfdAuth "Serial Data 186 : Short Range Radar Right Rear Object Detection and Processing Road Edge Object Track 1 Type Confidence";
BA_ "SignalType" SG_ 120 SRRRRODPREOTk2CnfdStsAuth "ENM";
BA_ "SignalLongName" SG_ 120 SRRRRODPREOTk2CnfdStsAuth "Serial Data 186 : Short Range Radar Right Rear Object Detection and Processing Road Edge Object Track 2 Confidence Status";
BA_ "SignalType" SG_ 120 SRRRRODPREOTk2TypCnfdAuth "ENM";
BA_ "SignalLongName" SG_ 120 SRRRRODPREOTk2TypCnfdAuth "Serial Data 186 : Short Range Radar Right Rear Object Detection and Processing Road Edge Object Track 2 Type Confidence";
BA_ "SignalType" SG_ 120 SRRRRODPREOTk3CnfdStsAuth "ENM";
BA_ "SignalLongName" SG_ 120 SRRRRODPREOTk3CnfdStsAuth "Serial Data 186 : Short Range Radar Right Rear Object Detection and Processing Road Edge Object Track 3 Confidence Status";
BA_ "SignalType" SG_ 120 SRRRRODPREOTk3TypCnfdAuth "ENM";
BA_ "SignalLongName" SG_ 120 SRRRRODPREOTk3TypCnfdAuth "Serial Data 186 : Short Range Radar Right Rear Object Detection and Processing Road Edge Object Track 3 Type Confidence";
BA_ "SignalType" SG_ 120 SRRRRODPRdTypCnfdAuth "ENM";
BA_ "SignalLongName" SG_ 120 SRRRRODPRdTypCnfdAuth "Serial Data 186 : Short Range Radar Right Rear Object Detection and Processing Road Type Confidence";
BA_ "SignalType" SG_ 120 SRRRRODPSwpBndwdthStsAuth "ENM";
BA_ "SignalLongName" SG_ 120 SRRRRODPSwpBndwdthStsAuth "Serial Data 186 : Short Range Radar Right Rear Object Detection and Processing Sweep Bandwidth Status";
BA_ "SignalType" SG_ 120 SRRRRODPVOTk10CnfdStsAuth "ENM";
BA_ "SignalLongName" SG_ 120 SRRRRODPVOTk10CnfdStsAuth "Serial Data 186 : Short Range Radar Right Rear Object Detection and Processing Vehicle Object Track 10 Confidence Status";
BA_ "SignalType" SG_ 120 SRRRRODPVOTk10MStsAuth "ENM";
BA_ "SignalLongName" SG_ 120 SRRRRODPVOTk10MStsAuth "Serial Data 186 : Short Range Radar Right Rear Object Detection and Processing Vehicle Object Track 10 Measurement Status";
BA_ "SignalType" SG_ 120 SRRRRODPVOTk10TypCnfdAuth "ENM";
BA_ "SignalLongName" SG_ 120 SRRRRODPVOTk10TypCnfdAuth "Serial Data 186 : Short Range Radar Right Rear Object Detection and Processing Vehicle Object Track 10 Type Confidence";
BA_ "SignalType" SG_ 120 SRRRRODPVOTk1CnfdStsAuth "ENM";
BA_ "SignalLongName" SG_ 120 SRRRRODPVOTk1CnfdStsAuth "Serial Data 186 : Short Range Radar Right Rear Object Detection and Processing Vehicle Object Track 1 Confidence Status";
BA_ "SignalType" SG_ 120 SRRRRODPVOTk1MStsAuth "ENM";
BA_ "SignalLongName" SG_ 120 SRRRRODPVOTk1MStsAuth "Serial Data 186 : Short Range Radar Right Rear Object Detection and Processing Vehicle Object Track 1 Measurement Status";
BA_ "SignalType" SG_ 120 SRRRRODPVOTk1TypCnfdAuth "ENM";
BA_ "SignalLongName" SG_ 120 SRRRRODPVOTk1TypCnfdAuth "Serial Data 186 : Short Range Radar Right Rear Object Detection and Processing Vehicle Object Track 1 Type Confidence";
BA_ "SignalType" SG_ 120 SRRRRODPVOTk2CnfdStsAuth "ENM";
BA_ "SignalLongName" SG_ 120 SRRRRODPVOTk2CnfdStsAuth "Serial Data 186 : Short Range Radar Right Rear Object Detection and Processing Vehicle Object Track 2 Confidence Status";
BA_ "SignalType" SG_ 120 SRRRRODPVOTk2MStsAuth "ENM";
BA_ "SignalLongName" SG_ 120 SRRRRODPVOTk2MStsAuth "Serial Data 186 : Short Range Radar Right Rear Object Detection and Processing Vehicle Object Track 2 Measurement Status";
BA_ "SignalType" SG_ 120 SRRRRODPVOTk2TypCnfdAuth "ENM";
BA_ "SignalLongName" SG_ 120 SRRRRODPVOTk2TypCnfdAuth "Serial Data 186 : Short Range Radar Right Rear Object Detection and Processing Vehicle Object Track 2 Type Confidence";
BA_ "SignalType" SG_ 120 SRRRRODPVOTk3CnfdStsAuth "ENM";
BA_ "SignalLongName" SG_ 120 SRRRRODPVOTk3CnfdStsAuth "Serial Data 186 : Short Range Radar Right Rear Object Detection and Processing Vehicle Object Track 3 Confidence Status";
BA_ "SignalType" SG_ 120 SRRRRODPVOTk3MStsAuth "ENM";
BA_ "SignalLongName" SG_ 120 SRRRRODPVOTk3MStsAuth "Serial Data 186 : Short Range Radar Right Rear Object Detection and Processing Vehicle Object Track 3 Measurement Status";
BA_ "SignalType" SG_ 120 SRRRRODPVOTk3TypCnfdAuth "ENM";
BA_ "SignalLongName" SG_ 120 SRRRRODPVOTk3TypCnfdAuth "Serial Data 186 : Short Range Radar Right Rear Object Detection and Processing Vehicle Object Track 3 Type Confidence";
BA_ "SignalType" SG_ 120 SRRRRODPVOTk4CnfdStsAuth "ENM";
BA_ "SignalLongName" SG_ 120 SRRRRODPVOTk4CnfdStsAuth "Serial Data 186 : Short Range Radar Right Rear Object Detection and Processing Vehicle Object Track 4 Confidence Status";
BA_ "SignalType" SG_ 120 SRRRRODPVOTk4MStsAuth "ENM";
BA_ "SignalLongName" SG_ 120 SRRRRODPVOTk4MStsAuth "Serial Data 186 : Short Range Radar Right Rear Object Detection and Processing Vehicle Object Track 4 Measurement Status";
BA_ "SignalType" SG_ 120 SRRRRODPVOTk4TypCnfdAuth "ENM";
BA_ "SignalLongName" SG_ 120 SRRRRODPVOTk4TypCnfdAuth "Serial Data 186 : Short Range Radar Right Rear Object Detection and Processing Vehicle Object Track 4 Type Confidence";
BA_ "SignalType" SG_ 120 SRRRRODPVOTk5CnfdStsAuth "ENM";
BA_ "SignalLongName" SG_ 120 SRRRRODPVOTk5CnfdStsAuth "Serial Data 186 : Short Range Radar Right Rear Object Detection and Processing Vehicle Object Track 5 Confidence Status";
BA_ "SignalType" SG_ 120 SRRRRODPVOTk5MStsAuth "ENM";
BA_ "SignalLongName" SG_ 120 SRRRRODPVOTk5MStsAuth "Serial Data 186 : Short Range Radar Right Rear Object Detection and Processing Vehicle Object Track 5 Measurement Status";
BA_ "SignalType" SG_ 120 SRRRRODPVOTk5TypCnfdAuth "ENM";
BA_ "SignalLongName" SG_ 120 SRRRRODPVOTk5TypCnfdAuth "Serial Data 186 : Short Range Radar Right Rear Object Detection and Processing Vehicle Object Track 5 Type Confidence";
BA_ "SignalType" SG_ 120 SRRRRODPVOTk6CnfdStsAuth "ENM";
BA_ "SignalLongName" SG_ 120 SRRRRODPVOTk6CnfdStsAuth "Serial Data 186 : Short Range Radar Right Rear Object Detection and Processing Vehicle Object Track 6 Confidence Status";
BA_ "SignalType" SG_ 120 SRRRRODPVOTk6MStsAuth "ENM";
BA_ "SignalLongName" SG_ 120 SRRRRODPVOTk6MStsAuth "Serial Data 186 : Short Range Radar Right Rear Object Detection and Processing Vehicle Object Track 6 Measurement Status";
BA_ "SignalType" SG_ 120 SRRRRODPVOTk6TypCnfdAuth "ENM";
BA_ "SignalLongName" SG_ 120 SRRRRODPVOTk6TypCnfdAuth "Serial Data 186 : Short Range Radar Right Rear Object Detection and Processing Vehicle Object Track 6 Type Confidence";
BA_ "SignalType" SG_ 120 SRRRRODPVOTk7CnfdStsAuth "ENM";
BA_ "SignalLongName" SG_ 120 SRRRRODPVOTk7CnfdStsAuth "Serial Data 186 : Short Range Radar Right Rear Object Detection and Processing Vehicle Object Track 7 Confidence Status";
BA_ "SignalType" SG_ 120 SRRRRODPVOTk7MStsAuth "ENM";
BA_ "SignalLongName" SG_ 120 SRRRRODPVOTk7MStsAuth "Serial Data 186 : Short Range Radar Right Rear Object Detection and Processing Vehicle Object Track 7 Measurement Status";
BA_ "SignalType" SG_ 120 SRRRRODPVOTk7TypCnfdAuth "ENM";
BA_ "SignalLongName" SG_ 120 SRRRRODPVOTk7TypCnfdAuth "Serial Data 186 : Short Range Radar Right Rear Object Detection and Processing Vehicle Object Track 7 Type Confidence";
BA_ "SignalType" SG_ 120 SRRRRODPVOTk8CnfdStsAuth "ENM";
BA_ "SignalLongName" SG_ 120 SRRRRODPVOTk8CnfdStsAuth "Serial Data 186 : Short Range Radar Right Rear Object Detection and Processing Vehicle Object Track 8 Confidence Status";
BA_ "SignalType" SG_ 120 SRRRRODPVOTk8MStsAuth "ENM";
BA_ "SignalLongName" SG_ 120 SRRRRODPVOTk8MStsAuth "Serial Data 186 : Short Range Radar Right Rear Object Detection and Processing Vehicle Object Track 8 Measurement Status";
BA_ "SignalType" SG_ 120 SRRRRODPVOTk8TypCnfdAuth "ENM";
BA_ "SignalLongName" SG_ 120 SRRRRODPVOTk8TypCnfdAuth "Serial Data 186 : Short Range Radar Right Rear Object Detection and Processing Vehicle Object Track 8 Type Confidence";
BA_ "SignalType" SG_ 120 SRRRRODPVOTk9CnfdStsAuth "ENM";
BA_ "SignalLongName" SG_ 120 SRRRRODPVOTk9CnfdStsAuth "Serial Data 186 : Short Range Radar Right Rear Object Detection and Processing Vehicle Object Track 9 Confidence Status";
BA_ "SignalType" SG_ 120 SRRRRODPVOTk9MStsAuth "ENM";
BA_ "SignalLongName" SG_ 120 SRRRRODPVOTk9MStsAuth "Serial Data 186 : Short Range Radar Right Rear Object Detection and Processing Vehicle Object Track 9 Measurement Status";
BA_ "SignalType" SG_ 120 SRRRRODPVOTk9TypCnfdAuth "ENM";
BA_ "SignalLongName" SG_ 120 SRRRRODPVOTk9TypCnfdAuth "Serial Data 186 : Short Range Radar Right Rear Object Detection and Processing Vehicle Object Track 9 Type Confidence";
BA_ "SignalType" SG_ 120 SRRRRODPAcqTmStmAuth_Inv "ENM";
BA_ "SignalLongName" SG_ 120 SRRRRODPAcqTmStmAuth_Inv "Serial Data 186 : Short Range Radar Right Rear Object Detection and Processing Acquisition Time Stamp Invalid";
BA_ "SignalType" SG_ 120 SRRRRODPServRqrdAuth "ENM";
BA_ "SignalLongName" SG_ 120 SRRRRODPServRqrdAuth "Serial Data 186 : Short Range Radar Right Rear Object Detection and Processing Service Required";
BA_ "SignalType" SG_ 120 SRRRRODPSnsrBlckdAuth "ENM";
BA_ "SignalLongName" SG_ 120 SRRRRODPSnsrBlckdAuth "Serial Data 186 : Short Range Radar Right Rear Object Detection and Processing Sensor Blocked";
BA_ "SignalType" SG_ 120 SRRRRODPSnsrUnvAuth "ENM";
BA_ "SignalLongName" SG_ 120 SRRRRODPSnsrUnvAuth "Serial Data 186 : Short Range Radar Right Rear Object Detection and Processing Sensor Unavailable";
BA_ "SignalType" SG_ 120 SRRRRODPVOTk10DynPrpStsAuth "ENM";
BA_ "SignalLongName" SG_ 120 SRRRRODPVOTk10DynPrpStsAuth "Serial Data 186 : Short Range Radar Right Rear Object Detection and Processing Vehicle Object Track 10 Dynamic Property Status";
BA_ "SignalType" SG_ 120 SRRRRODPVOTk1DynPrpStsAuth "ENM";
BA_ "SignalLongName" SG_ 120 SRRRRODPVOTk1DynPrpStsAuth "Serial Data 186 : Short Range Radar Right Rear Object Detection and Processing Vehicle Object Track 1 Dynamic Property Status";
BA_ "SignalType" SG_ 120 SRRRRODPVOTk2DynPrpStsAuth "ENM";
BA_ "SignalLongName" SG_ 120 SRRRRODPVOTk2DynPrpStsAuth "Serial Data 186 : Short Range Radar Right Rear Object Detection and Processing Vehicle Object Track 2 Dynamic Property Status";
BA_ "SignalType" SG_ 120 SRRRRODPVOTk3DynPrpStsAuth "ENM";
BA_ "SignalLongName" SG_ 120 SRRRRODPVOTk3DynPrpStsAuth "Serial Data 186 : Short Range Radar Right Rear Object Detection and Processing Vehicle Object Track 3 Dynamic Property Status";
BA_ "SignalType" SG_ 120 SRRRRODPVOTk4DynPrpStsAuth "ENM";
BA_ "SignalLongName" SG_ 120 SRRRRODPVOTk4DynPrpStsAuth "Serial Data 186 : Short Range Radar Right Rear Object Detection and Processing Vehicle Object Track 4 Dynamic Property Status";
BA_ "SignalType" SG_ 120 SRRRRODPVOTk5DynPrpStsAuth "ENM";
BA_ "SignalLongName" SG_ 120 SRRRRODPVOTk5DynPrpStsAuth "Serial Data 186 : Short Range Radar Right Rear Object Detection and Processing Vehicle Object Track 5 Dynamic Property Status";
BA_ "SignalType" SG_ 120 SRRRRODPVOTk6DynPrpStsAuth "ENM";
BA_ "SignalLongName" SG_ 120 SRRRRODPVOTk6DynPrpStsAuth "Serial Data 186 : Short Range Radar Right Rear Object Detection and Processing Vehicle Object Track 6 Dynamic Property Status";
BA_ "SignalType" SG_ 120 SRRRRODPVOTk7DynPrpStsAuth "ENM";
BA_ "SignalLongName" SG_ 120 SRRRRODPVOTk7DynPrpStsAuth "Serial Data 186 : Short Range Radar Right Rear Object Detection and Processing Vehicle Object Track 7 Dynamic Property Status";
BA_ "SignalType" SG_ 120 SRRRRODPVOTk8DynPrpStsAuth "ENM";
BA_ "SignalLongName" SG_ 120 SRRRRODPVOTk8DynPrpStsAuth "Serial Data 186 : Short Range Radar Right Rear Object Detection and Processing Vehicle Object Track 8 Dynamic Property Status";
BA_ "SignalType" SG_ 120 SRRRRODPVOTk9DynPrpStsAuth "ENM";
BA_ "SignalLongName" SG_ 120 SRRRRODPVOTk9DynPrpStsAuth "Serial Data 186 : Short Range Radar Right Rear Object Detection and Processing Vehicle Object Track 9 Dynamic Property Status";
BA_ "SignalLongName" SG_ 120 SD186BG1P_ARC "Serial Data 186 : Alive Rolling Count";
BA_ "SignalLongName" SG_ 674 TrnsEstGr_PCSM "Transmission Estimated Gear Protected Counter Sync Message";
BA_ "SignalLongName" SG_ 50 TEGP_MAC "Transmission Estimated Gear Protected : MAC";
BA_ "SignalLongName" SG_ 50 TEGP_FCnt "Transmission Estimated Gear Protected : Freshness Counter";
BA_ "SignalType" SG_ 50 TEGP_TrnsEstGrAuth "ENM";
BA_ "SignalLongName" SG_ 50 TEGP_TrnsEstGrAuth "Transmission Estimated Gear Protected : Transmission Estimated Gear Authenticated";
BA_ "SignalType" SG_ 50 TEGP_TrnsEngdStAuth_Inv "ENM";
BA_ "SignalLongName" SG_ 50 TEGP_TrnsEngdStAuth_Inv "Transmission Estimated Gear Protected : Transmission Engaged State Authenticated Invalid";
BA_ "SignalType" SG_ 50 TEGP_TrnsEngdStAuth "ENM";
BA_ "SignalLongName" SG_ 50 TEGP_TrnsEngdStAuth "Transmission Estimated Gear Protected : Transmission Engaged State Authenticated";
BA_ "SignalType" SG_ 50 TEGP_TransCmndGrAuth "ENM";
BA_ "SignalLongName" SG_ 50 TEGP_TransCmndGrAuth "Transmission Estimated Gear Protected : Transmission Commanded Gear Authenticated";
BA_ "SignalType" SG_ 50 TEGP_TrnsShftLvrPstnAuth "ENM";
BA_ "SignalLongName" SG_ 50 TEGP_TrnsShftLvrPstnAuth "Transmission Estimated Gear Protected : Transmission Shift Lever Position Authenticated";
BA_ "SignalType" SG_ 50 TEGP_TrnsEstGrAuth_Inv "ENM";
BA_ "SignalLongName" SG_ 50 TEGP_TrnsEstGrAuth_Inv "Transmission Estimated Gear Protected : Transmission Estimated Gear Authenticated Invalid";
BA_ "SignalLongName" SG_ 50 TEGP_Filler "Transmission Estimated Gear Protected : Filler";
BA_ "SignalType" SG_ 50 DrvMtrInvrtUntAShtdnCmnd "ENM";
BA_ "SignalLongName" SG_ 50 DrvMtrInvrtUntAShtdnCmnd "Transmission Estimated Gear Protected : Drive Motor Inverter Unit A Shutdown Commanded";
BA_ "SignalLongName" SG_ 50 TEGP_ARC "Transmission Estimated Gear Protected : Alive Rolling Count";
BA_ "SignalType" SG_ 50 TEGP_TrnsShftLvrPstnAuth_Inv "ENM";
BA_ "SignalLongName" SG_ 50 TEGP_TrnsShftLvrPstnAuth_Inv "Transmission Estimated Gear Protected : Transmission Shift Lever Position Authenticated Invalid";
BA_ "SignalType" SG_ 2147745828 UPM_CAN_8_ClscCANHrtBtActv "ENM";
BA_ "SignalLongName" SG_ 2147745828 UPM_CAN_8_ClscCANHrtBtActv "UPM CAN 8 Classic CAN Heart Beat Active";
BA_ "SignalLongName" SG_ 1442 VehIdNmDig10_17 "Vehicle Identification Number Digits 10-17";
BA_ "SignalLongName" SG_ 1443 VehIdNmDig2_9 "Vehicle Identification Number Digits 2-9";
BA_ "SignalLongName" SG_ 1402 VehSpdAvgDrvn_PCSM "Vehicle Speed Average Driven Protected Counter Sync Message";
BA_ "SignalLongName" SG_ 614 VSADP_MAC "Vehicle Speed Average Driven Protected : MAC";
BA_ "SignalLongName" SG_ 614 VSADP_FCnt "Vehicle Speed Average Driven Protected : Freshness Counter";
BA_ "SignalLongName" SG_ 614 VSADP_VehSpdAvgDrvnAuth "Vehicle Speed Average Driven Protected : Vehicle Speed Average Driven Authenticated";
BA_ "SignalType" SG_ 614 VSADP_RdcdPwrIndOnAuth "ENM";
BA_ "SignalLongName" SG_ 614 VSADP_RdcdPwrIndOnAuth "Vehicle Speed Average Driven Protected : Reduced Power Indication On Authenticated";
BA_ "SignalType" SG_ 614 VSADP_FuelModeStsAuth "ENM";
BA_ "SignalLongName" SG_ 614 VSADP_FuelModeStsAuth "Vehicle Speed Average Driven Protected : Fuel Mode Status Authenticated";
BA_ "SignalType" SG_ 614 EngEmsRltMlfIndRq "ENM";
BA_ "SignalLongName" SG_ 614 EngEmsRltMlfIndRq "Vehicle Speed Average Driven Protected : Engine Emissions Related Malfunction Indication Request";
BA_ "SignalLongName" SG_ 614 VSADP_ARC "Vehicle Speed Average Driven Protected : Alive Rolling Count";
BA_ "SignalType" SG_ 614 VSADP_VehSpdAvgDrvnSrcAuth "ENM";
BA_ "SignalLongName" SG_ 614 VSADP_VehSpdAvgDrvnSrcAuth "Vehicle Speed Average Driven Protected : Vehicle Speed Average Driven Source Authenticated";
BA_ "SignalType" SG_ 614 VSADP_VehSpdAvgDrvnAuth_Inv "ENM";
BA_ "SignalLongName" SG_ 614 VSADP_VehSpdAvgDrvnAuth_Inv "Vehicle Speed Average Driven Protected : Vehicle Speed Average Driven Authenticated Invalid";
BA_ "SignalLongName" SG_ 614 VSADP_Filler "Vehicle Speed Average Driven Protected : Filler";
VAL_ 120 SRRRRODPIOTk10TypAuth 0 "Unknown" 1 "Guard Rail" 2 "Tunnel" 3 "Traffic Sign" 4 "Bridge" 5 "Pole" ;
VAL_ 120 SRRRRODPIOTk1TypAuth 0 "Unknown" 1 "Guard Rail" 2 "Tunnel" 3 "Traffic Sign" 4 "Bridge" 5 "Pole" ;
VAL_ 120 SRRRRODPIOTk2TypAuth 0 "Unknown" 1 "Guard Rail" 2 "Tunnel" 3 "Traffic Sign" 4 "Bridge" 5 "Pole" ;
VAL_ 120 SRRRRODPIOTk3TypAuth 0 "Unknown" 1 "Guard Rail" 2 "Tunnel" 3 "Traffic Sign" 4 "Bridge" 5 "Pole" ;
VAL_ 120 SRRRRODPIOTk4TypAuth 0 "Unknown" 1 "Guard Rail" 2 "Tunnel" 3 "Traffic Sign" 4 "Bridge" 5 "Pole" ;
VAL_ 120 SRRRRODPIOTk5TypAuth 0 "Unknown" 1 "Guard Rail" 2 "Tunnel" 3 "Traffic Sign" 4 "Bridge" 5 "Pole" ;
VAL_ 120 SRRRRODPIOTk6TypAuth 0 "Unknown" 1 "Guard Rail" 2 "Tunnel" 3 "Traffic Sign" 4 "Bridge" 5 "Pole" ;
VAL_ 120 SRRRRODPIOTk7TypAuth 0 "Unknown" 1 "Guard Rail" 2 "Tunnel" 3 "Traffic Sign" 4 "Bridge" 5 "Pole" ;
VAL_ 120 SRRRRODPIOTk8TypAuth 0 "Unknown" 1 "Guard Rail" 2 "Tunnel" 3 "Traffic Sign" 4 "Bridge" 5 "Pole" ;
VAL_ 120 SRRRRODPIOTk9TypAuth 0 "Unknown" 1 "Guard Rail" 2 "Tunnel" 3 "Traffic Sign" 4 "Bridge" 5 "Pole" ;
VAL_ 120 SRRRRODPPOTk1DynPrpAuth 0 "Has Never Moved" 1 "Has Moved But Currently Stopped" 2 "Moving In Same Direction As Host" 3 "Moving In Opposite Direction As Host" 4 "Crossing Path" ;
VAL_ 120 SRRRRODPPOTk2DynPrpAuth 0 "Has Never Moved" 1 "Has Moved But Currently Stopped" 2 "Moving In Same Direction As Host" 3 "Moving In Opposite Direction As Host" 4 "Crossing Path" ;
VAL_ 120 SRRRRODPPOTk3DynPrpAuth 0 "Has Never Moved" 1 "Has Moved But Currently Stopped" 2 "Moving In Same Direction As Host" 3 "Moving In Opposite Direction As Host" 4 "Crossing Path" ;
VAL_ 120 SRRRRODPPOTk4DynPrpAuth 0 "Has Never Moved" 1 "Has Moved But Currently Stopped" 2 "Moving In Same Direction As Host" 3 "Moving In Opposite Direction As Host" 4 "Crossing Path" ;
VAL_ 120 SRRRRODPPOTk5DynPrpAuth 0 "Has Never Moved" 1 "Has Moved But Currently Stopped" 2 "Moving In Same Direction As Host" 3 "Moving In Opposite Direction As Host" 4 "Crossing Path" ;
VAL_ 120 SRRRRODPREOTk1TypAuth 0 "Unknown" 1 "Barriers" 2 "Guard Rails" 3 "Bridge Abutments" 4 "Edge of Road" 5 "Open Area" ;
VAL_ 120 SRRRRODPREOTk2TypAuth 0 "Unknown" 1 "Barriers" 2 "Guard Rails" 3 "Bridge Abutments" 4 "Edge of Road" 5 "Open Area" ;
VAL_ 120 SRRRRODPREOTk3TypAuth 0 "Unknown" 1 "Barriers" 2 "Guard Rails" 3 "Bridge Abutments" 4 "Edge of Road" 5 "Open Area" ;
VAL_ 120 SRRRRODPRdTypAuth 0 "Unknown" 1 "City" 2 "Secondary Road" 3 "Highway" 4 "Construction Zone Entry" 5 "Construction Zone Exit" ;
VAL_ 120 SRRRRODPVOTk10DynPrpAuth 0 "Has Never Moved" 1 "Moving In Same Direction As Host" 2 "Moving In Opposite Direction As Host" 3 "Crossing From Left To Right" 4 "Crossing From Right To Left" ;
VAL_ 120 SRRRRODPVOTk1DynPrpAuth 0 "Has Never Moved" 1 "Moving In Same Direction As Host" 2 "Moving In Opposite Direction As Host" 3 "Crossing From Left To Right" 4 "Crossing From Right To Left" ;
VAL_ 120 SRRRRODPVOTk2DynPrpAuth 0 "Has Never Moved" 1 "Moving In Same Direction As Host" 2 "Moving In Opposite Direction As Host" 3 "Crossing From Left To Right" 4 "Crossing From Right To Left" ;
VAL_ 120 SRRRRODPVOTk3DynPrpAuth 0 "Has Never Moved" 1 "Moving In Same Direction As Host" 2 "Moving In Opposite Direction As Host" 3 "Crossing From Left To Right" 4 "Crossing From Right To Left" ;
VAL_ 120 SRRRRODPVOTk4DynPrpAuth 0 "Has Never Moved" 1 "Moving In Same Direction As Host" 2 "Moving In Opposite Direction As Host" 3 "Crossing From Left To Right" 4 "Crossing From Right To Left" ;
VAL_ 120 SRRRRODPVOTk5DynPrpAuth 0 "Has Never Moved" 1 "Moving In Same Direction As Host" 2 "Moving In Opposite Direction As Host" 3 "Crossing From Left To Right" 4 "Crossing From Right To Left" ;
VAL_ 120 SRRRRODPVOTk6DynPrpAuth 0 "Has Never Moved" 1 "Moving In Same Direction As Host" 2 "Moving In Opposite Direction As Host" 3 "Crossing From Left To Right" 4 "Crossing From Right To Left" ;
VAL_ 120 SRRRRODPVOTk7DynPrpAuth 0 "Has Never Moved" 1 "Moving In Same Direction As Host" 2 "Moving In Opposite Direction As Host" 3 "Crossing From Left To Right" 4 "Crossing From Right To Left" ;
VAL_ 120 SRRRRODPVOTk8DynPrpAuth 0 "Has Never Moved" 1 "Moving In Same Direction As Host" 2 "Moving In Opposite Direction As Host" 3 "Crossing From Left To Right" 4 "Crossing From Right To Left" ;
VAL_ 120 SRRRRODPVOTk9DynPrpAuth 0 "Has Never Moved" 1 "Moving In Same Direction As Host" 2 "Moving In Opposite Direction As Host" 3 "Crossing From Left To Right" 4 "Crossing From Right To Left" ;
VAL_ 120 SRRRRODPConstrArDtnCnfdAuth 0 "Highly Speculative" 1 "Speculative" 2 "Confident" 3 "Highly Confident" ;
VAL_ 120 SRRRRODPConstrArDtnStsAuth 0 "Not Detected" 1 "Detected" 2 "Unknown" ;
VAL_ 120 SRRRRODPIOTk10CnfdStsAuth 0 "Highly Speculative" 1 "Speculative" 2 "Confident" 3 "Highly Confident" ;
VAL_ 120 SRRRRODPIOTk10ElvtnAuth 0 "Not Elevated" 1 "Elevation Speculative" 2 "Elevation Confident" 3 "Elevation Very Confident" ;
VAL_ 120 SRRRRODPIOTk10MStsAuth 0 "No Object" 1 "New Object" 2 "Latent Track Not Detected this Cycle" 3 "Measured this Cycle" ;
VAL_ 120 SRRRRODPIOTk10TypCnfdAuth 0 "Highly Speculative" 1 "Speculative" 2 "Confident" 3 "Highly Confident" ;
VAL_ 120 SRRRRODPIOTk1CnfdStsAuth 0 "Highly Speculative" 1 "Speculative" 2 "Confident" 3 "Highly Confident" ;
VAL_ 120 SRRRRODPIOTk1ElvtnAuth 0 "Not Elevated" 1 "Elevation Speculative" 2 "Elevation Confident" 3 "Elevation Very Confident" ;
VAL_ 120 SRRRRODPIOTk1MStsAuth 0 "No Object" 1 "New Object" 2 "Latent Track Not Detected this Cycle" 3 "Measured this Cycle" ;
VAL_ 120 SRRRRODPIOTk1TypCnfdAuth 0 "Highly Speculative" 1 "Speculative" 2 "Confident" 3 "Highly Confident" ;
VAL_ 120 SRRRRODPIOTk2CnfdStsAuth 0 "Highly Speculative" 1 "Speculative" 2 "Confident" 3 "Highly Confident" ;
VAL_ 120 SRRRRODPIOTk2ElvtnAuth 0 "Not Elevated" 1 "Elevation Speculative" 2 "Elevation Confident" 3 "Elevation Very Confident" ;
VAL_ 120 SRRRRODPIOTk2MStsAuth 0 "No Object" 1 "New Object" 2 "Latent Track Not Detected this Cycle" 3 "Measured this Cycle" ;
VAL_ 120 SRRRRODPIOTk2TypCnfdAuth 0 "Highly Speculative" 1 "Speculative" 2 "Confident" 3 "Highly Confident" ;
VAL_ 120 SRRRRODPIOTk3CnfdStsAuth 0 "Highly Speculative" 1 "Speculative" 2 "Confident" 3 "Highly Confident" ;
VAL_ 120 SRRRRODPIOTk3ElvtnAuth 0 "Not Elevated" 1 "Elevation Speculative" 2 "Elevation Confident" 3 "Elevation Very Confident" ;
VAL_ 120 SRRRRODPIOTk3MStsAuth 0 "No Object" 1 "New Object" 2 "Latent Track Not Detected this Cycle" 3 "Measured this Cycle" ;
VAL_ 120 SRRRRODPIOTk3TypCnfdAuth 0 "Highly Speculative" 1 "Speculative" 2 "Confident" 3 "Highly Confident" ;
VAL_ 120 SRRRRODPIOTk4CnfdStsAuth 0 "Highly Speculative" 1 "Speculative" 2 "Confident" 3 "Highly Confident" ;
VAL_ 120 SRRRRODPIOTk4ElvtnAuth 0 "Not Elevated" 1 "Elevation Speculative" 2 "Elevation Confident" 3 "Elevation Very Confident" ;
VAL_ 120 SRRRRODPIOTk4MStsAuth 0 "No Object" 1 "New Object" 2 "Latent Track Not Detected this Cycle" 3 "Measured this Cycle" ;
VAL_ 120 SRRRRODPIOTk4TypCnfdAuth 0 "Highly Speculative" 1 "Speculative" 2 "Confident" 3 "Highly Confident" ;
VAL_ 120 SRRRRODPIOTk5CnfdStsAuth 0 "Highly Speculative" 1 "Speculative" 2 "Confident" 3 "Highly Confident" ;
VAL_ 120 SRRRRODPIOTk5ElvtnAuth 0 "Not Elevated" 1 "Elevation Speculative" 2 "Elevation Confident" 3 "Elevation Very Confident" ;
VAL_ 120 SRRRRODPIOTk5MStsAuth 0 "No Object" 1 "New Object" 2 "Latent Track Not Detected this Cycle" 3 "Measured this Cycle" ;
VAL_ 120 SRRRRODPIOTk5TypCnfdAuth 0 "Highly Speculative" 1 "Speculative" 2 "Confident" 3 "Highly Confident" ;
VAL_ 120 SRRRRODPIOTk6CnfdStsAuth 0 "Highly Speculative" 1 "Speculative" 2 "Confident" 3 "Highly Confident" ;
VAL_ 120 SRRRRODPIOTk6ElvtnAuth 0 "Not Elevated" 1 "Elevation Speculative" 2 "Elevation Confident" 3 "Elevation Very Confident" ;
VAL_ 120 SRRRRODPIOTk6MStsAuth 0 "No Object" 1 "New Object" 2 "Latent Track Not Detected this Cycle" 3 "Measured this Cycle" ;
VAL_ 120 SRRRRODPIOTk6TypCnfdAuth 0 "Highly Speculative" 1 "Speculative" 2 "Confident" 3 "Highly Confident" ;
VAL_ 120 SRRRRODPIOTk7CnfdStsAuth 0 "Highly Speculative" 1 "Speculative" 2 "Confident" 3 "Highly Confident" ;
VAL_ 120 SRRRRODPIOTk7ElvtnAuth 0 "Not Elevated" 1 "Elevation Speculative" 2 "Elevation Confident" 3 "Elevation Very Confident" ;
VAL_ 120 SRRRRODPIOTk7MStsAuth 0 "No Object" 1 "New Object" 2 "Latent Track Not Detected this Cycle" 3 "Measured this Cycle" ;
VAL_ 120 SRRRRODPIOTk7TypCnfdAuth 0 "Highly Speculative" 1 "Speculative" 2 "Confident" 3 "Highly Confident" ;
VAL_ 120 SRRRRODPIOTk8CnfdStsAuth 0 "Highly Speculative" 1 "Speculative" 2 "Confident" 3 "Highly Confident" ;
VAL_ 120 SRRRRODPIOTk8ElvtnAuth 0 "Not Elevated" 1 "Elevation Speculative" 2 "Elevation Confident" 3 "Elevation Very Confident" ;
VAL_ 120 SRRRRODPIOTk8MStsAuth 0 "No Object" 1 "New Object" 2 "Latent Track Not Detected this Cycle" 3 "Measured this Cycle" ;
VAL_ 120 SRRRRODPIOTk8TypCnfdAuth 0 "Highly Speculative" 1 "Speculative" 2 "Confident" 3 "Highly Confident" ;
VAL_ 120 SRRRRODPIOTk9CnfdStsAuth 0 "Highly Speculative" 1 "Speculative" 2 "Confident" 3 "Highly Confident" ;
VAL_ 120 SRRRRODPIOTk9ElvtnAuth 0 "Not Elevated" 1 "Elevation Speculative" 2 "Elevation Confident" 3 "Elevation Very Confident" ;
VAL_ 120 SRRRRODPIOTk9MStsAuth 0 "No Object" 1 "New Object" 2 "Latent Track Not Detected this Cycle" 3 "Measured this Cycle" ;
VAL_ 120 SRRRRODPIOTk9TypCnfdAuth 0 "Highly Speculative" 1 "Speculative" 2 "Confident" 3 "Highly Confident" ;
VAL_ 120 SRRRRODPMdCmdStsAuth 0 "Not Radiating" 1 "Reporting Object Data" 2 "Not Reporting Object Data" ;
VAL_ 120 SRRRRODPPOTk1CnfdStsAuth 0 "Highly Speculative" 1 "Speculative" 2 "Confident" 3 "Highly Confident" ;
VAL_ 120 SRRRRODPPOTk1MStsAuth 0 "No Object" 1 "New Object" 2 "Latent Track Not Detected this Cycle" 3 "Measured this Cycle" ;
VAL_ 120 SRRRRODPPOTk1TypAuth 0 "Unknown" 1 "Pedestrian" 2 "Bicycle" ;
VAL_ 120 SRRRRODPPOTk1TypCnfdAuth 0 "Highly Speculative" 1 "Speculative" 2 "Confident" 3 "Highly Confident" ;
VAL_ 120 SRRRRODPPOTk2CnfdStsAuth 0 "Highly Speculative" 1 "Speculative" 2 "Confident" 3 "Highly Confident" ;
VAL_ 120 SRRRRODPPOTk2MStsAuth 0 "No Object" 1 "New Object" 2 "Latent Track Not Detected this Cycle" 3 "Measured this Cycle" ;
VAL_ 120 SRRRRODPPOTk2TypAuth 0 "Unknown" 1 "Pedestrian" 2 "Bicycle" ;
VAL_ 120 SRRRRODPPOTk2TypCnfdAuth 0 "Highly Speculative" 1 "Speculative" 2 "Confident" 3 "Highly Confident" ;
VAL_ 120 SRRRRODPPOTk3CnfdStsAuth 0 "Highly Speculative" 1 "Speculative" 2 "Confident" 3 "Highly Confident" ;
VAL_ 120 SRRRRODPPOTk3MStsAuth 0 "No Object" 1 "New Object" 2 "Latent Track Not Detected this Cycle" 3 "Measured this Cycle" ;
VAL_ 120 SRRRRODPPOTk3TypAuth 0 "Unknown" 1 "Pedestrian" 2 "Bicycle" ;
VAL_ 120 SRRRRODPPOTk3TypCnfdAuth 0 "Highly Speculative" 1 "Speculative" 2 "Confident" 3 "Highly Confident" ;
VAL_ 120 SRRRRODPPOTk4CnfdStsAuth 0 "Highly Speculative" 1 "Speculative" 2 "Confident" 3 "Highly Confident" ;
VAL_ 120 SRRRRODPPOTk4MStsAuth 0 "No Object" 1 "New Object" 2 "Latent Track Not Detected this Cycle" 3 "Measured this Cycle" ;
VAL_ 120 SRRRRODPPOTk4TypAuth 0 "Unknown" 1 "Pedestrian" 2 "Bicycle" ;
VAL_ 120 SRRRRODPPOTk4TypCnfdAuth 0 "Highly Speculative" 1 "Speculative" 2 "Confident" 3 "Highly Confident" ;
VAL_ 120 SRRRRODPPOTk5CnfdStsAuth 0 "Highly Speculative" 1 "Speculative" 2 "Confident" 3 "Highly Confident" ;
VAL_ 120 SRRRRODPPOTk5MStsAuth 0 "No Object" 1 "New Object" 2 "Latent Track Not Detected this Cycle" 3 "Measured this Cycle" ;
VAL_ 120 SRRRRODPPOTk5TypAuth 0 "Unknown" 1 "Pedestrian" 2 "Bicycle" ;
VAL_ 120 SRRRRODPPOTk5TypCnfdAuth 0 "Highly Speculative" 1 "Speculative" 2 "Confident" 3 "Highly Confident" ;
VAL_ 120 SRRRRODPREOTk1CnfdStsAuth 0 "Highly Speculative" 1 "Speculative" 2 "Confident" 3 "Highly Confident" ;
VAL_ 120 SRRRRODPREOTk1TypCnfdAuth 0 "Highly Speculative" 1 "Speculative" 2 "Confident" 3 "Highly Confident" ;
VAL_ 120 SRRRRODPREOTk2CnfdStsAuth 0 "Highly Speculative" 1 "Speculative" 2 "Confident" 3 "Highly Confident" ;
VAL_ 120 SRRRRODPREOTk2TypCnfdAuth 0 "Highly Speculative" 1 "Speculative" 2 "Confident" 3 "Highly Confident" ;
VAL_ 120 SRRRRODPREOTk3CnfdStsAuth 0 "Highly Speculative" 1 "Speculative" 2 "Confident" 3 "Highly Confident" ;
VAL_ 120 SRRRRODPREOTk3TypCnfdAuth 0 "Highly Speculative" 1 "Speculative" 2 "Confident" 3 "Highly Confident" ;
VAL_ 120 SRRRRODPRdTypCnfdAuth 0 "Highly Speculative" 1 "Speculative" 2 "Confident" 3 "Highly Confident" ;
VAL_ 120 SRRRRODPSwpBndwdthStsAuth 0 "Mode A" 1 "Mode B" 2 "Mode C" 3 "Mode D" ;
VAL_ 120 SRRRRODPVOTk10CnfdStsAuth 0 "Highly Speculative" 1 "Speculative" 2 "Confident" 3 "Highly Confident" ;
VAL_ 120 SRRRRODPVOTk10MStsAuth 0 "No Object" 1 "New Object" 2 "Latent Track Not Detected this Cycle" 3 "Measured this Cycle" ;
VAL_ 120 SRRRRODPVOTk10TypCnfdAuth 0 "Highly Speculative" 1 "Speculative" 2 "Confident" 3 "Highly Confident" ;
VAL_ 120 SRRRRODPVOTk1CnfdStsAuth 0 "Highly Speculative" 1 "Speculative" 2 "Confident" 3 "Highly Confident" ;
VAL_ 120 SRRRRODPVOTk1MStsAuth 0 "No Object" 1 "New Object" 2 "Latent Track Not Detected this Cycle" 3 "Measured this Cycle" ;
VAL_ 120 SRRRRODPVOTk1TypCnfdAuth 0 "Highly Speculative" 1 "Speculative" 2 "Confident" 3 "Highly Confident" ;
VAL_ 120 SRRRRODPVOTk2CnfdStsAuth 0 "Highly Speculative" 1 "Speculative" 2 "Confident" 3 "Highly Confident" ;
VAL_ 120 SRRRRODPVOTk2MStsAuth 0 "No Object" 1 "New Object" 2 "Latent Track Not Detected this Cycle" 3 "Measured this Cycle" ;
VAL_ 120 SRRRRODPVOTk2TypCnfdAuth 0 "Highly Speculative" 1 "Speculative" 2 "Confident" 3 "Highly Confident" ;
VAL_ 120 SRRRRODPVOTk3CnfdStsAuth 0 "Highly Speculative" 1 "Speculative" 2 "Confident" 3 "Highly Confident" ;
VAL_ 120 SRRRRODPVOTk3MStsAuth 0 "No Object" 1 "New Object" 2 "Latent Track Not Detected this Cycle" 3 "Measured this Cycle" ;
VAL_ 120 SRRRRODPVOTk3TypCnfdAuth 0 "Highly Speculative" 1 "Speculative" 2 "Confident" 3 "Highly Confident" ;
VAL_ 120 SRRRRODPVOTk4CnfdStsAuth 0 "Highly Speculative" 1 "Speculative" 2 "Confident" 3 "Highly Confident" ;
VAL_ 120 SRRRRODPVOTk4MStsAuth 0 "No Object" 1 "New Object" 2 "Latent Track Not Detected this Cycle" 3 "Measured this Cycle" ;
VAL_ 120 SRRRRODPVOTk4TypCnfdAuth 0 "Highly Speculative" 1 "Speculative" 2 "Confident" 3 "Highly Confident" ;
VAL_ 120 SRRRRODPVOTk5CnfdStsAuth 0 "Highly Speculative" 1 "Speculative" 2 "Confident" 3 "Highly Confident" ;
VAL_ 120 SRRRRODPVOTk5MStsAuth 0 "No Object" 1 "New Object" 2 "Latent Track Not Detected this Cycle" 3 "Measured this Cycle" ;
VAL_ 120 SRRRRODPVOTk5TypCnfdAuth 0 "Highly Speculative" 1 "Speculative" 2 "Confident" 3 "Highly Confident" ;
VAL_ 120 SRRRRODPVOTk6CnfdStsAuth 0 "Highly Speculative" 1 "Speculative" 2 "Confident" 3 "Highly Confident" ;
VAL_ 120 SRRRRODPVOTk6MStsAuth 0 "No Object" 1 "New Object" 2 "Latent Track Not Detected this Cycle" 3 "Measured this Cycle" ;
VAL_ 120 SRRRRODPVOTk6TypCnfdAuth 0 "Highly Speculative" 1 "Speculative" 2 "Confident" 3 "Highly Confident" ;
VAL_ 120 SRRRRODPVOTk7CnfdStsAuth 0 "Highly Speculative" 1 "Speculative" 2 "Confident" 3 "Highly Confident" ;
VAL_ 120 SRRRRODPVOTk7MStsAuth 0 "No Object" 1 "New Object" 2 "Latent Track Not Detected this Cycle" 3 "Measured this Cycle" ;
VAL_ 120 SRRRRODPVOTk7TypCnfdAuth 0 "Highly Speculative" 1 "Speculative" 2 "Confident" 3 "Highly Confident" ;
VAL_ 120 SRRRRODPVOTk8CnfdStsAuth 0 "Highly Speculative" 1 "Speculative" 2 "Confident" 3 "Highly Confident" ;
VAL_ 120 SRRRRODPVOTk8MStsAuth 0 "No Object" 1 "New Object" 2 "Latent Track Not Detected this Cycle" 3 "Measured this Cycle" ;
VAL_ 120 SRRRRODPVOTk8TypCnfdAuth 0 "Highly Speculative" 1 "Speculative" 2 "Confident" 3 "Highly Confident" ;
VAL_ 120 SRRRRODPVOTk9CnfdStsAuth 0 "Highly Speculative" 1 "Speculative" 2 "Confident" 3 "Highly Confident" ;
VAL_ 120 SRRRRODPVOTk9MStsAuth 0 "No Object" 1 "New Object" 2 "Latent Track Not Detected this Cycle" 3 "Measured this Cycle" ;
VAL_ 120 SRRRRODPVOTk9TypCnfdAuth 0 "Highly Speculative" 1 "Speculative" 2 "Confident" 3 "Highly Confident" ;
VAL_ 120 SRRRRODPAcqTmStmAuth_Inv 0 "FALSE" 1 "TRUE" ;
VAL_ 120 SRRRRODPServRqrdAuth 0 "FALSE" 1 "TRUE" ;
VAL_ 120 SRRRRODPSnsrBlckdAuth 0 "FALSE" 1 "TRUE" ;
VAL_ 120 SRRRRODPSnsrUnvAuth 0 "FALSE" 1 "TRUE" ;
VAL_ 120 SRRRRODPVOTk10DynPrpStsAuth 0 "Stopped" 1 "Not Stopped" ;
VAL_ 120 SRRRRODPVOTk1DynPrpStsAuth 0 "Stopped" 1 "Not Stopped" ;
VAL_ 120 SRRRRODPVOTk2DynPrpStsAuth 0 "Stopped" 1 "Not Stopped" ;
VAL_ 120 SRRRRODPVOTk3DynPrpStsAuth 0 "Stopped" 1 "Not Stopped" ;
VAL_ 120 SRRRRODPVOTk4DynPrpStsAuth 0 "Stopped" 1 "Not Stopped" ;
VAL_ 120 SRRRRODPVOTk5DynPrpStsAuth 0 "Stopped" 1 "Not Stopped" ;
VAL_ 120 SRRRRODPVOTk6DynPrpStsAuth 0 "Stopped" 1 "Not Stopped" ;
VAL_ 120 SRRRRODPVOTk7DynPrpStsAuth 0 "Stopped" 1 "Not Stopped" ;
VAL_ 120 SRRRRODPVOTk8DynPrpStsAuth 0 "Stopped" 1 "Not Stopped" ;
VAL_ 120 SRRRRODPVOTk9DynPrpStsAuth 0 "Stopped" 1 "Not Stopped" ;
VAL_ 50 TEGP_TrnsEstGrAuth 0 "Not Supported" 1 "First Gear" 2 "Second Gear" 3 "Third Gear" 4 "Fourth Gear" 5 "Fifth Gear" 6 "Sixth Gear" 7 "Seventh Gear" 8 "Eighth Gear" 9 "Ninth Gear" 10 "Tenth Gear" 11 "Unused and Reserved" 12 "CVT Forward Gear" 13 "Neutral Gear" 14 "Reverse Gear" 15 "Park Gear" ;
VAL_ 50 TEGP_TrnsEngdStAuth_Inv 0 "FALSE" 1 "TRUE" ;
VAL_ 50 TEGP_TrnsEngdStAuth 0 "Transmission Not Engaged" 1 "Transmission Engaged in Forward" 2 "Transmission Engaged in Reverse" 3 "Operating State Not Reached" ;
VAL_ 50 TEGP_TransCmndGrAuth 0 "Not Supported" 1 "First Gear" 2 "Second Gear" 3 "Third Gear" 4 "Fourth Gear" 5 "Fifth Gear" 6 "Sixth Gear" 7 "Seventh Gear" 8 "Eighth Gear" 9 "Ninth Gear" 10 "Tenth Gear" 11 "Unused and Reserved" 12 "CVT Forward Gear" 13 "Neutral Gear" 14 "Reverse Gear" 15 "Park Gear" ;
VAL_ 50 TEGP_TrnsShftLvrPstnAuth 0 "Between Ranges" 1 "Park Range" 2 "Reverse Range" 3 "Neutral Range" 4 "Forward Range A" 5 "Forward Range B" 6 "Forward Range C" 7 "Forward Range D" 8 "Forward Range E" 9 "Forward Range F" 10 "Forward Range G" 11 "Forward Range H" 12 "Forward Range I" 13 "Forward Range J" 14 "Lever Position Unknown" ;
VAL_ 50 TEGP_TrnsEstGrAuth_Inv 0 "FALSE" 1 "TRUE" ;
VAL_ 50 DrvMtrInvrtUntAShtdnCmnd 0 "FALSE" 1 "TRUE" ;
VAL_ 50 TEGP_TrnsShftLvrPstnAuth_Inv 0 "FALSE" 1 "TRUE" ;
VAL_ 2147745828 UPM_CAN_8_ClscCANHrtBtActv 0 "FALSE" 1 "TRUE" ;
VAL_ 614 VSADP_RdcdPwrIndOnAuth 0 "FALSE" 1 "TRUE" ;
VAL_ 614 VSADP_FuelModeStsAuth 0 "Unknown" 1 "Gasoline Mode" 2 "Natural Gas Mode" 3 "Liquified Petroleum Gas Mode" 4 "Alternative Fuel Cut-off Active" ;
VAL_ 614 EngEmsRltMlfIndRq 0 "Continuous Indication" 1 "No Indication" 2 "Flashing 1 Hertz Indication" 3 "Flashing 2 Hertz Indication" 4 "Flashing 0.5 Hertz Indication" ;
VAL_ 614 VSADP_VehSpdAvgDrvnSrcAuth 0 "Transmission Output Speed" 1 "Wheel Speed" ;
VAL_ 614 VSADP_VehSpdAvgDrvnAuth_Inv 0 "FALSE" 1 "TRUE" ;
